VERSION ""

NS_ :

BS_:

BU_: Vector__XXX

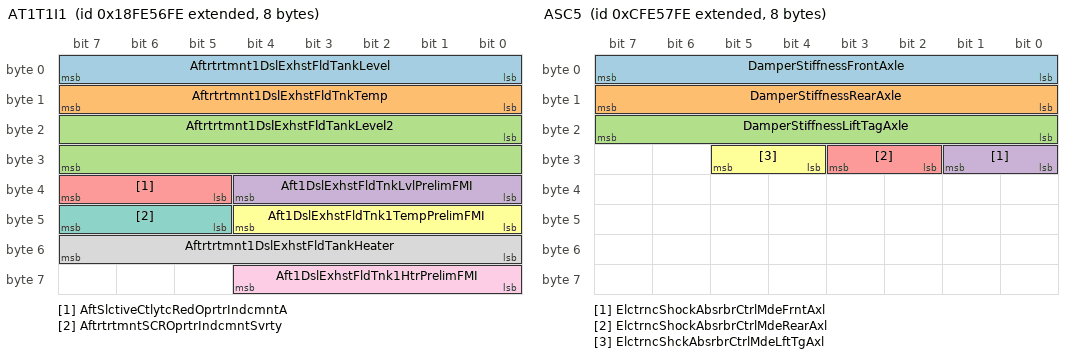
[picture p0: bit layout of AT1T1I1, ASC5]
BO_ 2566805246 AT1T1I1: 8 Vector__XXX
SG_ Aftrtrtmnt1DslExhstFldTankLevel : 0|8@1+ (0.4,0) [0|100] "%" Vector__XXX
SG_ Aftrtrtmnt1DslExhstFldTnkTemp : 8|8@1+ (1,-40) [-40|210] "deg C" Vector__XXX
SG_ Aftrtrtmnt1DslExhstFldTankLevel2 : 16|16@1+ (0.1,0) [0|6425.5] "mm" Vector__XXX
SG_ Aft1DslExhstFldTnkLvlPrelimFMI : 32|5@1+ (1,0) [0|31] "" Vector__XXX
SG_ AftSlctiveCtlytcRedOprtrIndcmntA : 37|3@1+ (1,0) [0|7] "" Vector__XXX
SG_ Aft1DslExhstFldTnk1TempPrelimFMI : 40|5@1+ (1,0) [0|31] "" Vector__XXX
SG_ AftrtrtmntSCROprtrIndcmntSvrty : 45|3@1+ (1,0) [0|7] "" Vector__XXX
SG_ Aftrtrtmnt1DslExhstFldTankHeater : 48|8@1+ (0.4,0) [0|100] "%" Vector__XXX
SG_ Aft1DslExhstFldTnk1HtrPrelimFMI : 56|5@1+ (1,0) [0|31] "" Vector__XXX

BO_ 2365478910 ASC5: 8 Vector__XXX
SG_ DamperStiffnessFrontAxle : 0|8@1+ (0.4,0) [0|100] "%" Vector__XXX
SG_ DamperStiffnessRearAxle : 8|8@1+ (0.4,0) [0|100] "%" Vector__XXX
SG_ DamperStiffnessLiftTagAxle : 16|8@1+ (0.4,0) [0|100] "%" Vector__XXX
SG_ ElctrncShockAbsrbrCtrlMdeFrntAxl : 24|2@1+ (1,0) [0|3] "" Vector__XXX
SG_ ElctrncShockAbsrbrCtrlMdeRearAxl : 26|2@1+ (1,0) [0|3] "" Vector__XXX
SG_ ElctrncShckAbsrbrCtrlMdeLftTgAxl : 28|2@1+ (1,0) [0|3] "" Vector__XXX

BO_ 2566805758 ASC4: 8 Vector__XXX
SG_ BellowPressureFrontAxleLeft : 0|16@1+ (0.1,0) [0|6425.5] "kPa" Vector__XXX
SG_ BellowPressureFrontAxleRight : 16|16@1+ (0.1,0) [0|6425.5] "kPa" Vector__XXX
SG_ BellowPressureRearAxleLeft : 32|16@1+ (0.1,0) [0|6425.5] "kPa" Vector__XXX
SG_ BellowPressureRearAxleRight : 48|16@1+ (0.1,0) [0|6425.5] "kPa" Vector__XXX

BO_ 2566806014 ASC3: 8 Vector__XXX
SG_ RelativeLevelFrontAxleLeft : 0|16@1+ (0.1,-3200) [-3200|3225.5] "mm" Vector__XXX
SG_ RelativeLevelFrontAxleRight : 16|16@1+ (0.1,-3200) [-3200|3225.5] "mm" Vector__XXX
SG_ RelativeLevelRearAxleLeft : 32|16@1+ (0.1,-3200) [-3200|3225.5] "mm" Vector__XXX
SG_ RelativeLevelRearAxleRight : 48|16@1+ (0.1,-3200) [-3200|3225.5] "mm" Vector__XXX

BO_ 2365479678 ASC1: 8 Vector__XXX
SG_ NominalLevelFrontAxle : 0|4@1+ (1,0) [0|15] "" Vector__XXX
SG_ NominalLevelRearAxle : 4|4@1+ (1,0) [0|15] "" Vector__XXX
SG_ BelowNominalLevelFrontAxle : 8|2@1+ (1,0) [0|3] "" Vector__XXX
SG_ BelowNominalLevelRearAxle : 10|2@1+ (1,0) [0|3] "" Vector__XXX
SG_ AboveNominalLevelFrontAxle : 12|2@1+ (1,0) [0|3] "" Vector__XXX
SG_ AboveNominalLevelRearAxle : 14|2@1+ (1,0) [0|3] "" Vector__XXX
SG_ LoweringControlModeFrontAxle : 16|2@1+ (1,0) [0|3] "" Vector__XXX
SG_ LoweringControlModeRearAxle : 18|2@1+ (1,0) [0|3] "" Vector__XXX
SG_ LiftingControlModeFrontAxle : 20|2@1+ (1,0) [0|3] "" Vector__XXX
SG_ LiftingControlModeRearAxle : 22|2@1+ (1,0) [0|3] "" Vector__XXX
SG_ KneelingInformation : 24|4@1+ (1,0) [0|15] "" Vector__XXX
SG_ LevelControlMode : 28|4@1+ (1,0) [0|15] "" Vector__XXX
SG_ SecurityDevice : 32|2@1+ (1,0) [0|3] "" Vector__XXX
SG_ VehicleMotionInhibit : 34|2@1+ (1,0) [0|3] "" Vector__XXX
SG_ DoorRelease : 36|2@1+ (1,0) [0|3] "" Vector__XXX
SG_ LiftAxle1Position : 38|2@1+ (1,0) [0|3] "" Vector__XXX
SG_ FrontAxleInBumperRange : 40|2@1+ (1,0) [0|3] "" Vector__XXX
SG_ RearAxleInBumperRange : 42|2@1+ (1,0) [0|3] "" Vector__XXX
SG_ LiftAxle2Position : 46|2@1+ (1,0) [0|3] "" Vector__XXX
SG_ SuspensionRemoteControl1 : 48|2@1+ (1,0) [0|3] "" Vector__XXX
SG_ SuspensionRemoteControl2 : 50|2@1+ (1,0) [0|3] "" Vector__XXX
SG_ AllowLevelCtrlDuringBrkngStatus : 52|2@1+ (1,0) [0|3] "" Vector__XXX
SG_ SpeedDependantLevelControlStatus : 54|2@1+ (1,0) [0|3] "" Vector__XXX
SG_ SuspensionCtrlRefusalInformation : 56|4@1+ (1,0) [0|15] "" Vector__XXX
SG_ MemoryLevel : 60|4@1+ (1,0) [0|15] "" Vector__XXX

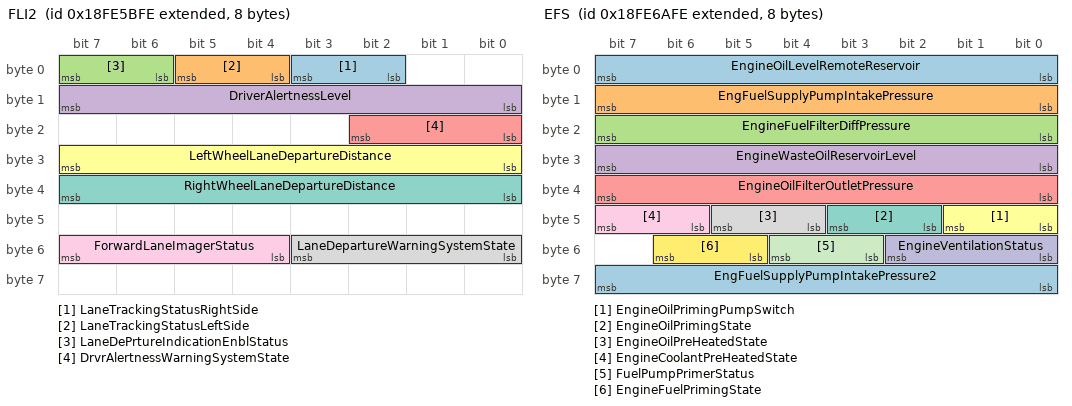
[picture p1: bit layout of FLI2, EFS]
BO_ 2566806526 FLI2: 8 Vector__XXX
SG_ LaneTrackingStatusRightSide : 2|2@1+ (1,0) [0|3] "" Vector__XXX
SG_ LaneTrackingStatusLeftSide : 4|2@1+ (1,0) [0|3] "" Vector__XXX
SG_ LaneDePrtureIndicationEnblStatus : 6|2@1+ (1,0) [0|3] "" Vector__XXX
SG_ DriverAlertnessLevel : 8|8@1+ (0.4,0) [0|100] "%" Vector__XXX
SG_ DrvrAlertnessWarningSystemState : 16|3@1+ (1,0) [0|7] "" Vector__XXX
SG_ LeftWheelLaneDepartureDistance : 24|8@1+ (1,-125) [-125|125] "cm" Vector__XXX
SG_ RightWheelLaneDepartureDistance : 32|8@1+ (1,-125) [-125|125] "cm" Vector__XXX
SG_ LaneDepartureWarningSystemState : 48|4@1+ (1,0) [0|15] "" Vector__XXX
SG_ ForwardLaneImagerStatus : 52|4@1+ (1,0) [0|15] "" Vector__XXX

BO_ 2566809342 BM: 8 Vector__XXX
SG_ BatteryMainSwitchHoldState : 0|2@1+ (1,0) [0|3] "" Vector__XXX

BO_ 2566809598 CCC: 8 Vector__XXX
SG_ AuxHeaterMaximumOutputPower : 0|16@1+ (2,0) [0|128510] "W" Vector__XXX

BO_ 2566809854 VF: 8 Vector__XXX
SG_ HydraulicTemperature : 0|8@1+ (1,-40) [-40|210] "deg C" Vector__XXX
SG_ HydrOilFilterRestrictionSwitch : 8|2@1+ (1,0) [0|3] "" Vector__XXX
SG_ WinchOilPressureSwitch : 10|2@1+ (1,0) [0|3] "" Vector__XXX
SG_ HydraulicOilLevel : 16|8@1+ (0.4,0) [0|100] "%" Vector__XXX

BO_ 2566810110 ET3: 8 Vector__XXX
SG_ EngineIntakeManifold1Temperature : 0|16@1+ (0.03125,-273) [-273|1734.96875] "deg C" Vector__XXX
SG_ EngineCoolantTemperature : 16|16@1+ (0.03125,-273) [-273|1734.96875] "deg C" Vector__XXX
SG_ EngIntkValveActSysOilTemperature : 32|16@1+ (0.03125,-273) [-273|1734.96875] "deg C" Vector__XXX
SG_ EngChargeAirCool1OtltTemperature : 48|16@1+ (0.03125,-273) [-273|1734.96875] "deg C" Vector__XXX

BO_ 2566810366 EFS: 8 Vector__XXX
SG_ EngineOilLevelRemoteReservoir : 0|8@1+ (0.4,0) [0|100] "%" Vector__XXX
SG_ EngFuelSupplyPumpIntakePressure : 8|8@1+ (2,0) [0|500] "kPa" Vector__XXX
SG_ EngineFuelFilterDiffPressure : 16|8@1+ (2,0) [0|500] "kPa" Vector__XXX
SG_ EngineWasteOilReservoirLevel : 24|8@1+ (0.4,0) [0|100] "%" Vector__XXX
SG_ EngineOilFilterOutletPressure : 32|8@1+ (4,0) [0|1000] "kPa" Vector__XXX
SG_ EngineOilPrimingPumpSwitch : 40|2@1+ (1,0) [0|3] "" Vector__XXX
SG_ EngineOilPrimingState : 42|2@1+ (1,0) [0|3] "" Vector__XXX
SG_ EngineOilPreHeatedState : 44|2@1+ (1,0) [0|3] "" Vector__XXX
SG_ EngineCoolantPreHeatedState : 46|2@1+ (1,0) [0|3] "" Vector__XXX
SG_ EngineVentilationStatus : 48|3@1+ (1,0) [0|7] "" Vector__XXX
SG_ FuelPumpPrimerStatus : 51|2@1+ (1,0) [0|3] "" Vector__XXX
SG_ EngineFuelPrimingState : 53|2@1+ (1,0) [0|3] "" Vector__XXX
SG_ EngFuelSupplyPumpIntakePressure2 : 56|8@1+ (2,0) [0|500] "kPa" Vector__XXX

BO_ 2566810622 DI: 1728 Vector__XXX
SG_ Driver1Identification : 7|13824@0+ (1,0) [0|0] "ASCII" Vector__XXX
SG_ Driver2Identification : 7|13824@0+ (1,0) [0|0] "ASCII" Vector__XXX

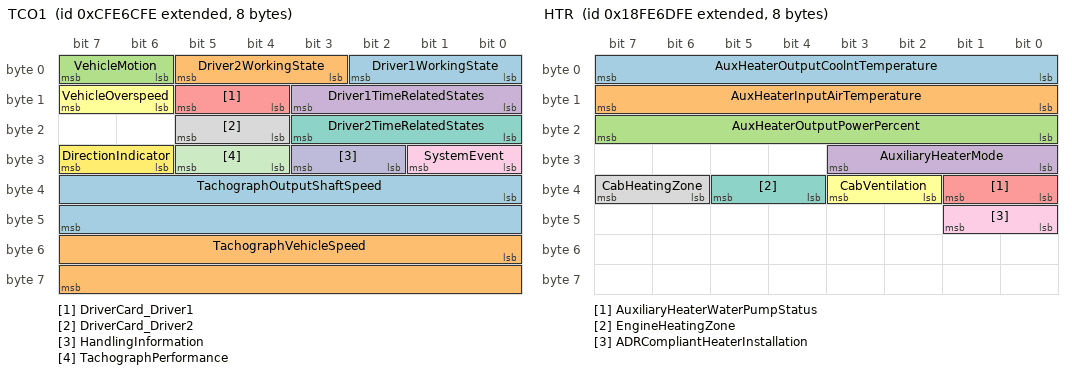
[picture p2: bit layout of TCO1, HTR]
BO_ 2365484286 TCO1: 8 Vector__XXX
SG_ Driver1WorkingState : 0|3@1+ (1,0) [0|7] "" Vector__XXX
SG_ Driver2WorkingState : 3|3@1+ (1,0) [0|7] "" Vector__XXX
SG_ VehicleMotion : 6|2@1+ (1,0) [0|3] "" Vector__XXX
SG_ Driver1TimeRelatedStates : 8|4@1+ (1,0) [0|15] "" Vector__XXX
SG_ DriverCard_Driver1 : 12|2@1+ (1,0) [0|3] "" Vector__XXX
SG_ VehicleOverspeed : 14|2@1+ (1,0) [0|3] "" Vector__XXX
SG_ Driver2TimeRelatedStates : 16|4@1+ (1,0) [0|15] "" Vector__XXX
SG_ DriverCard_Driver2 : 20|2@1+ (1,0) [0|3] "" Vector__XXX
SG_ SystemEvent : 24|2@1+ (1,0) [0|3] "" Vector__XXX
SG_ HandlingInformation : 26|2@1+ (1,0) [0|3] "" Vector__XXX
SG_ TachographPerformance : 28|2@1+ (1,0) [0|3] "" Vector__XXX
SG_ DirectionIndicator : 30|2@1+ (1,0) [0|3] "" Vector__XXX
SG_ TachographOutputShaftSpeed : 32|16@1+ (0.125,0) [0|8031.875] "rpm" Vector__XXX
SG_ TachographVehicleSpeed : 48|16@1+ (0.00390625,0) [0|250.996] "km/h" Vector__XXX

BO_ 2566811134 HTR: 8 Vector__XXX
SG_ AuxHeaterOutputCoolntTemperature : 0|8@1+ (1,-40) [-40|210] "deg C" Vector__XXX
SG_ AuxHeaterInputAirTemperature : 8|8@1+ (1,-40) [-40|210] "deg C" Vector__XXX
SG_ AuxHeaterOutputPowerPercent : 16|8@1+ (0.4,0) [0|100] "%" Vector__XXX
SG_ AuxiliaryHeaterMode : 24|4@1+ (1,0) [0|15] "" Vector__XXX
SG_ AuxiliaryHeaterWaterPumpStatus : 32|2@1+ (1,0) [0|3] "" Vector__XXX
SG_ CabVentilation : 34|2@1+ (1,0) [0|3] "" Vector__XXX
SG_ EngineHeatingZone : 36|2@1+ (1,0) [0|3] "" Vector__XXX
SG_ CabHeatingZone : 38|2@1+ (1,0) [0|3] "" Vector__XXX
SG_ ADRCompliantHeaterInstallation : 40|2@1+ (1,0) [0|3] "" Vector__XXX

BO_ 2298375934 HRW: 8 Vector__XXX
SG_ FrontAxle_LeftWheelSpeed : 0|16@1+ (0.00390625,0) [0|250.996] "km/h" Vector__XXX
SG_ FrontAxle_RightWheelSpeed : 16|16@1+ (0.00390625,0) [0|250.996] "km/h" Vector__XXX
SG_ RearAxle_LeftWheelSpeed : 32|16@1+ (0.00390625,0) [0|250.996] "km/h" Vector__XXX
SG_ RearAxle_RightWheelSpeed : 48|16@1+ (0.00390625,0) [0|250.996] "km/h" Vector__XXX

BO_ 2432593918 ACC1: 8 Vector__XXX
SG_ SpeedOfForwardVehicle : 0|8@1+ (1,0) [0|250] "km/h" Vector__XXX
SG_ DistanceToForwardVehicle : 8|8@1+ (1,0) [0|250] "m" Vector__XXX
SG_ AdaptiveCruiseControlSetSpeed : 16|8@1+ (1,0) [0|250] "km/h" Vector__XXX
SG_ AdaptiveCruiseControlMode : 24|3@1+ (1,0) [0|7] "" Vector__XXX
SG_ AdaptiveCruiseCtrlSetDistMode : 27|3@1+ (1,0) [0|7] "" Vector__XXX
SG_ RoadCurvature : 32|16@1+ (0.0078125,-250) [-250|251.992] "1/km" Vector__XXX
SG_ ACCTargetDetected : 48|2@1+ (1,0) [0|3] "" Vector__XXX
SG_ ACCSystemShutoffWarning : 50|2@1+ (1,0) [0|3] "" Vector__XXX
SG_ ACCDistanceAlertSignal : 52|2@1+ (1,0) [0|3] "" Vector__XXX
SG_ ForwardCollisionWarning : 54|2@1+ (1,0) [0|3] "" Vector__XXX

BO_ 2566811902 CVW: 8 Vector__XXX
SG_ PoweredVehicleWeight : 0|16@1+ (10,0) [0|642550] "kg" Vector__XXX
SG_ GrossCombinationVehicleWeight : 16|16@1+ (10,0) [0|642550] "kg" Vector__XXX

BO_ 2365485566 LTP: 8 Vector__XXX
SG_ LaserTracerTargetDeviation : 0|16@1+ (0.1,-3200) [-3200|3225.5] "mm" Vector__XXX
SG_ LaserTracerVerticalDistance : 16|16@1+ (0.1,0) [0|6425.5] "mm" Vector__XXX
SG_ LaserTracerHorizontalDeviation : 32|8@1+ (1,0) [0|250] "%" Vector__XXX
SG_ LEDDisplayData2 : 40|8@1+ (1,0) [0|255] "" Vector__XXX
SG_ LaserTracerInformation : 48|8@1+ (1,0) [0|255] "" Vector__XXX

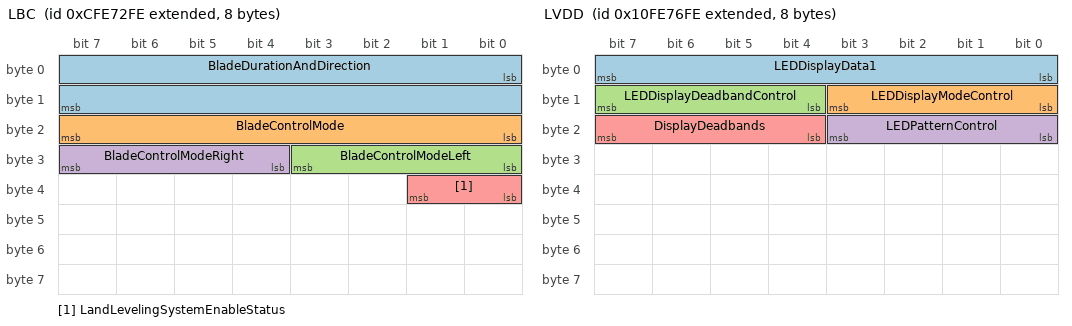
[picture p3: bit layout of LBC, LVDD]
BO_ 2365485822 LBC: 8 Vector__XXX
SG_ BladeDurationAndDirection : 0|16@1+ (0.1,-3276.8) [-3276.8|3148.7] "s" Vector__XXX
SG_ BladeControlMode : 16|8@1+ (1,0) [0|255] "" Vector__XXX
SG_ BladeControlModeLeft : 24|4@1+ (1,0) [0|15] "" Vector__XXX
SG_ BladeControlModeRight : 28|4@1+ (1,0) [0|15] "" Vector__XXX
SG_ LandLevelingSystemEnableStatus : 32|2@1+ (1,0) [0|3] "" Vector__XXX

BO_ 2365486078 LMP: 8 Vector__XXX
SG_ MastPosition : 0|16@1+ (0.1,-3200) [-3200|3225.5] "mm" Vector__XXX

BO_ 2365486334 LSP: 8 Vector__XXX
SG_ ModifyLevelingSystemSetPoint : 0|16@1+ (0.1,-3200) [-3200|3225.5] "mm" Vector__XXX
SG_ BladeHeightSetPoint : 16|32@1+ (1E-007,-209.7152) [-209.7152|211.3929215] "m" Vector__XXX

BO_ 2365486590 LVD: 8 Vector__XXX
SG_ LaserStrikeVerticalDeviation : 0|16@1+ (0.1,-3200) [-3200|3225.5] "mm" Vector__XXX
SG_ LaserReceiverType : 16|8@1+ (1,0) [0|250] "" Vector__XXX
SG_ LaserStrikeDataLatency : 24|16@1+ (5.12E-005,0) [0|3.289856] "s" Vector__XXX
SG_ AbsoluteLaserStrikePosition : 40|16@1+ (0.1,0) [0|6425.5] "mm" Vector__XXX

BO_ 2432595710 LVDD: 8 Vector__XXX
SG_ LEDDisplayData1 : 0|8@1+ (1,0) [0|255] "" Vector__XXX
SG_ LEDDisplayModeControl : 8|4@1+ (1,0) [0|15] "" Vector__XXX
SG_ LEDDisplayDeadbandControl : 12|4@1+ (1,0) [0|15] "" Vector__XXX
SG_ LEDPatternControl : 16|4@1+ (1,0) [0|15] "" Vector__XXX
SG_ DisplayDeadbands : 20|4@1+ (1,0) [0|15] "" Vector__XXX

BO_ 2633922558 AP: 8 Vector__XXX
SG_ AuxiliaryVacuumPressureReading : 0|16@1+ (0.5,0) [0|32127.5] "kPa" Vector__XXX
SG_ AuxiliaryGagePressureReading1 : 16|16@1+ (0.5,0) [0|32127.5] "kPa" Vector__XXX
SG_ AuxiliaryAbsolutePressureReading : 32|16@1+ (0.5,0) [0|32127.5] "kPa" Vector__XXX

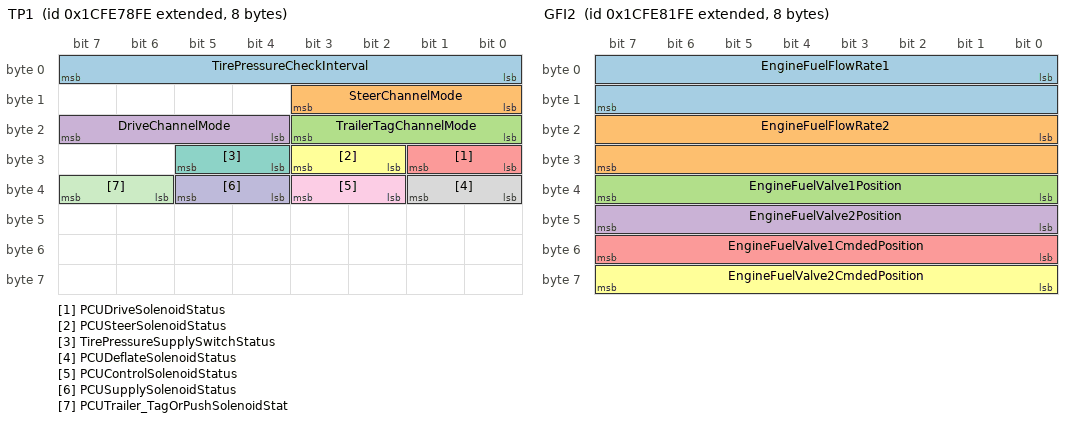
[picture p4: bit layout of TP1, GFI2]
BO_ 2633922814 TP1: 8 Vector__XXX
SG_ TirePressureCheckInterval : 0|8@1+ (1,0) [0|250] "min" Vector__XXX
SG_ SteerChannelMode : 8|4@1+ (1,0) [0|15] "" Vector__XXX
SG_ TrailerTagChannelMode : 16|4@1+ (1,0) [0|15] "" Vector__XXX
SG_ DriveChannelMode : 20|4@1+ (1,0) [0|15] "" Vector__XXX
SG_ PCUDriveSolenoidStatus : 24|2@1+ (1,0) [0|3] "" Vector__XXX
SG_ PCUSteerSolenoidStatus : 26|2@1+ (1,0) [0|3] "" Vector__XXX
SG_ TirePressureSupplySwitchStatus : 28|2@1+ (1,0) [0|3] "" Vector__XXX
SG_ PCUDeflateSolenoidStatus : 32|2@1+ (1,0) [0|3] "" Vector__XXX
SG_ PCUControlSolenoidStatus : 34|2@1+ (1,0) [0|3] "" Vector__XXX
SG_ PCUSupplySolenoidStatus : 36|2@1+ (1,0) [0|3] "" Vector__XXX
SG_ PCUTrailer_TagOrPushSolenoidStat : 38|2@1+ (1,0) [0|3] "" Vector__XXX

BO_ 2633923070 TP2: 8 Vector__XXX
SG_ Trlr_TgOrPushChnnlTirePrsTarget : 0|16@1+ (0.5,0) [0|32127.5] "kPa" Vector__XXX
SG_ DriveChannelTirePressureTarget : 16|16@1+ (0.5,0) [0|32127.5] "kPa" Vector__XXX
SG_ SteerChannelTirePressureTarget : 32|16@1+ (0.5,0) [0|32127.5] "kPa" Vector__XXX

BO_ 2633923326 TP3: 8 Vector__XXX
SG_ Trailer_TagOrPushChnnlTirePress : 0|16@1+ (0.5,0) [0|32127.5] "kPa" Vector__XXX
SG_ DriveChannelTirePressure : 16|16@1+ (0.5,0) [0|32127.5] "kPa" Vector__XXX
SG_ SteerChannelTirePressure : 32|16@1+ (0.5,0) [0|32127.5] "kPa" Vector__XXX

BO_ 2633923582 CT1: 8 Vector__XXX
SG_ EngineCylinder1CombustionTime : 0|16@1+ (0.01,0) [0|642.55] "ms" Vector__XXX
SG_ EngineCylinder2CombustionTime : 16|16@1+ (0.01,0) [0|642.55] "ms" Vector__XXX
SG_ EngineCylinder3CombustionTime : 32|16@1+ (0.01,0) [0|642.55] "ms" Vector__XXX
SG_ EngineCylinder4CombustionTime : 48|16@1+ (0.01,0) [0|642.55] "ms" Vector__XXX

BO_ 2633923838 CT2: 8 Vector__XXX
SG_ EngineCylinder5CombustionTime : 0|16@1+ (0.01,0) [0|642.55] "ms" Vector__XXX
SG_ EngineCylinder6CombustionTime : 16|16@1+ (0.01,0) [0|642.55] "ms" Vector__XXX
SG_ EngineCylinder7CombustionTime : 32|16@1+ (0.01,0) [0|642.55] "ms" Vector__XXX
SG_ EngineCylinder8CombustionTime : 48|16@1+ (0.01,0) [0|642.55] "ms" Vector__XXX

BO_ 2633924094 CT3: 8 Vector__XXX
SG_ EngineCylinder9CombustionTime : 0|16@1+ (0.01,0) [0|642.55] "ms" Vector__XXX
SG_ EngineCylinder10CombustionTime : 16|16@1+ (0.01,0) [0|642.55] "ms" Vector__XXX
SG_ EngineCylinder11CombustionTime : 32|16@1+ (0.01,0) [0|642.55] "ms" Vector__XXX
SG_ EngineCylinder12CombustionTime : 48|16@1+ (0.01,0) [0|642.55] "ms" Vector__XXX

BO_ 2633924350 CT4: 8 Vector__XXX
SG_ EngineCylinder13CombustionTime : 0|16@1+ (0.01,0) [0|642.55] "ms" Vector__XXX
SG_ EngineCylinder14CombustionTime : 16|16@1+ (0.01,0) [0|642.55] "ms" Vector__XXX
SG_ EngineCylinder15CombustionTime : 32|16@1+ (0.01,0) [0|642.55] "ms" Vector__XXX
SG_ EngineCylinder16CombustionTime : 48|16@1+ (0.01,0) [0|642.55] "ms" Vector__XXX

BO_ 2633924606 CT5: 8 Vector__XXX
SG_ EngineCylinder17CombustionTime : 0|16@1+ (0.01,0) [0|642.55] "ms" Vector__XXX
SG_ EngineCylinder18CombustionTime : 16|16@1+ (0.01,0) [0|642.55] "ms" Vector__XXX
SG_ EngineCylinder19CombustionTime : 32|16@1+ (0.01,0) [0|642.55] "ms" Vector__XXX
SG_ EngineCylinder20CombustionTime : 48|16@1+ (0.01,0) [0|642.55] "ms" Vector__XXX

BO_ 2633924862 CT6: 8 Vector__XXX
SG_ EngineDesiredCombustionTime : 0|16@1+ (0.01,0) [0|642.55] "ms" Vector__XXX
SG_ EngineAverageCombustionTime : 16|16@1+ (0.01,0) [0|642.55] "ms" Vector__XXX

BO_ 2633925118 GFI2: 8 Vector__XXX
SG_ EngineFuelFlowRate1 : 0|16@1+ (0.1,0) [0|6425.5] "m^3/h" Vector__XXX
SG_ EngineFuelFlowRate2 : 16|16@1+ (0.1,0) [0|6425.5] "m^3/h" Vector__XXX
SG_ EngineFuelValve1Position : 32|8@1+ (0.4,0) [0|100] "%" Vector__XXX
SG_ EngineFuelValve2Position : 40|8@1+ (0.4,0) [0|100] "%" Vector__XXX
SG_ EngineFuelValve1CmdedPosition : 48|8@1+ (0.4,0) [0|100] "%" Vector__XXX
SG_ EngineFuelValve2CmdedPosition : 56|8@1+ (0.4,0) [0|100] "%" Vector__XXX

BO_ 2633925374 IT1: 8 Vector__XXX
SG_ EngineCylinder1IgnitionTiming : 0|16@1+ (0.0078125,-200) [-200|301.99] "deg" Vector__XXX
SG_ EngineCylinder2IgnitionTiming : 16|16@1+ (0.0078125,-200) [-200|301.99] "deg" Vector__XXX
SG_ EngineCylinder3IgnitionTiming : 32|16@1+ (0.0078125,-200) [-200|301.99] "deg" Vector__XXX
SG_ EngineCylinder4IgnitionTiming : 48|16@1+ (0.0078125,-200) [-200|301.99] "deg" Vector__XXX

BO_ 2633925630 IT2: 8 Vector__XXX
SG_ EngineCylinder5IgnitionTiming : 0|16@1+ (0.0078125,-200) [-200|301.99] "deg" Vector__XXX
SG_ EngineCylinder6IgnitionTiming : 16|16@1+ (0.0078125,-200) [-200|301.99] "deg" Vector__XXX
SG_ EngineCylinder7IgnitionTiming : 32|16@1+ (0.0078125,-200) [-200|301.99] "deg" Vector__XXX
SG_ EngineCylinder8IgnitionTiming : 48|16@1+ (0.0078125,-200) [-200|301.99] "deg" Vector__XXX

BO_ 2633925886 IT3: 8 Vector__XXX
SG_ EngineCylinder9IgnitionTiming : 0|16@1+ (0.0078125,-200) [-200|301.99] "deg" Vector__XXX
SG_ EngineCylinder10IgnitionTiming : 16|16@1+ (0.0078125,-200) [-200|301.99] "deg" Vector__XXX
SG_ EngineCylinder11IgnitionTiming : 32|16@1+ (0.0078125,-200) [-200|301.99] "deg" Vector__XXX
SG_ EngineCylinder12IgnitionTiming : 48|16@1+ (0.0078125,-200) [-200|301.99] "deg" Vector__XXX

BO_ 2633926142 IT4: 8 Vector__XXX
SG_ EngineCylinder13IgnitionTiming : 0|16@1+ (0.0078125,-200) [-200|301.99] "deg" Vector__XXX
SG_ EngineCylinder14IgnitionTiming : 16|16@1+ (0.0078125,-200) [-200|301.99] "deg" Vector__XXX
SG_ EngineCylinder15IgnitionTiming : 32|16@1+ (0.0078125,-200) [-200|301.99] "deg" Vector__XXX
SG_ EngineCylinder16IgnitionTiming : 48|16@1+ (0.0078125,-200) [-200|301.99] "deg" Vector__XXX

BO_ 2633926398 IT5: 8 Vector__XXX
SG_ EngineCylinder17IgnitionTiming : 0|16@1+ (0.0078125,-200) [-200|301.99] "deg" Vector__XXX
SG_ EngineCylinder18IgnitionTiming : 16|16@1+ (0.0078125,-200) [-200|301.99] "deg" Vector__XXX
SG_ EngineCylinder19IgnitionTiming : 32|16@1+ (0.0078125,-200) [-200|301.99] "deg" Vector__XXX
SG_ EngineCylinder20IgnitionTiming : 48|16@1+ (0.0078125,-200) [-200|301.99] "deg" Vector__XXX

BO_ 2633926654 IT6: 8 Vector__XXX
SG_ EngineDesiredIgnitionTiming1 : 0|16@1+ (0.0078125,-200) [-200|301.99] "deg" Vector__XXX
SG_ EngineDesiredIgnitionTiming2 : 16|16@1+ (0.0078125,-200) [-200|301.99] "deg" Vector__XXX
SG_ EngineDesiredIgnitionTiming3 : 32|16@1+ (0.0078125,-200) [-200|301.99] "deg" Vector__XXX
SG_ EngineActualIgnitionTiming : 48|16@1+ (0.0078125,-200) [-200|301.99] "deg" Vector__XXX

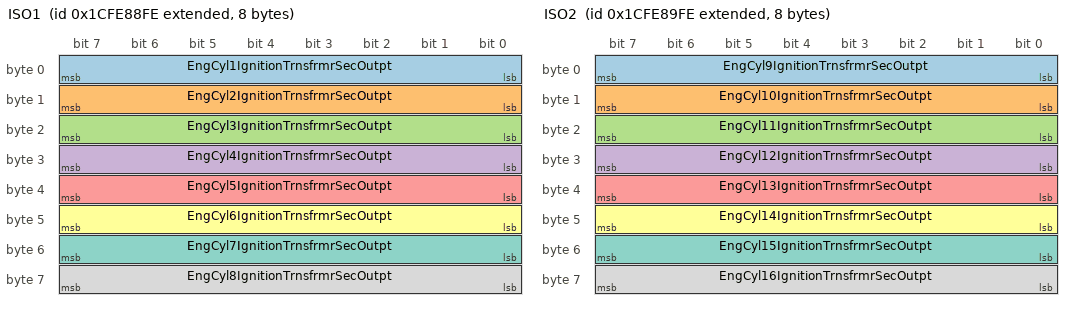
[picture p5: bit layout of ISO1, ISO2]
BO_ 2633926910 ISO1: 8 Vector__XXX
SG_ EngCyl1IgnitionTrnsfrmrSecOutpt : 0|8@1+ (1,-125) [-125|125] "%" Vector__XXX
SG_ EngCyl2IgnitionTrnsfrmrSecOutpt : 8|8@1+ (1,-125) [-125|125] "%" Vector__XXX
SG_ EngCyl3IgnitionTrnsfrmrSecOutpt : 16|8@1+ (1,-125) [-125|125] "%" Vector__XXX
SG_ EngCyl4IgnitionTrnsfrmrSecOutpt : 24|8@1+ (1,-125) [-125|125] "%" Vector__XXX
SG_ EngCyl5IgnitionTrnsfrmrSecOutpt : 32|8@1+ (1,-125) [-125|125] "%" Vector__XXX
SG_ EngCyl6IgnitionTrnsfrmrSecOutpt : 40|8@1+ (1,-125) [-125|125] "%" Vector__XXX
SG_ EngCyl7IgnitionTrnsfrmrSecOutpt : 48|8@1+ (1,-125) [-125|125] "%" Vector__XXX
SG_ EngCyl8IgnitionTrnsfrmrSecOutpt : 56|8@1+ (1,-125) [-125|125] "%" Vector__XXX

BO_ 2633927166 ISO2: 8 Vector__XXX
SG_ EngCyl9IgnitionTrnsfrmrSecOutpt : 0|8@1+ (1,-125) [-125|125] "%" Vector__XXX
SG_ EngCyl10IgnitionTrnsfrmrSecOutpt : 8|8@1+ (1,-125) [-125|125] "%" Vector__XXX
SG_ EngCyl11IgnitionTrnsfrmrSecOutpt : 16|8@1+ (1,-125) [-125|125] "%" Vector__XXX
SG_ EngCyl12IgnitionTrnsfrmrSecOutpt : 24|8@1+ (1,-125) [-125|125] "%" Vector__XXX
SG_ EngCyl13IgnitionTrnsfrmrSecOutpt : 32|8@1+ (1,-125) [-125|125] "%" Vector__XXX
SG_ EngCyl14IgnitionTrnsfrmrSecOutpt : 40|8@1+ (1,-125) [-125|125] "%" Vector__XXX
SG_ EngCyl15IgnitionTrnsfrmrSecOutpt : 48|8@1+ (1,-125) [-125|125] "%" Vector__XXX
SG_ EngCyl16IgnitionTrnsfrmrSecOutpt : 56|8@1+ (1,-125) [-125|125] "%" Vector__XXX

BO_ 2633927422 ISO3: 8 Vector__XXX
SG_ EngCyl17IgnitionTrnsfrmrSecOutpt : 0|8@1+ (1,-125) [-125|125] "%" Vector__XXX
SG_ EngCyl18IgnitionTrnsfrmrSecOutpt : 8|8@1+ (1,-125) [-125|125] "%" Vector__XXX
SG_ EngCyl19IgnitionTrnsfrmrSecOutpt : 16|8@1+ (1,-125) [-125|125] "%" Vector__XXX
SG_ EngCyl20IgnitionTrnsfrmrSecOutpt : 24|8@1+ (1,-125) [-125|125] "%" Vector__XXX

BO_ 2633927678 GFP1: 8 Vector__XXX
SG_ EngFuelValve1IntakeAbsPressure : 0|16@1+ (0.1,0) [0|6425.5] "kPa" Vector__XXX
SG_ EngineFuelValve1DiffPressure : 16|16@1+ (0.1,0) [0|6425.5] "kPa" Vector__XXX
SG_ EngineAirToFuelDiffPressure : 32|16@1+ (0.1,0) [0|6425.5] "kPa" Vector__XXX
SG_ EngFuelValve1OutletAbsPressure : 48|16@1+ (0.1,0) [0|6425.5] "kPa" Vector__XXX

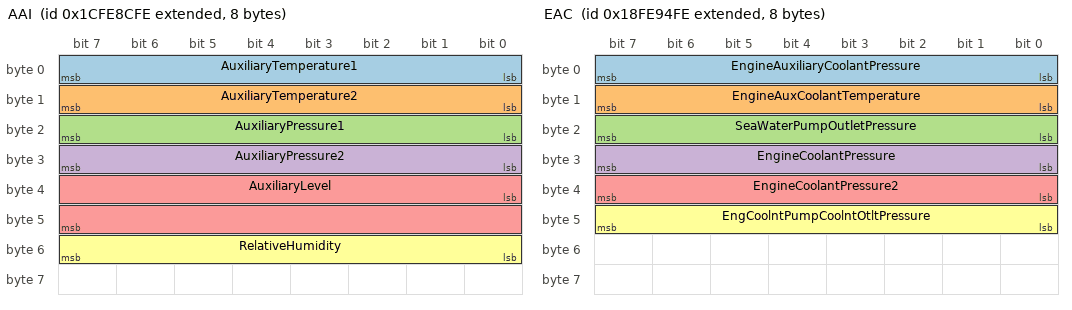
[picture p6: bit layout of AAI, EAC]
BO_ 2633927934 AAI: 8 Vector__XXX
SG_ AuxiliaryTemperature1 : 0|8@1+ (1,-40) [-40|210] "deg C" Vector__XXX
SG_ AuxiliaryTemperature2 : 8|8@1+ (1,-40) [-40|210] "deg C" Vector__XXX
SG_ AuxiliaryPressure1 : 16|8@1+ (16,0) [0|4000] "kPa" Vector__XXX
SG_ AuxiliaryPressure2 : 24|8@1+ (16,0) [0|4000] "kPa" Vector__XXX
SG_ AuxiliaryLevel : 32|16@1+ (0.1,0) [0|6425.5] "mm" Vector__XXX
SG_ RelativeHumidity : 48|8@1+ (0.4,0) [0|100] "%" Vector__XXX

BO_ 2566819326 VEP2: 8 Vector__XXX
SG_ BatteryPotentialPowerInput2 : 0|16@1+ (0.05,0) [0|3212.75] "V" Vector__XXX
SG_ ECUPowerOutputSupplyVoltage1 : 16|16@1+ (0.05,0) [0|3212.75] "V" Vector__XXX
SG_ ECUPowerOutputSupplyVoltage2 : 32|16@1+ (0.05,0) [0|3212.75] "V" Vector__XXX
SG_ ECUPowerOutputSupplyVoltage3 : 48|16@1+ (0.05,0) [0|3212.75] "V" Vector__XXX

BO_ 2633928446 S2: 8 Vector__XXX
SG_ ServiceComponentIdentification : 0|8@1+ (1,0) [0|250] "" Vector__XXX
SG_ TimeSinceLastService : 8|16@1+ (1,-32127) [-32127|32128] "h" Vector__XXX

BO_ 2566819838 SP2: 8 Vector__XXX
SG_ EngExtShutdownAirSupplyPressure : 0|16@1+ (0.5,0) [0|32127.5] "kPa" Vector__XXX

BO_ 2566820094 ETH: 33 Vector__XXX
SG_ NumberOfEngTorqueHistoryRecords : 0|8@1+ (1,0) [0|250] "records" Vector__XXX
SG_ EnginePower : 8|16@1+ (0.5,0) [0|32127.5] "kW" Vector__XXX
SG_ EnginePeakTorque1 : 24|16@1+ (1,0) [0|64255] "Nm" Vector__XXX
SG_ EnginePeakTorque2 : 40|16@1+ (1,0) [0|64255] "Nm" Vector__XXX
SG_ CalibrationRecordStartMonth : 56|8@1+ (1,0) [0|250] "Months" Vector__XXX
SG_ CalibrationRecordStartDay : 64|8@1+ (0.25,0) [0|62.5] "Days" Vector__XXX
SG_ CalibrationRecordStartYear : 72|8@1+ (1,1985) [1985|2235] "Years" Vector__XXX
SG_ CalibrationRecordDurationTime : 80|32@1+ (0.05,0) [0|210554060.75] "h" Vector__XXX
SG_ TorqueLimitingFeatureStatus : 112|2@1+ (1,0) [0|3] "" Vector__XXX
SG_ EngineTorqueLimitFeature : 114|3@1+ (1,0) [0|7] "" Vector__XXX
SG_ TransmissionGearRatio1 : 120|16@1+ (0.01,0) [0|642.55] "" Vector__XXX
SG_ EngineTorqueLimit1_Transmission : 136|16@1+ (1,0) [0|64255] "Nm" Vector__XXX
SG_ TransmissionGearRatio2 : 152|16@1+ (0.01,0) [0|642.55] "" Vector__XXX
SG_ EngineTorqueLimit2_Transmission : 168|16@1+ (1,0) [0|64255] "Nm" Vector__XXX
SG_ TransmissionGearRatio3 : 184|16@1+ (0.01,0) [0|642.55] "" Vector__XXX
SG_ EngineTorqueLimit3_Transmission : 200|16@1+ (1,0) [0|64255] "Nm" Vector__XXX
SG_ EngineTorqueLimit4_Transmission : 216|16@1+ (1,0) [0|64255] "Nm" Vector__XXX
SG_ EngineTorqueLimit5_Switch : 232|16@1+ (1,0) [0|64255] "Nm" Vector__XXX
SG_ EngineTorqueLimit6_AxleInput : 248|16@1+ (2,0) [0|128510] "Nm" Vector__XXX

BO_ 2633929214 FL: 8 Vector__XXX
SG_ EngineFuelLeakage1 : 0|2@1+ (1,0) [0|3] "" Vector__XXX
SG_ EngineFuelLeakage2 : 2|2@1+ (1,0) [0|3] "" Vector__XXX
SG_ EngineFluidBundLevel : 8|8@1+ (0.4,0) [0|100] "%" Vector__XXX

BO_ 2633929470 EI1: 8 Vector__XXX
SG_ EnginePreFilterOilPressure : 0|8@1+ (4,0) [0|1000] "kPa" Vector__XXX
SG_ EngineExhaustPressure1 : 8|16@1+ (0.0078125,-250) [-250|251.99] "kPa" Vector__XXX
SG_ EngineFuelRackPosition : 24|8@1+ (0.4,0) [0|100] "%" Vector__XXX
SG_ EngineFuelSystem1GasMassFlowRate : 32|16@1+ (0.05,0) [0|3212.75] "kg/h" Vector__XXX
SG_ InstantaneousEstimatedBrakePower : 48|16@1+ (0.5,0) [0|32127.5] "kW" Vector__XXX

BO_ 2633929726 EES: 8 Vector__XXX
SG_ ElectricalLoad : 0|16@1+ (0.5,0) [0|32127.5] "kW" Vector__XXX
SG_ SafetyWireStatus : 16|2@1+ (1,0) [0|3] "" Vector__XXX
SG_ EngineTurningGearEngaged : 18|2@1+ (1,0) [0|3] "" Vector__XXX

BO_ 2566821118 EAC: 8 Vector__XXX
SG_ EngineAuxiliaryCoolantPressure : 0|8@1+ (4,0) [0|1000] "kPa" Vector__XXX
SG_ EngineAuxCoolantTemperature : 8|8@1+ (1,-40) [-40|210] "deg C" Vector__XXX
SG_ SeaWaterPumpOutletPressure : 16|8@1+ (2,0) [0|500] "kPa" Vector__XXX
SG_ EngineCoolantPressure : 24|8@1+ (4,0) [0|1000] "kPa" Vector__XXX
SG_ EngineCoolantPressure2 : 32|8@1+ (4,0) [0|1000] "kPa" Vector__XXX
SG_ EngCoolntPumpCoolntOtltPressure : 40|8@1+ (2,0) [0|500] "kPa" Vector__XXX

BO_ 2633930238 RBI: 8 Vector__XXX
SG_ EngineOperationTimeSinceRebuild : 0|32@1+ (1,0) [0|4211081215] "s" Vector__XXX

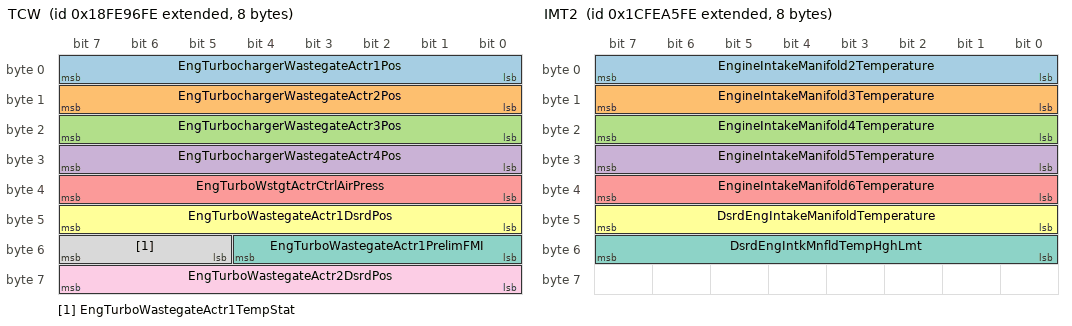
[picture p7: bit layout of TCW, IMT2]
BO_ 2566821630 TCW: 8 Vector__XXX
SG_ EngTurbochargerWastegateActr1Pos : 0|8@1+ (0.4,0) [0|100] "%" Vector__XXX
SG_ EngTurbochargerWastegateActr2Pos : 8|8@1+ (0.4,0) [0|100] "%" Vector__XXX
SG_ EngTurbochargerWastegateActr3Pos : 16|8@1+ (0.4,0) [0|100] "%" Vector__XXX
SG_ EngTurbochargerWastegateActr4Pos : 24|8@1+ (0.4,0) [0|100] "%" Vector__XXX
SG_ EngTurboWstgtActrCtrlAirPress : 32|8@1+ (4,0) [0|1000] "kPa" Vector__XXX
SG_ EngTurboWastegateActr1DsrdPos : 40|8@1+ (0.4,0) [0|100] "%" Vector__XXX
SG_ EngTurboWastegateActr1PrelimFMI : 48|5@1+ (1,0) [0|31] "" Vector__XXX
SG_ EngTurboWastegateActr1TempStat : 53|3@1+ (1,0) [0|7] "" Vector__XXX
SG_ EngTurboWastegateActr2DsrdPos : 56|8@1+ (0.4,0) [0|100] "%" Vector__XXX

BO_ 2566821886 TCI5: 8 Vector__XXX
SG_ EngTurbocharger1TurbineOtltTemp : 0|16@1+ (0.03125,-273) [-273|1734.96875] "deg C" Vector__XXX
SG_ EngTurbocharger2TurbineOtltTemp : 16|16@1+ (0.03125,-273) [-273|1734.96875] "deg C" Vector__XXX
SG_ EngTurbocharger3TurbineOtltTemp : 32|16@1+ (0.03125,-273) [-273|1734.96875] "deg C" Vector__XXX
SG_ EngTurbocharger4TurbineOtltTemp : 48|16@1+ (0.03125,-273) [-273|1734.96875] "deg C" Vector__XXX

BO_ 2566822142 TCI4: 8 Vector__XXX
SG_ EngTurbocharger1TurbineIntkTemp : 0|16@1+ (0.03125,-273) [-273|1734.96875] "deg C" Vector__XXX
SG_ EngTurbocharger2TurbineIntkTemp : 16|16@1+ (0.03125,-273) [-273|1734.96875] "deg C" Vector__XXX
SG_ EngTurbocharger3TurbineIntkTemp : 32|16@1+ (0.03125,-273) [-273|1734.96875] "deg C" Vector__XXX
SG_ EngTurbocharger4TurbineIntkTemp : 48|16@1+ (0.03125,-273) [-273|1734.96875] "deg C" Vector__XXX

BO_ 2566822398 TCI3: 8 Vector__XXX
SG_ EngTurbo1CmprssorIntkPress : 0|16@1+ (0.0078125,-250) [-250|251.99] "kPa" Vector__XXX
SG_ EngTurbo2CmprssorIntkPress : 16|16@1+ (0.0078125,-250) [-250|251.99] "kPa" Vector__XXX
SG_ EngTurbo3CmprssorIntkPress : 32|16@1+ (0.0078125,-250) [-250|251.99] "kPa" Vector__XXX
SG_ EngTurbo4CmprssorIntkPress : 48|16@1+ (0.0078125,-250) [-250|251.99] "kPa" Vector__XXX

BO_ 2566822654 TCI2: 8 Vector__XXX
SG_ EngTurbocharger1CmprssorIntkTemp : 0|16@1+ (0.03125,-273) [-273|1734.96875] "deg C" Vector__XXX
SG_ EngTurbocharger2CmprssorIntkTemp : 16|16@1+ (0.03125,-273) [-273|1734.96875] "deg C" Vector__XXX
SG_ EngTurbocharger3CmprssorIntkTemp : 32|16@1+ (0.03125,-273) [-273|1734.96875] "deg C" Vector__XXX
SG_ EngTurbocharger4CmprssorIntkTemp : 48|16@1+ (0.03125,-273) [-273|1734.96875] "deg C" Vector__XXX

BO_ 2633931774 TCI1: 8 Vector__XXX
SG_ EngTurbochargerLubeOilPressure2 : 0|8@1+ (4,0) [0|1000] "kPa" Vector__XXX
SG_ EngineTurbocharger2Speed : 8|16@1+ (4,0) [0|257020] "rpm" Vector__XXX
SG_ EngineTurbocharger3Speed : 24|16@1+ (4,0) [0|257020] "rpm" Vector__XXX
SG_ EngineTurbocharger4Speed : 40|16@1+ (4,0) [0|257020] "rpm" Vector__XXX

BO_ 2566823166 MBT3: 8 Vector__XXX
SG_ EngineMainBearing9Temperature : 0|16@1+ (0.03125,-273) [-273|1734.96875] "deg C" Vector__XXX
SG_ EngineMainBearing10Temperature : 16|16@1+ (0.03125,-273) [-273|1734.96875] "deg C" Vector__XXX
SG_ EngineMainBearing11Temperature : 32|16@1+ (0.03125,-273) [-273|1734.96875] "deg C" Vector__XXX
SG_ EngineMainBearing12Temperature : 48|16@1+ (0.03125,-273) [-273|1734.96875] "deg C" Vector__XXX

BO_ 2566823422 MBT2: 8 Vector__XXX
SG_ EngineMainBearing5Temperature : 0|16@1+ (0.03125,-273) [-273|1734.96875] "deg C" Vector__XXX
SG_ EngineMainBearing6Temperature : 16|16@1+ (0.03125,-273) [-273|1734.96875] "deg C" Vector__XXX
SG_ EngineMainBearing7Temperature : 32|16@1+ (0.03125,-273) [-273|1734.96875] "deg C" Vector__XXX
SG_ EngineMainBearing8Temperature : 48|16@1+ (0.03125,-273) [-273|1734.96875] "deg C" Vector__XXX

BO_ 2566823678 MBT1: 8 Vector__XXX
SG_ EngineMainBearing1Temperature : 0|16@1+ (0.03125,-273) [-273|1734.96875] "deg C" Vector__XXX
SG_ EngineMainBearing2Temperature : 16|16@1+ (0.03125,-273) [-273|1734.96875] "deg C" Vector__XXX
SG_ EngineMainBearing3Temperature : 32|16@1+ (0.03125,-273) [-273|1734.96875] "deg C" Vector__XXX
SG_ EngineMainBearing4Temperature : 48|16@1+ (0.03125,-273) [-273|1734.96875] "deg C" Vector__XXX

BO_ 2633932798 EPT5: 8 Vector__XXX
SG_ EngExhaustGasPort17Temperature : 0|16@1+ (0.03125,-273) [-273|1734.96875] "deg C" Vector__XXX
SG_ EngExhaustGasPort18Temperature : 16|16@1+ (0.03125,-273) [-273|1734.96875] "deg C" Vector__XXX
SG_ EngExhaustGasPort19Temperature : 32|16@1+ (0.03125,-273) [-273|1734.96875] "deg C" Vector__XXX
SG_ EngExhaustGasPort20Temperature : 48|16@1+ (0.03125,-273) [-273|1734.96875] "deg C" Vector__XXX

BO_ 2566824190 EPT4: 8 Vector__XXX
SG_ EngExhaustGasPort13Temperature : 0|16@1+ (0.03125,-273) [-273|1734.96875] "deg C" Vector__XXX
SG_ EngExhaustGasPort14Temperature : 16|16@1+ (0.03125,-273) [-273|1734.96875] "deg C" Vector__XXX
SG_ EngExhaustGasPort15Temperature : 32|16@1+ (0.03125,-273) [-273|1734.96875] "deg C" Vector__XXX
SG_ EngExhaustGasPort16Temperature : 48|16@1+ (0.03125,-273) [-273|1734.96875] "deg C" Vector__XXX

BO_ 2633933310 EPT3: 8 Vector__XXX
SG_ EngineExhaustGasPort9Temperature : 0|16@1+ (0.03125,-273) [-273|1734.96875] "deg C" Vector__XXX
SG_ EngExhaustGasPort10Temperature : 16|16@1+ (0.03125,-273) [-273|1734.96875] "deg C" Vector__XXX
SG_ EngExhaustGasPort11Temperature : 32|16@1+ (0.03125,-273) [-273|1734.96875] "deg C" Vector__XXX
SG_ EngExhaustGasPort12Temperature : 48|16@1+ (0.03125,-273) [-273|1734.96875] "deg C" Vector__XXX

BO_ 2633933566 EPT2: 8 Vector__XXX
SG_ EngineExhaustGasPort5Temperature : 0|16@1+ (0.03125,-273) [-273|1734.96875] "deg C" Vector__XXX
SG_ EngineExhaustGasPort6Temperature : 16|16@1+ (0.03125,-273) [-273|1734.96875] "deg C" Vector__XXX
SG_ EngineExhaustGasPort7Temperature : 32|16@1+ (0.03125,-273) [-273|1734.96875] "deg C" Vector__XXX
SG_ EngineExhaustGasPort8Temperature : 48|16@1+ (0.03125,-273) [-273|1734.96875] "deg C" Vector__XXX

BO_ 2633933822 EPT1: 8 Vector__XXX
SG_ EngineExhaustGasPort1Temperature : 0|16@1+ (0.03125,-273) [-273|1734.96875] "deg C" Vector__XXX
SG_ EngineExhaustGasPort2Temperature : 16|16@1+ (0.03125,-273) [-273|1734.96875] "deg C" Vector__XXX
SG_ EngineExhaustGasPort3Temperature : 32|16@1+ (0.03125,-273) [-273|1734.96875] "deg C" Vector__XXX
SG_ EngineExhaustGasPort4Temperature : 48|16@1+ (0.03125,-273) [-273|1734.96875] "deg C" Vector__XXX

BO_ 2566825214 ET2: 8 Vector__XXX
SG_ EngineOilTemperature2 : 0|16@1+ (0.03125,-273) [-273|1734.96875] "deg C" Vector__XXX
SG_ EngineECUTemperature : 16|16@1+ (0.03125,-273) [-273|1734.96875] "deg C" Vector__XXX
SG_ EngExhstGasRecirc1DiffPress : 32|16@1+ (0.0078125,-250) [-250|251.99] "kPa" Vector__XXX
SG_ EngExhstGasRecirc1Temperature : 48|16@1+ (0.03125,-273) [-273|1734.96875] "deg C" Vector__XXX

BO_ 2633934334 IMT2: 8 Vector__XXX
SG_ EngineIntakeManifold2Temperature : 0|8@1+ (1,-40) [-40|210] "deg C" Vector__XXX
SG_ EngineIntakeManifold3Temperature : 8|8@1+ (1,-40) [-40|210] "deg C" Vector__XXX
SG_ EngineIntakeManifold4Temperature : 16|8@1+ (1,-40) [-40|210] "deg C" Vector__XXX
SG_ EngineIntakeManifold5Temperature : 24|8@1+ (1,-40) [-40|210] "deg C" Vector__XXX
SG_ EngineIntakeManifold6Temperature : 32|8@1+ (1,-40) [-40|210] "deg C" Vector__XXX
SG_ DsrdEngIntakeManifoldTemperature : 40|8@1+ (1,-40) [-40|210] "deg C" Vector__XXX
SG_ DsrdEngIntkMnfldTempHghLmt : 48|8@1+ (1,-40) [-40|210] "deg C" Vector__XXX

BO_ 2566825726 IMT1: 8 Vector__XXX
SG_ EngineTurbocharger1BoostPressure : 0|16@1+ (0.125,0) [0|8031.875] "kPa" Vector__XXX
SG_ EngineTurbocharger2BoostPressure : 16|16@1+ (0.125,0) [0|8031.875] "kPa" Vector__XXX
SG_ EngineTurbocharger3BoostPressure : 32|16@1+ (0.125,0) [0|8031.875] "kPa" Vector__XXX
SG_ EngineTurbocharger4BoostPressure : 48|16@1+ (0.125,0) [0|8031.875] "kPa" Vector__XXX

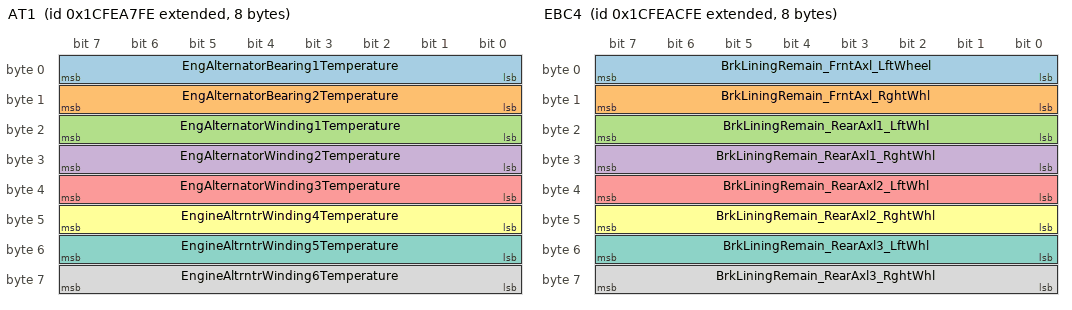
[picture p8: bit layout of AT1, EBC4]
BO_ 2633934846 AT1: 8 Vector__XXX
SG_ EngAlternatorBearing1Temperature : 0|8@1+ (1,-40) [-40|210] "deg C" Vector__XXX
SG_ EngAlternatorBearing2Temperature : 8|8@1+ (1,-40) [-40|210] "deg C" Vector__XXX
SG_ EngAlternatorWinding1Temperature : 16|8@1+ (1,-40) [-40|210] "deg C" Vector__XXX
SG_ EngAlternatorWinding2Temperature : 24|8@1+ (1,-40) [-40|210] "deg C" Vector__XXX
SG_ EngAlternatorWinding3Temperature : 32|8@1+ (1,-40) [-40|210] "deg C" Vector__XXX
SG_ EngineAltrntrWinding4Temperature : 40|8@1+ (1,-40) [-40|210] "deg C" Vector__XXX
SG_ EngineAltrntrWinding5Temperature : 48|8@1+ (1,-40) [-40|210] "deg C" Vector__XXX
SG_ EngineAltrntrWinding6Temperature : 56|8@1+ (1,-40) [-40|210] "deg C" Vector__XXX

BO_ 2633935102 ACTL: 8 Vector__XXX
SG_ ArticulationAngle : 0|8@1+ (1,-125) [-125|125] "deg" Vector__XXX
SG_ ArticulationAngularVelocity : 8|16@1+ (0.0078125,-250) [-250|250.992] "deg/s" Vector__XXX

BO_ 2633935358 EO1: 8 Vector__XXX
SG_ EngineDesiredRatedExhaustOxygen : 0|16@1+ (0.0025,0) [0|160.6375] "%" Vector__XXX
SG_ EngineDesiredExhaustOxygen : 16|16@1+ (0.0025,0) [0|160.6375] "%" Vector__XXX
SG_ EngineActualExhaustOxygen : 32|16@1+ (0.0025,0) [0|160.6375] "%" Vector__XXX
SG_ EngExhaustO2SensorFuelingCorrctn : 48|8@1+ (1,-125) [-125|125] "%" Vector__XXX
SG_ EngExhstO2SensorClsdLpOperation : 62|2@1+ (1,0) [0|3] "" Vector__XXX

BO_ 2633935614 AF2: 8 Vector__XXX
SG_ GaseousFuelCorrectionFactor : 0|8@1+ (1,0) [0|250] "%" Vector__XXX
SG_ EngIntakeManifoldDsrdAbsPressure : 8|16@1+ (0.1,0) [0|6425.5] "kPa" Vector__XXX
SG_ EngTurbochargerWastegateValvePos : 24|8@1+ (0.4,0) [0|100] "%" Vector__XXX
SG_ EngFuelSysGMFRateSnsrFuelCorrct : 32|8@1+ (1,-125) [-125|125] "%" Vector__XXX
SG_ GseousFuelInjectPulsCorrctFactor : 40|16@1+ (0.0078125,-251) [-251|250.99] "%" Vector__XXX

BO_ 2633935870 ETC6: 8 Vector__XXX
SG_ RecommendedGear : 0|8@1+ (1,-125) [-125|125] "" Vector__XXX
SG_ HighestPossibleGear : 8|8@1+ (1,-125) [-125|125] "" Vector__XXX
SG_ LowestPossibleGear : 16|8@1+ (1,-125) [-125|125] "" Vector__XXX
SG_ ClutchLifeRemaining : 24|8@1+ (0.4,0) [0|100] "%" Vector__XXX

BO_ 2633936126 EBC4: 8 Vector__XXX
SG_ BrkLiningRemain_FrntAxl_LftWheel : 0|8@1+ (0.4,0) [0|100] "%" Vector__XXX
SG_ BrkLiningRemain_FrntAxl_RghtWhl : 8|8@1+ (0.4,0) [0|100] "%" Vector__XXX
SG_ BrkLiningRemain_RearAxl1_LftWhl : 16|8@1+ (0.4,0) [0|100] "%" Vector__XXX
SG_ BrkLiningRemain_RearAxl1_RghtWhl : 24|8@1+ (0.4,0) [0|100] "%" Vector__XXX
SG_ BrkLiningRemain_RearAxl2_LftWhl : 32|8@1+ (0.4,0) [0|100] "%" Vector__XXX
SG_ BrkLiningRemain_RearAxl2_RghtWhl : 40|8@1+ (0.4,0) [0|100] "%" Vector__XXX
SG_ BrkLiningRemain_RearAxl3_LftWhl : 48|8@1+ (0.4,0) [0|100] "%" Vector__XXX
SG_ BrkLiningRemain_RearAxl3_RghtWhl : 56|8@1+ (0.4,0) [0|100] "%" Vector__XXX

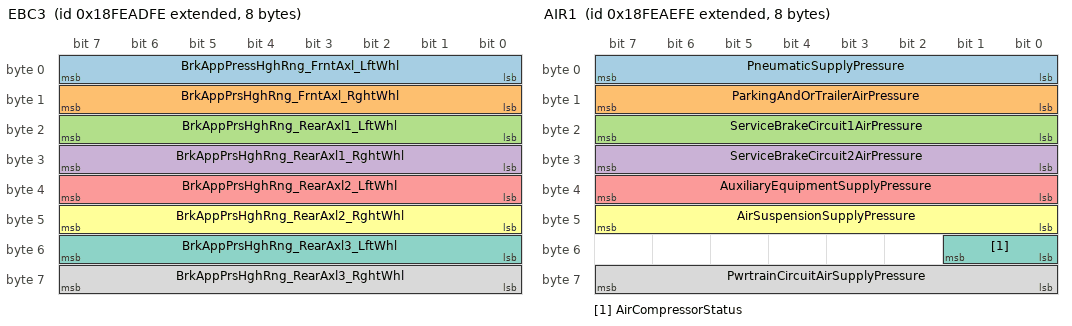
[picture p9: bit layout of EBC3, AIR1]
BO_ 2566827518 EBC3: 8 Vector__XXX
SG_ BrkAppPressHghRng_FrntAxl_LftWhl : 0|8@1+ (5,0) [0|1250] "kPa" Vector__XXX
SG_ BrkAppPrsHghRng_FrntAxl_RghtWhl : 8|8@1+ (5,0) [0|1250] "kPa" Vector__XXX
SG_ BrkAppPrsHghRng_RearAxl1_LftWhl : 16|8@1+ (5,0) [0|1250] "kPa" Vector__XXX
SG_ BrkAppPrsHghRng_RearAxl1_RghtWhl : 24|8@1+ (5,0) [0|1250] "kPa" Vector__XXX
SG_ BrkAppPrsHghRng_RearAxl2_LftWhl : 32|8@1+ (5,0) [0|1250] "kPa" Vector__XXX
SG_ BrkAppPrsHghRng_RearAxl2_RghtWhl : 40|8@1+ (5,0) [0|1250] "kPa" Vector__XXX
SG_ BrkAppPrsHghRng_RearAxl3_LftWhl : 48|8@1+ (5,0) [0|1250] "kPa" Vector__XXX
SG_ BrkAppPrsHghRng_RearAxl3_RghtWhl : 56|8@1+ (5,0) [0|1250] "kPa" Vector__XXX

BO_ 2566827774 AIR1: 8 Vector__XXX
SG_ PneumaticSupplyPressure : 0|8@1+ (8,0) [0|2000] "kPa" Vector__XXX
SG_ ParkingAndOrTrailerAirPressure : 8|8@1+ (8,0) [0|2000] "kPa" Vector__XXX
SG_ ServiceBrakeCircuit1AirPressure : 16|8@1+ (8,0) [0|2000] "kPa" Vector__XXX
SG_ ServiceBrakeCircuit2AirPressure : 24|8@1+ (8,0) [0|2000] "kPa" Vector__XXX
SG_ AuxiliaryEquipmentSupplyPressure : 32|8@1+ (8,0) [0|2000] "kPa" Vector__XXX
SG_ AirSuspensionSupplyPressure : 40|8@1+ (8,0) [0|2000] "kPa" Vector__XXX
SG_ AirCompressorStatus : 48|2@1+ (1,0) [0|3] "" Vector__XXX
SG_ PwrtrainCircuitAirSupplyPressure : 56|8@1+ (8,0) [0|2000] "kPa" Vector__XXX

BO_ 2633936894 GFC: 8 Vector__XXX
SG_ TripFuel : 0|32@1+ (0.5,0) [0|2105540607.5] "kg" Vector__XXX
SG_ TotalFuelUsed : 32|32@1+ (0.5,0) [0|2105540607.5] "kg" Vector__XXX

BO_ 2633937150 TTI2: 20 Vector__XXX
SG_ TripCruiseTime : 0|32@1+ (0.05,0) [0|210554060.75] "h" Vector__XXX
SG_ TripPTOGovernorTime : 32|32@1+ (0.05,0) [0|210554060.75] "h" Vector__XXX
SG_ TripEngineRunningTime : 64|32@1+ (0.05,0) [0|210554060.75] "h" Vector__XXX
SG_ TripIdleTime : 96|32@1+ (0.05,0) [0|210554060.75] "h" Vector__XXX
SG_ TripAirCompressorOnTime : 128|32@1+ (0.05,0) [0|210554060.75] "h" Vector__XXX

BO_ 2633937406 EH: 8 Vector__XXX
SG_ TotalECUDistance : 0|32@1+ (0.125,0) [0|526385151.875] "km" Vector__XXX
SG_ TotalECURunTime : 32|32@1+ (0.05,0) [0|210554060.75] "h" Vector__XXX

BO_ 2633937662 GFI1: 8 Vector__XXX
SG_ TotalEnginePTOGovernorFuelUsed : 0|32@1+ (0.5,0) [0|2105540607.5] "kg" Vector__XXX
SG_ TripAverageFuelRate : 32|16@1+ (0.05,0) [0|3212.75] "kg/h" Vector__XXX
SG_ EngineFuelSpecificGravity : 48|16@1+ (0.0001,0) [0|6.4255] "" Vector__XXX

BO_ 2633937918 LFI1: 8 Vector__XXX
SG_ TotalEnginePTOGovernorFuelUsed : 0|32@1+ (0.5,0) [0|2105540607.5] "l" Vector__XXX
SG_ TripAverageFuelRate : 32|16@1+ (0.05,0) [0|3212.75] "l/h" Vector__XXX
SG_ FlexibleFuelPercentage : 48|16@1+ (0.0025,0) [0|160.6375] "%" Vector__XXX

BO_ 2633938174 TTI1: 16 Vector__XXX
SG_ TripTimeInVSL : 0|32@1+ (0.05,0) [0|210554060.75] "h" Vector__XXX
SG_ TripTimeInTopGear : 32|32@1+ (0.05,0) [0|210554060.75] "h" Vector__XXX
SG_ TripTimeInGearDown : 64|32@1+ (0.05,0) [0|210554060.75] "h" Vector__XXX
SG_ TripTimeInDerateByEngine : 96|32@1+ (0.05,0) [0|210554060.75] "h" Vector__XXX

BO_ 2633938430 TSI: 8 Vector__XXX
SG_ TripNumberOfHotShutdowns : 0|16@1+ (1,0) [0|64255] "" Vector__XXX
SG_ TripNumberOfIdleShutdowns : 16|16@1+ (1,0) [0|64255] "" Vector__XXX
SG_ TripNumberOfIdlShutdownOverrides : 32|16@1+ (1,0) [0|64255] "" Vector__XXX
SG_ TripSuddenDecelerations : 48|16@1+ (1,0) [0|64255] "" Vector__XXX

BO_ 2633938686 TVI: 8 Vector__XXX
SG_ TripMaximumVehicleSpeed : 0|16@1+ (0.00390625,0) [0|250.996] "km/h" Vector__XXX
SG_ TripCruiseDistance : 16|32@1+ (0.125,0) [0|526385151.875] "km" Vector__XXX

BO_ 2633938942 LF: 10 Vector__XXX
SG_ TripMaximumEngineSpeed : 0|16@1+ (0.125,0) [0|8031.875] "rpm" Vector__XXX
SG_ TripAverageEngineSpeed : 16|16@1+ (0.125,0) [0|8031.875] "rpm" Vector__XXX
SG_ TripDriveAverageLoadFactor : 32|8@1+ (0.4,0) [0|100] "%" Vector__XXX
SG_ TotalDriveAverageLoadFactor : 40|8@1+ (0.4,0) [0|100] "%" Vector__XXX
SG_ TotalEngineCruiseTime : 48|32@1+ (0.05,0) [0|210554060.75] "h" Vector__XXX

BO_ 2633939198 GTFI: 22 Vector__XXX
SG_ TripDriveFuelUsed : 0|32@1+ (0.5,0) [0|2105540607.5] "kg" Vector__XXX
SG_ TripPTOGovernorMovingFuelUsed : 32|32@1+ (0.5,0) [0|2105540607.5] "kg" Vector__XXX
SG_ TripPTOGovernorNonMovingFuelUsed : 64|32@1+ (0.5,0) [0|2105540607.5] "kg" Vector__XXX
SG_ TripVehicleIdleFuelUsed : 96|32@1+ (0.5,0) [0|2105540607.5] "kg" Vector__XXX
SG_ TripCruiseFuelUsed : 128|32@1+ (0.5,0) [0|2105540607.5] "kg" Vector__XXX
SG_ TripDriveFuelEconomy : 160|16@1+ (0.001953125,0) [0|125.498046875] "km/kg" Vector__XXX

BO_ 2633939454 LTFI: 22 Vector__XXX
SG_ TripDriveFuelUsed : 0|32@1+ (0.5,0) [0|2105540607.5] "l" Vector__XXX
SG_ TripPTOGovernorMovingFuelUsed : 32|32@1+ (0.5,0) [0|2105540607.5] "l" Vector__XXX
SG_ TripPTOGovernorNonMovingFuelUsed : 64|32@1+ (0.5,0) [0|2105540607.5] "l" Vector__XXX
SG_ TripVehicleIdleFuelUsed : 96|32@1+ (0.5,0) [0|2105540607.5] "l" Vector__XXX
SG_ TripCruiseFuelUsed : 128|32@1+ (0.5,0) [0|2105540607.5] "l" Vector__XXX
SG_ TripDriveFuelEconomy : 160|16@1+ (0.001953125,0) [0|125.498046875] "km/l" Vector__XXX

BO_ 2633939710 TDI: 12 Vector__XXX
SG_ TripDistanceOnVSL : 0|32@1+ (0.125,0) [0|526385151.875] "km" Vector__XXX
SG_ TripGearDownDistance : 32|32@1+ (0.125,0) [0|526385151.875] "km" Vector__XXX
SG_ TripDistanceInTopGear : 64|32@1+ (0.125,0) [0|526385151.875] "km" Vector__XXX

BO_ 2633939966 TFI: 16 Vector__XXX
SG_ TripFanOnTime : 0|32@1+ (0.05,0) [0|210554060.75] "h" Vector__XXX
SG_ TripFanOnTimeDTTheEngineSystem : 32|32@1+ (0.05,0) [0|210554060.75] "h" Vector__XXX
SG_ TripFanOnTimeDueToAManualSwitch : 64|32@1+ (0.05,0) [0|210554060.75] "h" Vector__XXX
SG_ TripFanOnTimeDueToTheACSystem : 96|32@1+ (0.05,0) [0|210554060.75] "h" Vector__XXX

BO_ 2633940222 CBI: 16 Vector__XXX
SG_ TotalCompressionBrakeDistance : 0|32@1+ (0.125,0) [0|526385151.875] "km" Vector__XXX
SG_ TripCompressionBrakeDistance : 32|32@1+ (0.125,0) [0|526385151.875] "km" Vector__XXX
SG_ TripServiceBrakeDistance : 64|32@1+ (0.125,0) [0|526385151.875] "km" Vector__XXX
SG_ TripServiceBrakeApplications : 96|32@1+ (1,0) [0|4211081215] "brake appl" Vector__XXX

BO_ 2566831614 FD1: 8 Vector__XXX
SG_ EngineFan1EstimatedPercentSpeed : 0|8@1+ (0.4,0) [0|100] "%" Vector__XXX
SG_ FanDriveState : 8|4@1+ (1,0) [0|15] "" Vector__XXX
SG_ FanSpeed : 16|16@1+ (0.125,0) [0|8031.875] "rpm" Vector__XXX
SG_ HydraulicFanMotorPressure : 32|16@1+ (0.5,0) [0|32127.5] "kPa" Vector__XXX
SG_ FanDriveBypassCommandStatus : 48|8@1+ (0.4,0) [0|100] "%" Vector__XXX

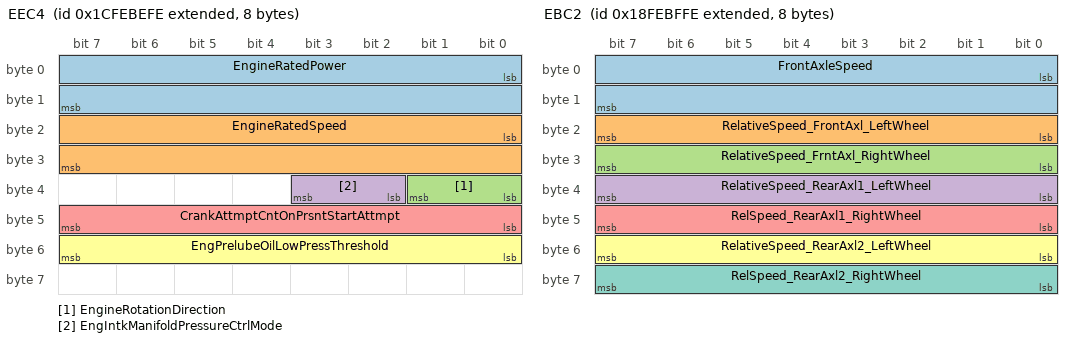
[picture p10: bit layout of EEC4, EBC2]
BO_ 2633940734 EEC4: 8 Vector__XXX
SG_ EngineRatedPower : 0|16@1+ (0.5,0) [0|32127.5] "kW" Vector__XXX
SG_ EngineRatedSpeed : 16|16@1+ (0.125,0) [0|8031.875] "rpm" Vector__XXX
SG_ EngineRotationDirection : 32|2@1+ (1,0) [0|3] "" Vector__XXX
SG_ EngIntkManifoldPressureCtrlMode : 34|2@1+ (1,0) [0|3] "" Vector__XXX
SG_ CrankAttmptCntOnPrsntStartAttmpt : 40|8@1+ (1,0) [0|250] "" Vector__XXX
SG_ EngPrelubeOilLowPressThreshold : 48|8@1+ (4,0) [0|1000] "kPa" Vector__XXX

BO_ 2566832126 EBC2: 8 Vector__XXX
SG_ FrontAxleSpeed : 0|16@1+ (0.00390625,0) [0|250.996] "km/h" Vector__XXX
SG_ RelativeSpeed_FrontAxl_LeftWheel : 16|8@1+ (0.0625,-7.8125) [-7.8125|7.8125] "km/h" Vector__XXX
SG_ RelativeSpeed_FrntAxl_RightWheel : 24|8@1+ (0.0625,-7.8125) [-7.8125|7.8125] "km/h" Vector__XXX
SG_ RelativeSpeed_RearAxl1_LeftWheel : 32|8@1+ (0.0625,-7.8125) [-7.8125|7.8125] "km/h" Vector__XXX
SG_ RelSpeed_RearAxl1_RightWheel : 40|8@1+ (0.0625,-7.8125) [-7.8125|7.8125] "km/h" Vector__XXX
SG_ RelativeSpeed_RearAxl2_LeftWheel : 48|8@1+ (0.0625,-7.8125) [-7.8125|7.8125] "km/h" Vector__XXX
SG_ RelSpeed_RearAxl2_RightWheel : 56|8@1+ (0.0625,-7.8125) [-7.8125|7.8125] "km/h" Vector__XXX

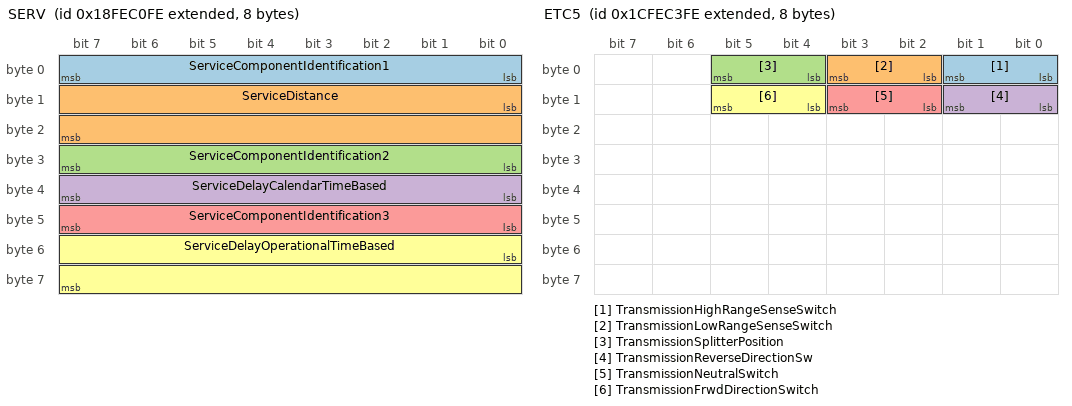
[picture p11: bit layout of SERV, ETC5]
BO_ 2566832382 SERV: 8 Vector__XXX
SG_ ServiceComponentIdentification1 : 0|8@1+ (1,0) [0|250] "" Vector__XXX
SG_ ServiceDistance : 8|16@1+ (5,-160635) [-160635|160640] "km" Vector__XXX
SG_ ServiceComponentIdentification2 : 24|8@1+ (1,0) [0|250] "" Vector__XXX
SG_ ServiceDelayCalendarTimeBased : 32|8@1+ (1,-125) [-125|125] "Weeks" Vector__XXX
SG_ ServiceComponentIdentification3 : 40|8@1+ (1,0) [0|250] "" Vector__XXX
SG_ ServiceDelayOperationalTimeBased : 48|16@1+ (1,-32127) [-32127|32128] "h" Vector__XXX

BO_ 2566832638 VDHR: 8 Vector__XXX
SG_ TotalVehicleDistance : 0|32@1+ (5,0) [0|21055406075] "m" Vector__XXX
SG_ TripDistance : 32|32@1+ (5,0) [0|21055406075] "m" Vector__XXX

BO_ 2633941758 ERC2: 8 Vector__XXX
SG_ TransmissionOutputRetarder : 0|2@1+ (1,0) [0|3] "" Vector__XXX
SG_ CrsCtrlRetarderActvSpeedOffset : 8|16@1+ (0.00390625,-125) [-125|125.996] "km/h" Vector__XXX

BO_ 2633942014 ETC5: 8 Vector__XXX
SG_ TransmissionHighRangeSenseSwitch : 0|2@1+ (1,0) [0|3] "" Vector__XXX
SG_ TransmissionLowRangeSenseSwitch : 2|2@1+ (1,0) [0|3] "" Vector__XXX
SG_ TransmissionSplitterPosition : 4|2@1+ (1,0) [0|3] "" Vector__XXX
SG_ TransmissionReverseDirectionSw : 8|2@1+ (1,0) [0|3] "" Vector__XXX
SG_ TransmissionNeutralSwitch : 10|2@1+ (1,0) [0|3] "" Vector__XXX
SG_ TransmissionFrwdDirectionSwitch : 12|2@1+ (1,0) [0|3] "" Vector__XXX

BO_ 2633942526 ETC4: 8 Vector__XXX
SG_ TrnsmSynchronizerCltchValue : 0|8@1+ (0.4,0) [0|100] "%" Vector__XXX
SG_ TransmissionSynchronizerBrkValue : 8|8@1+ (0.4,0) [0|100] "%" Vector__XXX

BO_ 2633943038 ETC3: 8 Vector__XXX
SG_ TransmissionShiftFingerGearPos : 0|8@1+ (0.4,0) [0|100] "%" Vector__XXX
SG_ TransmissionShiftFingerRailPos : 8|8@1+ (0.4,0) [0|100] "%" Vector__XXX
SG_ TrnsmShftFingerNtrlIndictr : 16|2@1+ (1,0) [0|3] "" Vector__XXX
SG_ TrnsmShftFingerEngmntIndictr : 18|2@1+ (1,0) [0|3] "" Vector__XXX
SG_ TrnsmShftFingerCenterRailIndictr : 20|2@1+ (1,0) [0|3] "" Vector__XXX
SG_ TransmissionShiftFingerRailActr1 : 24|2@1+ (1,0) [0|3] "" Vector__XXX
SG_ TransmissionShiftFingerGearActr1 : 26|2@1+ (1,0) [0|3] "" Vector__XXX
SG_ TransmissionShiftFingerRailActr2 : 28|2@1+ (1,0) [0|3] "" Vector__XXX
SG_ TransmissionShiftFingerGearActr2 : 30|2@1+ (1,0) [0|3] "" Vector__XXX
SG_ TransmissionRangeHighActuator : 32|2@1+ (1,0) [0|3] "" Vector__XXX
SG_ TransmissionRangeLowActuator : 34|2@1+ (1,0) [0|3] "" Vector__XXX
SG_ TransmissionSplitterDirectActr : 36|2@1+ (1,0) [0|3] "" Vector__XXX
SG_ TransmissionSplitterIndirectActr : 38|2@1+ (1,0) [0|3] "" Vector__XXX
SG_ TransmissionClutchActuator : 40|2@1+ (1,0) [0|3] "" Vector__XXX
SG_ TrnsmTrqCnvLockupCltchActr : 42|2@1+ (1,0) [0|3] "" Vector__XXX
SG_ TransmissionDefuelActuator : 44|2@1+ (1,0) [0|3] "" Vector__XXX
SG_ TransmissionInertiaBrakeActuator : 46|2@1+ (1,0) [0|3] "" Vector__XXX

BO_ 2566834942 DM01: 50 Vector__XXX
SG_ ProtectLamp : 0|2@1+ (1,0) [0|3] "" Vector__XXX
SG_ AmberWarningLamp : 2|2@1+ (1,0) [0|3] "" Vector__XXX
SG_ RedStopLamp : 4|2@1+ (1,0) [0|3] "" Vector__XXX
SG_ MalfunctionIndicatorLamp : 6|2@1+ (1,0) [0|3] "" Vector__XXX
SG_ FlashProtectLamp : 8|2@1+ (1,0) [0|3] "" Vector__XXX
SG_ FlashAmberWarningLamp : 10|2@1+ (1,0) [0|3] "" Vector__XXX
SG_ FlashRedStopLamp : 12|2@1+ (1,0) [0|3] "" Vector__XXX
SG_ FlashMalfunctionIndicatorLamp : 14|2@1+ (1,0) [0|3] "" Vector__XXX
SG_ SuspectParameterNumber : 23|19@0+ (1,0) [0|524287] "" Vector__XXX
SG_ FailureModeIdentifier : 32|5@1+ (1,0) [0|31] "" Vector__XXX
SG_ OccurrenceCount : 40|7@1+ (1,0) [0|127] "" Vector__XXX
SG_ SPNConversionMethod : 47|1@1+ (1,0) [0|1] "" Vector__XXX
SG_ SuspectParameterNumber2 : 55|19@0+ (1,0) [0|524287] "" Vector__XXX
SG_ FailureModeIdentifier2 : 64|5@1+ (1,0) [0|31] "" Vector__XXX
SG_ OccurrenceCount2 : 72|7@1+ (1,0) [0|127] "" Vector__XXX
SG_ SPNConversionMethod2 : 79|1@1+ (1,0) [0|1] "" Vector__XXX
SG_ SuspectParameterNumber3 : 87|19@0+ (1,0) [0|524287] "" Vector__XXX
SG_ FailureModeIdentifier3 : 96|5@1+ (1,0) [0|31] "" Vector__XXX
SG_ OccurrenceCount3 : 104|7@1+ (1,0) [0|127] "" Vector__XXX
SG_ SPNConversionMethod3 : 111|1@1+ (1,0) [0|1] "" Vector__XXX
SG_ SuspectParameterNumber4 : 119|19@0+ (1,0) [0|524287] "" Vector__XXX
SG_ FailureModeIdentifier4 : 128|5@1+ (1,0) [0|31] "" Vector__XXX
SG_ OccurrenceCount4 : 136|7@1+ (1,0) [0|127] "" Vector__XXX
SG_ SPNConversionMethod4 : 143|1@1+ (1,0) [0|1] "" Vector__XXX
SG_ SuspectParameterNumber5 : 151|19@0+ (1,0) [0|524287] "" Vector__XXX
SG_ FailureModeIdentifier5 : 160|5@1+ (1,0) [0|31] "" Vector__XXX
SG_ OccurrenceCount5 : 168|7@1+ (1,0) [0|127] "" Vector__XXX
SG_ SPNConversionMethod5 : 175|1@1+ (1,0) [0|1] "" Vector__XXX
SG_ SuspectParameterNumber6 : 183|19@0+ (1,0) [0|524287] "" Vector__XXX
SG_ FailureModeIdentifier6 : 192|5@1+ (1,0) [0|31] "" Vector__XXX
SG_ OccurrenceCount6 : 200|7@1+ (1,0) [0|127] "" Vector__XXX
SG_ SPNConversionMethod6 : 207|1@1+ (1,0) [0|1] "" Vector__XXX
SG_ SuspectParameterNumber7 : 215|19@0+ (1,0) [0|524287] "" Vector__XXX
SG_ FailureModeIdentifier7 : 224|5@1+ (1,0) [0|31] "" Vector__XXX
SG_ OccurrenceCount7 : 232|7@1+ (1,0) [0|127] "" Vector__XXX
SG_ SPNConversionMethod7 : 239|1@1+ (1,0) [0|1] "" Vector__XXX
SG_ SuspectParameterNumber8 : 247|19@0+ (1,0) [0|524287] "" Vector__XXX
SG_ FailureModeIdentifier8 : 256|5@1+ (1,0) [0|31] "" Vector__XXX
SG_ OccurrenceCount8 : 264|7@1+ (1,0) [0|127] "" Vector__XXX
SG_ SPNConversionMethod8 : 271|1@1+ (1,0) [0|1] "" Vector__XXX
SG_ SuspectParameterNumber9 : 279|19@0+ (1,0) [0|524287] "" Vector__XXX
SG_ FailureModeIdentifier9 : 288|5@1+ (1,0) [0|31] "" Vector__XXX
SG_ OccurrenceCount9 : 296|7@1+ (1,0) [0|127] "" Vector__XXX
SG_ SPNConversionMethod9 : 303|1@1+ (1,0) [0|1] "" Vector__XXX
SG_ SuspectParameterNumber10 : 311|19@0+ (1,0) [0|524287] "" Vector__XXX
SG_ FailureModeIdentifier10 : 320|5@1+ (1,0) [0|31] "" Vector__XXX
SG_ OccurrenceCount10 : 328|7@1+ (1,0) [0|127] "" Vector__XXX
SG_ SPNConversionMethod10 : 335|1@1+ (1,0) [0|1] "" Vector__XXX
SG_ SuspectParameterNumber11 : 343|19@0+ (1,0) [0|524287] "" Vector__XXX
SG_ FailureModeIdentifier11 : 352|5@1+ (1,0) [0|31] "" Vector__XXX
SG_ OccurrenceCount11 : 360|7@1+ (1,0) [0|127] "" Vector__XXX
SG_ SPNConversionMethod11 : 367|1@1+ (1,0) [0|1] "" Vector__XXX
SG_ SuspectParameterNumber12 : 375|19@0+ (1,0) [0|524287] "" Vector__XXX
SG_ FailureModeIdentifier12 : 384|5@1+ (1,0) [0|31] "" Vector__XXX
SG_ OccurrenceCount12 : 392|7@1+ (1,0) [0|127] "" Vector__XXX
SG_ SPNConversionMethod12 : 399|1@1+ (1,0) [0|1] "" Vector__XXX

BO_ 2566835198 DM02: 50 Vector__XXX
SG_ ProtectLamp : 0|2@1+ (1,0) [0|3] "" Vector__XXX
SG_ AmberWarningLamp : 2|2@1+ (1,0) [0|3] "" Vector__XXX
SG_ RedStopLamp : 4|2@1+ (1,0) [0|3] "" Vector__XXX
SG_ MalfunctionIndicatorLamp : 6|2@1+ (1,0) [0|3] "" Vector__XXX
SG_ FlashProtectLamp : 8|2@1+ (1,0) [0|3] "" Vector__XXX
SG_ FlashAmberWarningLamp : 10|2@1+ (1,0) [0|3] "" Vector__XXX
SG_ FlashRedStopLamp : 12|2@1+ (1,0) [0|3] "" Vector__XXX
SG_ FlashMalfunctionIndicatorLamp : 14|2@1+ (1,0) [0|3] "" Vector__XXX
SG_ SuspectParameterNumber : 23|19@0+ (1,0) [0|524287] "" Vector__XXX
SG_ FailureModeIdentifier : 32|5@1+ (1,0) [0|31] "" Vector__XXX
SG_ OccurrenceCount : 40|7@1+ (1,0) [0|127] "" Vector__XXX
SG_ SPNConversionMethod : 47|1@1+ (1,0) [0|1] "" Vector__XXX
SG_ SuspectParameterNumber2 : 55|19@0+ (1,0) [0|524287] "" Vector__XXX
SG_ FailureModeIdentifier2 : 64|5@1+ (1,0) [0|31] "" Vector__XXX
SG_ OccurrenceCount2 : 72|7@1+ (1,0) [0|127] "" Vector__XXX
SG_ SPNConversionMethod2 : 79|1@1+ (1,0) [0|1] "" Vector__XXX
SG_ SuspectParameterNumber3 : 87|19@0+ (1,0) [0|524287] "" Vector__XXX
SG_ FailureModeIdentifier3 : 96|5@1+ (1,0) [0|31] "" Vector__XXX
SG_ OccurrenceCount3 : 104|7@1+ (1,0) [0|127] "" Vector__XXX
SG_ SPNConversionMethod3 : 111|1@1+ (1,0) [0|1] "" Vector__XXX
SG_ SuspectParameterNumber4 : 119|19@0+ (1,0) [0|524287] "" Vector__XXX
SG_ FailureModeIdentifier4 : 128|5@1+ (1,0) [0|31] "" Vector__XXX
SG_ OccurrenceCount4 : 136|7@1+ (1,0) [0|127] "" Vector__XXX
SG_ SPNConversionMethod4 : 143|1@1+ (1,0) [0|1] "" Vector__XXX
SG_ SuspectParameterNumber5 : 151|19@0+ (1,0) [0|524287] "" Vector__XXX
SG_ FailureModeIdentifier5 : 160|5@1+ (1,0) [0|31] "" Vector__XXX
SG_ OccurrenceCount5 : 168|7@1+ (1,0) [0|127] "" Vector__XXX
SG_ SPNConversionMethod5 : 175|1@1+ (1,0) [0|1] "" Vector__XXX
SG_ SuspectParameterNumber6 : 183|19@0+ (1,0) [0|524287] "" Vector__XXX
SG_ FailureModeIdentifier6 : 192|5@1+ (1,0) [0|31] "" Vector__XXX
SG_ OccurrenceCount6 : 200|7@1+ (1,0) [0|127] "" Vector__XXX
SG_ SPNConversionMethod6 : 207|1@1+ (1,0) [0|1] "" Vector__XXX
SG_ SuspectParameterNumber7 : 215|19@0+ (1,0) [0|524287] "" Vector__XXX
SG_ FailureModeIdentifier7 : 224|5@1+ (1,0) [0|31] "" Vector__XXX
SG_ OccurrenceCount7 : 232|7@1+ (1,0) [0|127] "" Vector__XXX
SG_ SPNConversionMethod7 : 239|1@1+ (1,0) [0|1] "" Vector__XXX
SG_ SuspectParameterNumber8 : 247|19@0+ (1,0) [0|524287] "" Vector__XXX
SG_ FailureModeIdentifier8 : 256|5@1+ (1,0) [0|31] "" Vector__XXX
SG_ OccurrenceCount8 : 264|7@1+ (1,0) [0|127] "" Vector__XXX
SG_ SPNConversionMethod8 : 271|1@1+ (1,0) [0|1] "" Vector__XXX
SG_ SuspectParameterNumber9 : 279|19@0+ (1,0) [0|524287] "" Vector__XXX
SG_ FailureModeIdentifier9 : 288|5@1+ (1,0) [0|31] "" Vector__XXX
SG_ OccurrenceCount9 : 296|7@1+ (1,0) [0|127] "" Vector__XXX
SG_ SPNConversionMethod9 : 303|1@1+ (1,0) [0|1] "" Vector__XXX
SG_ SuspectParameterNumber10 : 311|19@0+ (1,0) [0|524287] "" Vector__XXX
SG_ FailureModeIdentifier10 : 320|5@1+ (1,0) [0|31] "" Vector__XXX
SG_ OccurrenceCount10 : 328|7@1+ (1,0) [0|127] "" Vector__XXX
SG_ SPNConversionMethod10 : 335|1@1+ (1,0) [0|1] "" Vector__XXX
SG_ SuspectParameterNumber11 : 343|19@0+ (1,0) [0|524287] "" Vector__XXX
SG_ FailureModeIdentifier11 : 352|5@1+ (1,0) [0|31] "" Vector__XXX
SG_ OccurrenceCount11 : 360|7@1+ (1,0) [0|127] "" Vector__XXX
SG_ SPNConversionMethod11 : 367|1@1+ (1,0) [0|1] "" Vector__XXX
SG_ SuspectParameterNumber12 : 375|19@0+ (1,0) [0|524287] "" Vector__XXX
SG_ FailureModeIdentifier12 : 384|5@1+ (1,0) [0|31] "" Vector__XXX
SG_ OccurrenceCount12 : 392|7@1+ (1,0) [0|127] "" Vector__XXX
SG_ SPNConversionMethod12 : 399|1@1+ (1,0) [0|1] "" Vector__XXX

BO_ 2566835454 DM03: 0 Vector__XXX

BO_ 2566835710 DM04: 14 Vector__XXX
SG_ FreezeFrameLength : 0|8@1+ (1,0) [0|255] "" Vector__XXX
SG_ SuspectParameterNumber : 15|19@0+ (1,0) [0|524287] "" Vector__XXX
SG_ FailureModeIdentifier : 24|5@1+ (1,0) [0|31] "" Vector__XXX
SG_ OccurrenceCount : 32|7@1+ (1,0) [0|127] "" Vector__XXX
SG_ SPNConversionMethod : 39|1@1+ (1,0) [0|1] "" Vector__XXX
SG_ ManufacturerSpecifiedInformation : 104|8@1+ (1,0) [0|255] "" Vector__XXX

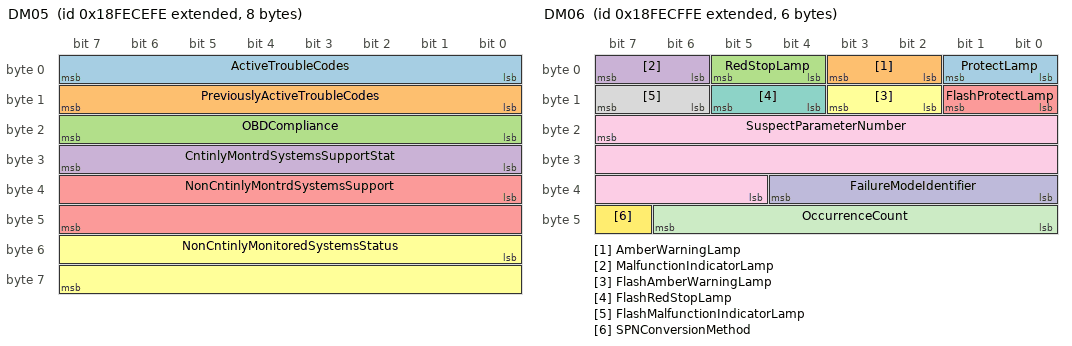
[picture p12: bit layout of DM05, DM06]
BO_ 2566835966 DM05: 8 Vector__XXX
SG_ ActiveTroubleCodes : 0|8@1+ (1,0) [0|250] "" Vector__XXX
SG_ PreviouslyActiveTroubleCodes : 8|8@1+ (1,0) [0|250] "" Vector__XXX
SG_ OBDCompliance : 16|8@1+ (1,0) [0|250] "" Vector__XXX
SG_ CntinlyMontrdSystemsSupportStat : 24|8@1+ (1,0) [0|255] "" Vector__XXX
SG_ NonCntinlyMontrdSystemsSupport : 32|16@1+ (1,0) [0|65535] "" Vector__XXX
SG_ NonCntinlyMonitoredSystemsStatus : 48|16@1+ (1,0) [0|65535] "" Vector__XXX

BO_ 2566836222 DM06: 6 Vector__XXX
SG_ ProtectLamp : 0|2@1+ (1,0) [0|3] "" Vector__XXX
SG_ AmberWarningLamp : 2|2@1+ (1,0) [0|3] "" Vector__XXX
SG_ RedStopLamp : 4|2@1+ (1,0) [0|3] "" Vector__XXX
SG_ MalfunctionIndicatorLamp : 6|2@1+ (1,0) [0|3] "" Vector__XXX
SG_ FlashProtectLamp : 8|2@1+ (1,0) [0|3] "" Vector__XXX
SG_ FlashAmberWarningLamp : 10|2@1+ (1,0) [0|3] "" Vector__XXX
SG_ FlashRedStopLamp : 12|2@1+ (1,0) [0|3] "" Vector__XXX
SG_ FlashMalfunctionIndicatorLamp : 14|2@1+ (1,0) [0|3] "" Vector__XXX
SG_ SuspectParameterNumber : 23|19@0+ (1,0) [0|524287] "" Vector__XXX
SG_ FailureModeIdentifier : 32|5@1+ (1,0) [0|31] "" Vector__XXX
SG_ OccurrenceCount : 40|7@1+ (1,0) [0|127] "" Vector__XXX
SG_ SPNConversionMethod : 47|1@1+ (1,0) [0|1] "" Vector__XXX

BO_ 2566836478 DM08: 8 Vector__XXX
SG_ TestIdentifier : 0|8@1+ (1,0) [0|255] "" Vector__XXX
SG_ TestTypeComponentIdentifier : 8|8@1+ (1,0) [0|250] "" Vector__XXX
SG_ TestValue : 16|16@1+ (1,0) [0|65535] "" Vector__XXX
SG_ TestLimitMaximum : 32|16@1+ (1,0) [0|65535] "" Vector__XXX
SG_ TestLimitMinimum : 48|16@1+ (1,0) [0|65535] "" Vector__XXX

BO_ 2566836734 DM09: 0 Vector__XXX

BO_ 2566836990 DM10: 8 Vector__XXX
SG_ TestIdentifiersSupported : 0|64@1+ (1,0) [0|1.84467440737096E019] "" Vector__XXX

BO_ 2566837246 DM11: 0 Vector__XXX

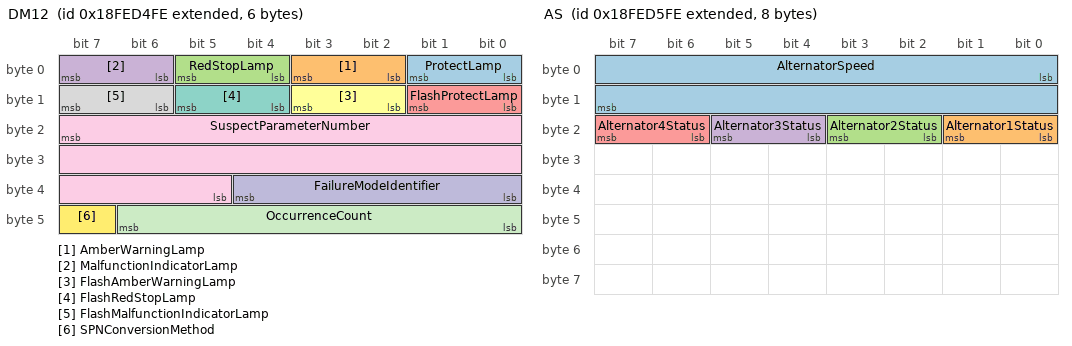
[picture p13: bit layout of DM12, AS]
BO_ 2566837502 DM12: 6 Vector__XXX
SG_ ProtectLamp : 0|2@1+ (1,0) [0|3] "" Vector__XXX
SG_ AmberWarningLamp : 2|2@1+ (1,0) [0|3] "" Vector__XXX
SG_ RedStopLamp : 4|2@1+ (1,0) [0|3] "" Vector__XXX
SG_ MalfunctionIndicatorLamp : 6|2@1+ (1,0) [0|3] "" Vector__XXX
SG_ FlashProtectLamp : 8|2@1+ (1,0) [0|3] "" Vector__XXX
SG_ FlashAmberWarningLamp : 10|2@1+ (1,0) [0|3] "" Vector__XXX
SG_ FlashRedStopLamp : 12|2@1+ (1,0) [0|3] "" Vector__XXX
SG_ FlashMalfunctionIndicatorLamp : 14|2@1+ (1,0) [0|3] "" Vector__XXX
SG_ SuspectParameterNumber : 23|19@0+ (1,0) [0|524287] "" Vector__XXX
SG_ FailureModeIdentifier : 32|5@1+ (1,0) [0|31] "" Vector__XXX
SG_ OccurrenceCount : 40|7@1+ (1,0) [0|127] "" Vector__XXX
SG_ SPNConversionMethod : 47|1@1+ (1,0) [0|1] "" Vector__XXX

BO_ 2566837758 AS: 8 Vector__XXX
SG_ AlternatorSpeed : 0|16@1+ (0.5,0) [0|32127.5] "rpm" Vector__XXX
SG_ Alternator1Status : 16|2@1+ (1,0) [0|3] "" Vector__XXX
SG_ Alternator2Status : 18|2@1+ (1,0) [0|3] "" Vector__XXX
SG_ Alternator3Status : 20|2@1+ (1,0) [0|3] "" Vector__XXX
SG_ Alternator4Status : 22|2@1+ (1,0) [0|3] "" Vector__XXX

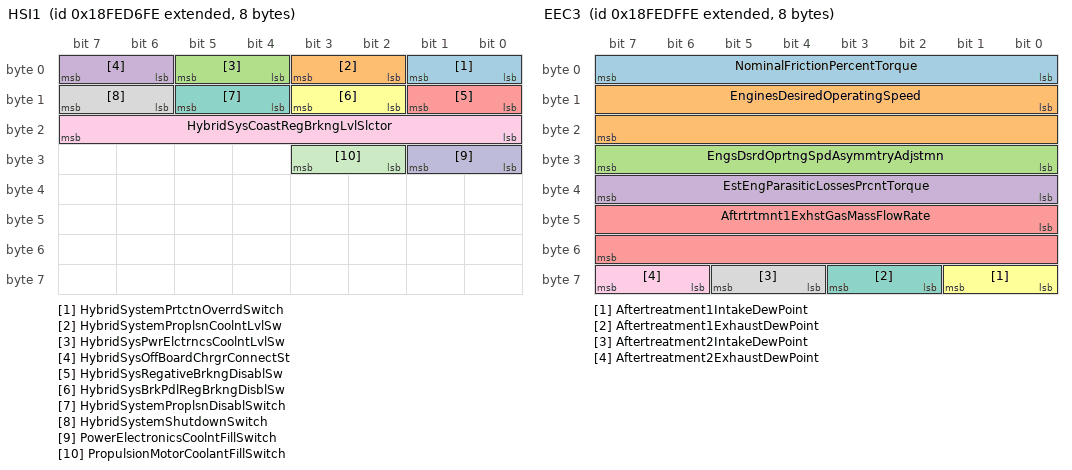
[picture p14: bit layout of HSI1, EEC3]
BO_ 2566838014 HSI1: 8 Vector__XXX
SG_ HybridSystemPrtctnOverrdSwitch : 0|2@1+ (1,0) [0|3] "" Vector__XXX
SG_ HybridSystemProplsnCoolntLvlSw : 2|2@1+ (1,0) [0|3] "" Vector__XXX
SG_ HybridSysPwrElctrncsCoolntLvlSw : 4|2@1+ (1,0) [0|3] "" Vector__XXX
SG_ HybridSysOffBoardChrgrConnectSt : 6|2@1+ (1,0) [0|3] "" Vector__XXX
SG_ HybridSysRegativeBrkngDisablSw : 8|2@1+ (1,0) [0|3] "" Vector__XXX
SG_ HybridSysBrkPdlRegBrkngDisblSw : 10|2@1+ (1,0) [0|3] "" Vector__XXX
SG_ HybridSystemProplsnDisablSwitch : 12|2@1+ (1,0) [0|3] "" Vector__XXX
SG_ HybridSystemShutdownSwitch : 14|2@1+ (1,0) [0|3] "" Vector__XXX
SG_ HybridSysCoastRegBrkngLvlSlctor : 16|8@1+ (0.4,0) [0|100] "%" Vector__XXX
SG_ PowerElectronicsCoolntFillSwitch : 24|2@1+ (1,0) [0|3] "" Vector__XXX
SG_ PropulsionMotorCoolantFillSwitch : 26|2@1+ (1,0) [0|3] "" Vector__XXX

BO_ 2566838526 CA: 9 Vector__XXX
SG_ NAMEOfCommandedAddressTarget : 0|64@1+ (1,0) [0|1.84467440737096E019] "" Vector__XXX
SG_ AddressAssignment : 64|8@1+ (1,0) [0|255] "" Vector__XXX

BO_ 2566838782 AUXIO1: 8 Vector__XXX
SG_ AuxiliaryIO04 : 0|2@1+ (1,0) [0|3] "" Vector__XXX
SG_ AuxiliaryIO03 : 2|2@1+ (1,0) [0|3] "" Vector__XXX
SG_ AuxiliaryIO02 : 4|2@1+ (1,0) [0|3] "" Vector__XXX
SG_ AuxiliaryIO01 : 6|2@1+ (1,0) [0|3] "" Vector__XXX
SG_ AuxiliaryIO08 : 8|2@1+ (1,0) [0|3] "" Vector__XXX
SG_ AuxiliaryIO07 : 10|2@1+ (1,0) [0|3] "" Vector__XXX
SG_ AuxiliaryIO06 : 12|2@1+ (1,0) [0|3] "" Vector__XXX
SG_ AuxiliaryIO05 : 14|2@1+ (1,0) [0|3] "" Vector__XXX
SG_ AuxiliaryIO12 : 16|2@1+ (1,0) [0|3] "" Vector__XXX
SG_ AuxiliaryIO11 : 18|2@1+ (1,0) [0|3] "" Vector__XXX
SG_ AuxiliaryIO10 : 20|2@1+ (1,0) [0|3] "" Vector__XXX
SG_ AuxiliaryIO09 : 22|2@1+ (1,0) [0|3] "" Vector__XXX
SG_ AuxiliaryIO16 : 24|2@1+ (1,0) [0|3] "" Vector__XXX
SG_ AuxiliaryIO15 : 26|2@1+ (1,0) [0|3] "" Vector__XXX
SG_ AuxiliaryIO14 : 28|2@1+ (1,0) [0|3] "" Vector__XXX
SG_ AuxiliaryIO13 : 30|2@1+ (1,0) [0|3] "" Vector__XXX
SG_ AuxiliaryIOChannel1 : 32|16@1+ (1,0) [0|64255] "" Vector__XXX
SG_ AuxiliaryIOChannel2 : 48|16@1+ (1,0) [0|64255] "" Vector__XXX

BO_ 2566839038 SOFT: 201 Vector__XXX
SG_ NoOfSoftwareIdentificationFields : 0|8@1+ (1,0) [0|250] "" Vector__XXX
SG_ SoftwareIdentification : 15|1600@0+ (1,0) [0|0] "ASCII" Vector__XXX

BO_ 2566839294 EFL_P2: 8 Vector__XXX
SG_ EngineInjectionControlPressure : 0|16@1+ (0.00390625,0) [0|250.996] "MPa" Vector__XXX
SG_ EngInjectorMeteringRail1Pressure : 16|16@1+ (0.00390625,0) [0|250.996] "MPa" Vector__XXX
SG_ EngInjectorTimingRail1Pressure : 32|16@1+ (0.00390625,0) [0|250.996] "MPa" Vector__XXX
SG_ EngInjectorMeteringRail2Pressure : 48|16@1+ (0.00390625,0) [0|250.996] "MPa" Vector__XXX

BO_ 2566839550 IO: 8 Vector__XXX
SG_ EngineTotalIdleFuelUsed : 0|32@1+ (0.5,0) [0|2105540607.5] "l" Vector__XXX
SG_ EngineTotalIdleHours : 32|32@1+ (0.05,0) [0|210554060.75] "h" Vector__XXX

BO_ 2566839806 TC: 8 Vector__XXX
SG_ EngTurbochargerLubeOilPressure1 : 0|8@1+ (4,0) [0|1000] "kPa" Vector__XXX
SG_ EngineTurbocharger1Speed : 8|16@1+ (4,0) [0|257020] "rpm" Vector__XXX
SG_ EngineTurbochargerOilLevelSwitch : 30|2@1+ (1,0) [0|3] "" Vector__XXX
SG_ EngineTurbochargerDiffSpeed : 32|16@1+ (4,0) [0|257020] "rpm" Vector__XXX

BO_ 2566840062 AIR2: 8 Vector__XXX
SG_ EngineAirStartPressure : 0|8@1+ (4,0) [0|1000] "kPa" Vector__XXX
SG_ EngineAirStartPressureExtRange : 8|8@1+ (16,0) [0|4000] "kPa" Vector__XXX
SG_ EngineAirStopPressure : 16|8@1+ (4,0) [0|1000] "kPa" Vector__XXX

BO_ 2566840318 EEC3: 8 Vector__XXX
SG_ NominalFrictionPercentTorque : 0|8@1+ (1,-125) [-125|125] "%" Vector__XXX
SG_ EnginesDesiredOperatingSpeed : 8|16@1+ (0.125,0) [0|8031.875] "rpm" Vector__XXX
SG_ EngsDsrdOprtngSpdAsymmtryAdjstmn : 24|8@1+ (1,0) [0|250] "" Vector__XXX
SG_ EstEngParasiticLossesPrcntTorque : 32|8@1+ (1,-125) [-125|125] "%" Vector__XXX
SG_ Aftrtrtmnt1ExhstGasMassFlowRate : 40|16@1+ (0.2,0) [0|12851] "kg/h" Vector__XXX
SG_ Aftertreatment1IntakeDewPoint : 56|2@1+ (1,0) [0|3] "" Vector__XXX
SG_ Aftertreatment1ExhaustDewPoint : 58|2@1+ (1,0) [0|3] "" Vector__XXX
SG_ Aftertreatment2IntakeDewPoint : 60|2@1+ (1,0) [0|3] "" Vector__XXX
SG_ Aftertreatment2ExhaustDewPoint : 62|2@1+ (1,0) [0|3] "" Vector__XXX

BO_ 2566840574 VD: 8 Vector__XXX
SG_ TripDistance : 0|32@1+ (0.125,0) [0|526385151.875] "km" Vector__XXX
SG_ TotalVehicleDistance : 32|32@1+ (0.125,0) [0|526385151.875] "km" Vector__XXX

BO_ 2566840830 RC: 19 Vector__XXX
SG_ RetarderType : 0|4@1+ (1,0) [0|15] "" Vector__XXX
SG_ RetarderLocation : 4|4@1+ (1,0) [0|15] "" Vector__XXX
SG_ RetarderControlMethod : 8|8@1+ (1,0) [0|250] "" Vector__XXX
SG_ RetarderSpeedAtIdle_Point1 : 16|16@1+ (0.125,0) [0|8031.875] "rpm" Vector__XXX
SG_ RetarderPrcntTorqueAtIdl_Point1 : 32|8@1+ (1,-125) [-125|125] "%" Vector__XXX
SG_ MaximumRetarderSpeed_Point2 : 40|16@1+ (0.125,0) [0|8031.875] "rpm" Vector__XXX
SG_ RtrdrPrcntTorqueAtMaxSpd_Point2 : 56|8@1+ (1,-125) [-125|125] "%" Vector__XXX
SG_ RetarderSpeedAtPoint3 : 64|16@1+ (0.125,0) [0|8031.875] "rpm" Vector__XXX
SG_ RetarderPercentTorqueAtPoint3 : 80|8@1+ (1,-125) [-125|125] "%" Vector__XXX
SG_ RetarderSpeedAtPoint4 : 88|16@1+ (0.125,0) [0|8031.875] "rpm" Vector__XXX
SG_ RetarderPercentTorqueAtPoint4 : 104|8@1+ (1,-125) [-125|125] "%" Vector__XXX
SG_ RetarderSpeedAtPeakTorque_Point5 : 112|16@1+ (0.125,0) [0|8031.875] "rpm" Vector__XXX
SG_ RetarderReferenceTorque : 128|16@1+ (1,0) [0|64255] "Nm" Vector__XXX
SG_ PercentTorqueAtPeakTorque_Point5 : 144|8@1+ (1,-125) [-125|125] "%" Vector__XXX

BO_ 2566841086 TCFG: 8 Vector__XXX
SG_ NumberOfReverseGearRatios : 0|8@1+ (1,0) [0|250] "" Vector__XXX
SG_ NumberOfForwardGearRatios : 8|8@1+ (1,0) [0|250] "" Vector__XXX
SG_ TransmissionGearRatio : 16|16@1+ (0.001,0) [0|64.255] "" Vector__XXX

BO_ 2566841342 EC1: 40 Vector__XXX
SG_ EngineSpeedAtIdle_Point1 : 0|16@1+ (0.125,0) [0|8031.875] "rpm" Vector__XXX
SG_ EnginePercentTorqueAtIdle_Point1 : 16|8@1+ (1,-125) [-125|125] "%" Vector__XXX
SG_ EngineSpeedAtPoint2 : 24|16@1+ (0.125,0) [0|8031.875] "rpm" Vector__XXX
SG_ EnginePercentTorqueAtPoint2 : 40|8@1+ (1,-125) [-125|125] "%" Vector__XXX
SG_ EngineSpeedAtPoint3 : 48|16@1+ (0.125,0) [0|8031.875] "rpm" Vector__XXX
SG_ EnginePercentTorqueAtPoint3 : 64|8@1+ (1,-125) [-125|125] "%" Vector__XXX
SG_ EngineSpeedAtPoint4 : 72|16@1+ (0.125,0) [0|8031.875] "rpm" Vector__XXX
SG_ EnginePercentTorqueAtPoint4 : 88|8@1+ (1,-125) [-125|125] "%" Vector__XXX
SG_ EngineSpeedAtPoint5 : 96|16@1+ (0.125,0) [0|8031.875] "rpm" Vector__XXX
SG_ EnginePercentTorqueAtPoint5 : 112|8@1+ (1,-125) [-125|125] "%" Vector__XXX
SG_ EngineSpeedAtHighIdle_Point6 : 120|16@1+ (0.125,0) [0|8031.875] "rpm" Vector__XXX
SG_ EngineGainOfTheEndspeedGovernor : 136|16@1+ (0.00078125,0) [0|50.2] "%/rpm" Vector__XXX
SG_ EngineReferenceTorque : 152|16@1+ (1,0) [0|64255] "Nm" Vector__XXX
SG_ EngMaxMmntaryOvrrdSpeed_Point7 : 168|16@1+ (0.125,0) [0|8031.875] "rpm" Vector__XXX
SG_ EngMaxMomentaryOverrideTimeLmt : 184|8@1+ (0.1,0) [0|25] "s" Vector__XXX
SG_ EngRequestedSpeedCtrlRngLowerLmt : 192|8@1+ (10,0) [0|2500] "rpm" Vector__XXX
SG_ EngRequestedSpeedCtrlRngUpperLmt : 200|8@1+ (10,0) [0|2500] "rpm" Vector__XXX
SG_ EngRqedTorqueCtrlRngLowerLmt : 208|8@1+ (1,-125) [-125|125] "%" Vector__XXX
SG_ EngRqedTorqueCtrlRngUpperLmt : 216|8@1+ (1,-125) [-125|125] "%" Vector__XXX
SG_ EngRequestSpeedCtrlRngUpLmtExRng : 224|16@1+ (0.125,0) [0|8031.875] "rpm" Vector__XXX
SG_ EngineMomentOfInertia : 240|16@1+ (0.004,0) [0|257.02] "kg/m^2" Vector__XXX
SG_ EngineDefaultTorqueLimit : 256|16@1+ (1,0) [0|64255] "Nm" Vector__XXX
SG_ SupportVariableRateTSC1Message : 272|8@1+ (1,0) [0|255] "" Vector__XXX
SG_ SupportTSC1ControlPurposeGroup1 : 280|8@1+ (1,0) [0|255] "" Vector__XXX
SG_ SupportTSC1ControlPurposeGroup2 : 288|8@1+ (1,0) [0|255] "" Vector__XXX
SG_ SupportTSC1ControlPurposeGroup3 : 296|8@1+ (1,0) [0|255] "" Vector__XXX
SG_ SupportTSC1ControlPurposeGroup4 : 304|8@1+ (1,0) [0|255] "" Vector__XXX
SG_ EngineDefaultIdleTorqueLimit : 312|8@1+ (1,-125) [-125|125] "%" Vector__XXX

BO_ 2566841598 SHUTDN: 8 Vector__XXX
SG_ EngIdleShutdownHasShutdownEngine : 0|2@1+ (1,0) [0|3] "" Vector__XXX
SG_ EngineIdleShutdownDrvrAlertMode : 2|2@1+ (1,0) [0|3] "" Vector__XXX
SG_ EngineIdleShutdownTimerOverride : 4|2@1+ (1,0) [0|3] "" Vector__XXX
SG_ EngineIdleShutdownTimerState : 6|2@1+ (1,0) [0|3] "" Vector__XXX
SG_ EngineIdleShutdownTimerFunction : 14|2@1+ (1,0) [0|3] "" Vector__XXX
SG_ ACHighPressureFanSwitch : 16|2@1+ (1,0) [0|3] "" Vector__XXX
SG_ RefrigerantLowPressureSwitch : 18|2@1+ (1,0) [0|3] "" Vector__XXX
SG_ RefrigerantHighPressureSwitch : 20|2@1+ (1,0) [0|3] "" Vector__XXX
SG_ EngineWaitToStartLamp : 24|2@1+ (1,0) [0|3] "" Vector__XXX
SG_ EngPrtctnSystemHasShutdownEng : 32|2@1+ (1,0) [0|3] "" Vector__XXX
SG_ EngPrtctnSystemApproachingShtdwn : 34|2@1+ (1,0) [0|3] "" Vector__XXX
SG_ EngProtectionSystemTimerOverride : 36|2@1+ (1,0) [0|3] "" Vector__XXX
SG_ EngineProtectionSystemTimerState : 38|2@1+ (1,0) [0|3] "" Vector__XXX
SG_ EngineProtectionSystemConf : 46|2@1+ (1,0) [0|3] "" Vector__XXX
SG_ EngineAlarmAcknowledge : 48|2@1+ (1,0) [0|3] "" Vector__XXX
SG_ EngineAlarmOutputCommandStatus : 50|2@1+ (1,0) [0|3] "" Vector__XXX
SG_ EngineAirShutoffCommandStatus : 52|2@1+ (1,0) [0|3] "" Vector__XXX
SG_ EngineOverspeedTest : 54|2@1+ (1,0) [0|3] "" Vector__XXX
SG_ EngineAirShutoffStatus : 56|2@1+ (1,0) [0|3] "" Vector__XXX
SG_ PTOShutdownHasShutdownEngine : 58|2@1+ (1,0) [0|3] "" Vector__XXX
SG_ CoolntLvlEngPrtctnShutdownStatus : 60|2@1+ (1,0) [0|3] "" Vector__XXX
SG_ EngineOilPressureSwitch : 62|2@1+ (1,0) [0|3] "" Vector__XXX

BO_ 2566841854 HOURS: 8 Vector__XXX
SG_ EngineTotalHoursOfOperation : 0|32@1+ (0.05,0) [0|210554060.75] "h" Vector__XXX
SG_ EngineTotalRevolutions : 32|32@1+ (1000,0) [0|4211081215000] "r" Vector__XXX

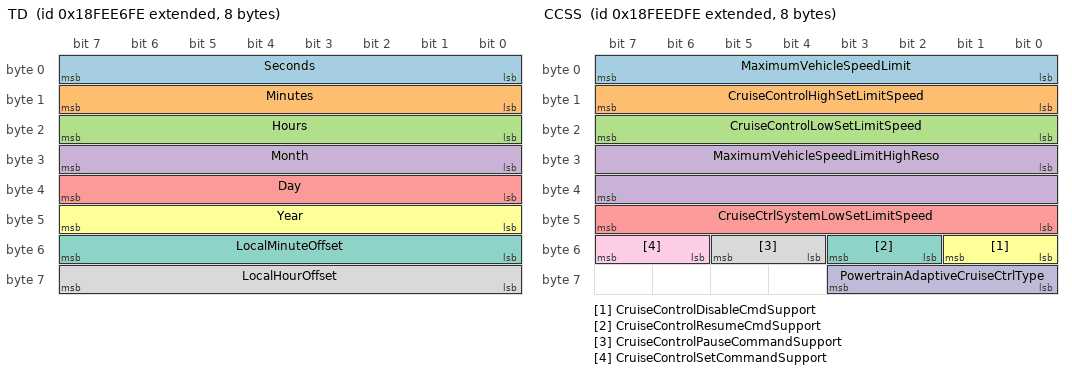
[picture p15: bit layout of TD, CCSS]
BO_ 2566842110 TD: 8 Vector__XXX
SG_ Seconds : 0|8@1+ (0.25,0) [0|62.5] "s" Vector__XXX
SG_ Minutes : 8|8@1+ (1,0) [0|250] "min" Vector__XXX
SG_ Hours : 16|8@1+ (1,0) [0|250] "h" Vector__XXX
SG_ Month : 24|8@1+ (1,0) [0|250] "Months" Vector__XXX
SG_ Day : 32|8@1+ (0.25,0) [0|62.5] "Days" Vector__XXX
SG_ Year : 40|8@1+ (1,1985) [1985|2235] "Years" Vector__XXX
SG_ LocalMinuteOffset : 48|8@1+ (1,-125) [-125|125] "min" Vector__XXX
SG_ LocalHourOffset : 56|8@1+ (1,-125) [-125|125] "h" Vector__XXX

BO_ 2566842366 VH: 8 Vector__XXX
SG_ TotalVehicleHours : 0|32@1+ (0.05,0) [0|210554060.75] "h" Vector__XXX
SG_ TotalPowerTakeoffHours : 32|32@1+ (0.05,0) [0|210554060.75] "h" Vector__XXX

BO_ 2566842622 VDS: 8 Vector__XXX
SG_ CompassBearing : 0|16@1+ (0.0078125,0) [0|501.99] "deg" Vector__XXX
SG_ NavigationBasedVehicleSpeed : 16|16@1+ (0.00390625,0) [0|250.996] "km/h" Vector__XXX
SG_ Pitch : 32|16@1+ (0.0078125,-200) [-200|301.99] "deg" Vector__XXX
SG_ Altitude : 48|16@1+ (0.125,-2500) [-2500|5531.875] "m" Vector__XXX

BO_ 2566842878 LFC1: 8 Vector__XXX
SG_ EngineTripFuel : 0|32@1+ (0.5,0) [0|2105540607.5] "l" Vector__XXX
SG_ EngineTotalFuelUsed : 32|32@1+ (0.5,0) [0|2105540607.5] "l" Vector__XXX

BO_ 2566843134 VW: 8 Vector__XXX
SG_ AxleLocation : 0|8@1+ (1,0) [0|255] "" Vector__XXX
SG_ AxleWeight : 8|16@1+ (0.5,0) [0|32127.5] "kg" Vector__XXX
SG_ TrailerWeight : 24|16@1+ (2,0) [0|128510] "kg" Vector__XXX
SG_ CargoWeight : 40|16@1+ (2,0) [0|128510] "kg" Vector__XXX

BO_ 2566843390 CI: 8 Vector__XXX

BO_ 2566843646 VI: 200 Vector__XXX
SG_ VehicleIdentificationNumber : 7|1600@0+ (1,0) [0|0] "ASCII" Vector__XXX

BO_ 2566843902 CCSS: 8 Vector__XXX
SG_ MaximumVehicleSpeedLimit : 0|8@1+ (1,0) [0|250] "km/h" Vector__XXX
SG_ CruiseControlHighSetLimitSpeed : 8|8@1+ (1,0) [0|250] "km/h" Vector__XXX
SG_ CruiseControlLowSetLimitSpeed : 16|8@1+ (1,0) [0|250] "km/h" Vector__XXX
SG_ MaximumVehicleSpeedLimitHighReso : 24|16@1+ (0.00390625,0) [0|250.996] "km/h" Vector__XXX
SG_ CruiseCtrlSystemLowSetLimitSpeed : 40|8@1+ (1,0) [0|250] "km/h" Vector__XXX
SG_ CruiseControlDisableCmdSupport : 48|2@1+ (1,0) [0|3] "" Vector__XXX
SG_ CruiseControlResumeCmdSupport : 50|2@1+ (1,0) [0|3] "" Vector__XXX
SG_ CruiseControlPauseCommandSupport : 52|2@1+ (1,0) [0|3] "" Vector__XXX
SG_ CruiseControlSetCommandSupport : 54|2@1+ (1,0) [0|3] "" Vector__XXX
SG_ PowertrainAdaptiveCruiseCtrlType : 56|4@1+ (1,0) [0|15] "" Vector__XXX

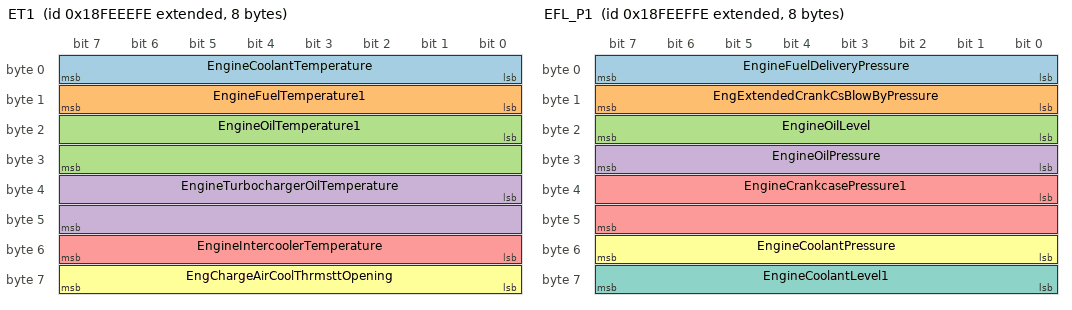
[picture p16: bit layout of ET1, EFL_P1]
BO_ 2566844158 ET1: 8 Vector__XXX
SG_ EngineCoolantTemperature : 0|8@1+ (1,-40) [-40|210] "deg C" Vector__XXX
SG_ EngineFuelTemperature1 : 8|8@1+ (1,-40) [-40|210] "deg C" Vector__XXX
SG_ EngineOilTemperature1 : 16|16@1+ (0.03125,-273) [-273|1734.96875] "deg C" Vector__XXX
SG_ EngineTurbochargerOilTemperature : 32|16@1+ (0.03125,-273) [-273|1734.96875] "deg C" Vector__XXX
SG_ EngineIntercoolerTemperature : 48|8@1+ (1,-40) [-40|210] "deg C" Vector__XXX
SG_ EngChargeAirCoolThrmsttOpening : 56|8@1+ (0.4,0) [0|100] "%" Vector__XXX

BO_ 2566844414 EFL_P1: 8 Vector__XXX
SG_ EngineFuelDeliveryPressure : 0|8@1+ (4,0) [0|1000] "kPa" Vector__XXX
SG_ EngExtendedCrankCsBlowByPressure : 8|8@1+ (0.05,0) [0|12.5] "kPa" Vector__XXX
SG_ EngineOilLevel : 16|8@1+ (0.4,0) [0|100] "%" Vector__XXX
SG_ EngineOilPressure : 24|8@1+ (4,0) [0|1000] "kPa" Vector__XXX
SG_ EngineCrankcasePressure1 : 32|16@1+ (0.0078125,-250) [-250|251.99] "kPa" Vector__XXX
SG_ EngineCoolantPressure : 48|8@1+ (2,0) [0|500] "kPa" Vector__XXX
SG_ EngineCoolantLevel1 : 56|8@1+ (0.4,0) [0|100] "%" Vector__XXX

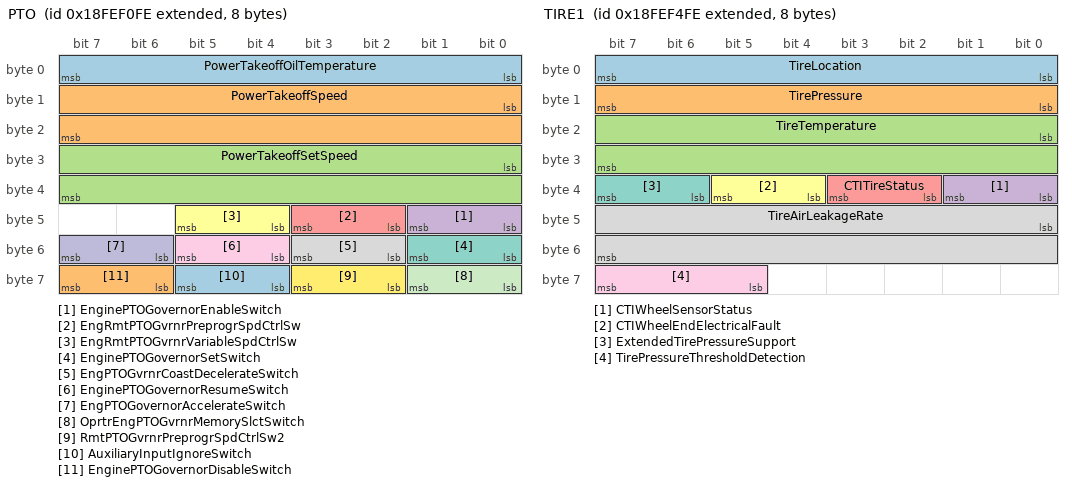
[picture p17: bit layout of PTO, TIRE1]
BO_ 2566844670 PTO: 8 Vector__XXX
SG_ PowerTakeoffOilTemperature : 0|8@1+ (1,-40) [-40|210] "deg C" Vector__XXX
SG_ PowerTakeoffSpeed : 8|16@1+ (0.125,0) [0|8031.875] "rpm" Vector__XXX
SG_ PowerTakeoffSetSpeed : 24|16@1+ (0.125,0) [0|8031.875] "rpm" Vector__XXX
SG_ EnginePTOGovernorEnableSwitch : 40|2@1+ (1,0) [0|3] "" Vector__XXX
SG_ EngRmtPTOGvrnrPreprogrSpdCtrlSw : 42|2@1+ (1,0) [0|3] "" Vector__XXX
SG_ EngRmtPTOGvrnrVariableSpdCtrlSw : 44|2@1+ (1,0) [0|3] "" Vector__XXX
SG_ EnginePTOGovernorSetSwitch : 48|2@1+ (1,0) [0|3] "" Vector__XXX
SG_ EngPTOGvrnrCoastDecelerateSwitch : 50|2@1+ (1,0) [0|3] "" Vector__XXX
SG_ EnginePTOGovernorResumeSwitch : 52|2@1+ (1,0) [0|3] "" Vector__XXX
SG_ EngPTOGovernorAccelerateSwitch : 54|2@1+ (1,0) [0|3] "" Vector__XXX
SG_ OprtrEngPTOGvrnrMemorySlctSwitch : 56|2@1+ (1,0) [0|3] "" Vector__XXX
SG_ RmtPTOGvrnrPreprogrSpdCtrlSw2 : 58|2@1+ (1,0) [0|3] "" Vector__XXX
SG_ AuxiliaryInputIgnoreSwitch : 60|2@1+ (1,0) [0|3] "" Vector__XXX
SG_ EnginePTOGovernorDisableSwitch : 62|2@1+ (1,0) [0|3] "" Vector__XXX

BO_ 2566844926 CCVS1: 8 Vector__XXX
SG_ TwoSpeedAxleSwitch : 0|2@1+ (1,0) [0|3] "" Vector__XXX
SG_ ParkingBrakeSwitch : 2|2@1+ (1,0) [0|3] "" Vector__XXX
SG_ CruiseControlPauseSwitch : 4|2@1+ (1,0) [0|3] "" Vector__XXX
SG_ ParkBrakeReleaseInhibitRequest : 6|2@1+ (1,0) [0|3] "" Vector__XXX
SG_ WheelBasedVehicleSpeed : 8|16@1+ (0.00390625,0) [0|250.996] "km/h" Vector__XXX
SG_ CruiseControlActive : 24|2@1+ (1,0) [0|3] "" Vector__XXX
SG_ CruiseControlEnableSwitch : 26|2@1+ (1,0) [0|3] "" Vector__XXX
SG_ BrakeSwitch : 28|2@1+ (1,0) [0|3] "" Vector__XXX
SG_ ClutchSwitch : 30|2@1+ (1,0) [0|3] "" Vector__XXX
SG_ CruiseControlSetSwitch : 32|2@1+ (1,0) [0|3] "" Vector__XXX
SG_ CruiseControlCoastSwitch : 34|2@1+ (1,0) [0|3] "" Vector__XXX
SG_ CruiseControlResumeSwitch : 36|2@1+ (1,0) [0|3] "" Vector__XXX
SG_ CruiseControlAccelerateSwitch : 38|2@1+ (1,0) [0|3] "" Vector__XXX
SG_ CruiseControlSetSpeed : 40|8@1+ (1,0) [0|250] "km/h" Vector__XXX
SG_ PTOGovernorState : 48|5@1+ (1,0) [0|31] "" Vector__XXX
SG_ CruiseControlStates : 53|3@1+ (1,0) [0|7] "" Vector__XXX
SG_ EngineIdleIncrementSwitch : 56|2@1+ (1,0) [0|3] "" Vector__XXX
SG_ EngineIdleDecrementSwitch : 58|2@1+ (1,0) [0|3] "" Vector__XXX
SG_ EngineDiagnosticTestModeSwitch : 60|2@1+ (1,0) [0|3] "" Vector__XXX
SG_ EngineShutdownOverrideSwitch : 62|2@1+ (1,0) [0|3] "" Vector__XXX

BO_ 2566845182 LFE1: 8 Vector__XXX
SG_ EngineFuelRate : 0|16@1+ (0.05,0) [0|3212.75] "l/h" Vector__XXX
SG_ EngineInstantaneousFuelEconomy : 16|16@1+ (0.001953125,0) [0|125.498046875] "km/l" Vector__XXX
SG_ EngineAverageFuelEconomy : 32|16@1+ (0.001953125,0) [0|125.498046875] "km/l" Vector__XXX
SG_ EngineThrottleValve1Position1 : 48|8@1+ (0.4,0) [0|100] "%" Vector__XXX
SG_ EngineThrottleValve2Position : 56|8@1+ (0.4,0) [0|100] "%" Vector__XXX

BO_ 2566845438 VP1: 8 Vector__XXX
SG_ Latitude : 0|32@1+ (1E-007,-210) [-210|211.1081215] "deg" Vector__XXX
SG_ Longitude : 32|32@1+ (1E-007,-210) [-210|211.1081215] "deg" Vector__XXX

BO_ 2566845694 TIRE1: 8 Vector__XXX
SG_ TireLocation : 0|8@1+ (1,0) [0|255] "" Vector__XXX
SG_ TirePressure : 8|8@1+ (4,0) [0|1000] "kPa" Vector__XXX
SG_ TireTemperature : 16|16@1+ (0.03125,-273) [-273|1734.96875] "deg C" Vector__XXX
SG_ CTIWheelSensorStatus : 32|2@1+ (1,0) [0|3] "" Vector__XXX
SG_ CTITireStatus : 34|2@1+ (1,0) [0|3] "" Vector__XXX
SG_ CTIWheelEndElectricalFault : 36|2@1+ (1,0) [0|3] "" Vector__XXX
SG_ ExtendedTirePressureSupport : 38|2@1+ (1,0) [0|3] "" Vector__XXX
SG_ TireAirLeakageRate : 40|16@1+ (0.1,0) [0|6425.5] "Pa/s" Vector__XXX
SG_ TirePressureThresholdDetection : 61|3@1+ (1,0) [0|7] "" Vector__XXX

BO_ 2566845950 AMB: 8 Vector__XXX
SG_ BarometricPressure : 0|8@1+ (0.5,0) [0|125] "kPa" Vector__XXX
SG_ CabInteriorTemperature : 8|16@1+ (0.03125,-273) [-273|1734.96875] "deg C" Vector__XXX
SG_ AmbientAirTemperature : 24|16@1+ (0.03125,-273) [-273|1734.96875] "deg C" Vector__XXX
SG_ EngineIntakeAirTemperature : 40|8@1+ (1,-40) [-40|210] "deg C" Vector__XXX
SG_ RoadSurfaceTemperature : 48|16@1+ (0.03125,-273) [-273|1734.96875] "deg C" Vector__XXX

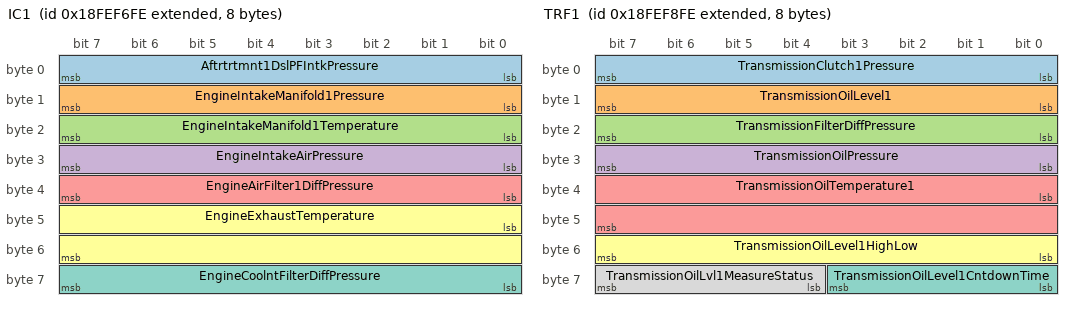
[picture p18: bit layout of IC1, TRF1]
BO_ 2566846206 IC1: 8 Vector__XXX
SG_ Aftrtrtmnt1DslPFIntkPressure : 0|8@1+ (0.5,0) [0|125] "kPa" Vector__XXX
SG_ EngineIntakeManifold1Pressure : 8|8@1+ (2,0) [0|500] "kPa" Vector__XXX
SG_ EngineIntakeManifold1Temperature : 16|8@1+ (1,-40) [-40|210] "deg C" Vector__XXX
SG_ EngineIntakeAirPressure : 24|8@1+ (2,0) [0|500] "kPa" Vector__XXX
SG_ EngineAirFilter1DiffPressure : 32|8@1+ (0.05,0) [0|12.5] "kPa" Vector__XXX
SG_ EngineExhaustTemperature : 40|16@1+ (0.03125,-273) [-273|1734.96875] "deg C" Vector__XXX
SG_ EngineCoolntFilterDiffPressure : 56|8@1+ (0.5,0) [0|125] "kPa" Vector__XXX

BO_ 2566846462 VEP1: 8 Vector__XXX
SG_ NetBatteryCurrent : 0|8@1+ (1,-125) [-125|125] "A" Vector__XXX
SG_ AlternatorCurrent : 8|8@1+ (1,0) [0|250] "A" Vector__XXX
SG_ ChargingSystemPotential : 16|16@1+ (0.05,0) [0|3212.75] "V" Vector__XXX
SG_ BatteryPotentialPowerInput1 : 32|16@1+ (0.05,0) [0|3212.75] "V" Vector__XXX
SG_ KeyswitchBatteryPotential : 48|16@1+ (0.05,0) [0|3212.75] "V" Vector__XXX

BO_ 2566846718 TRF1: 8 Vector__XXX
SG_ TransmissionClutch1Pressure : 0|8@1+ (16,0) [0|4000] "kPa" Vector__XXX
SG_ TransmissionOilLevel1 : 8|8@1+ (0.4,0) [0|100] "%" Vector__XXX
SG_ TransmissionFilterDiffPressure : 16|8@1+ (2,0) [0|500] "kPa" Vector__XXX
SG_ TransmissionOilPressure : 24|8@1+ (16,0) [0|4000] "kPa" Vector__XXX
SG_ TransmissionOilTemperature1 : 32|16@1+ (0.03125,-273) [-273|1734.96875] "deg C" Vector__XXX
SG_ TransmissionOilLevel1HighLow : 48|8@1+ (0.5,-62.5) [-62.5|62.5] "l" Vector__XXX
SG_ TransmissionOilLevel1CntdownTime : 56|4@1+ (1,0) [0|15] "" Vector__XXX
SG_ TransmissionOilLvl1MeasureStatus : 60|4@1+ (1,0) [0|15] "" Vector__XXX

BO_ 2566846974 AI: 8 Vector__XXX
SG_ SteeringAxleTemperature : 0|8@1+ (1,-40) [-40|210] "deg C" Vector__XXX
SG_ DriveAxleLocation : 8|8@1+ (1,0) [0|255] "" Vector__XXX
SG_ DriveAxleLiftAirPressure : 16|8@1+ (4,0) [0|1000] "kPa" Vector__XXX
SG_ DriveAxleTemperature : 24|8@1+ (1,-40) [-40|210] "deg C" Vector__XXX
SG_ DriveAxleLubePressure : 32|8@1+ (4,0) [0|1000] "kPa" Vector__XXX
SG_ SteeringAxleLubePressure : 56|8@1+ (4,0) [0|1000] "kPa" Vector__XXX

BO_ 2566847230 B1: 8 Vector__XXX
SG_ BrakeApplicationPressure : 0|8@1+ (4,0) [0|1000] "kPa" Vector__XXX
SG_ BrakePrimaryPressure : 8|8@1+ (4,0) [0|1000] "kPa" Vector__XXX
SG_ BrakeSecondaryPressure : 16|8@1+ (4,0) [0|1000] "kPa" Vector__XXX
SG_ ParkingBrakeActuator : 24|2@1+ (1,0) [0|3] "" Vector__XXX
SG_ ParkingBrakeRedWarningSignal : 26|2@1+ (1,0) [0|3] "" Vector__XXX
SG_ ParkBrakeReleaseInhibitStatus : 28|2@1+ (1,0) [0|3] "" Vector__XXX

BO_ 2566847486 RF: 8 Vector__XXX
SG_ HydraulicRetarderPressure : 0|8@1+ (16,0) [0|4000] "kPa" Vector__XXX
SG_ HydraulicRetarderOilTemperature : 8|8@1+ (1,-40) [-40|210] "deg C" Vector__XXX
SG_ DrvlineRetarderOverheatIndicator : 16|2@1+ (1,0) [0|3] "" Vector__XXX
SG_ RetarderCoolantOutletTemperature : 24|8@1+ (1,-40) [-40|210] "deg C" Vector__XXX

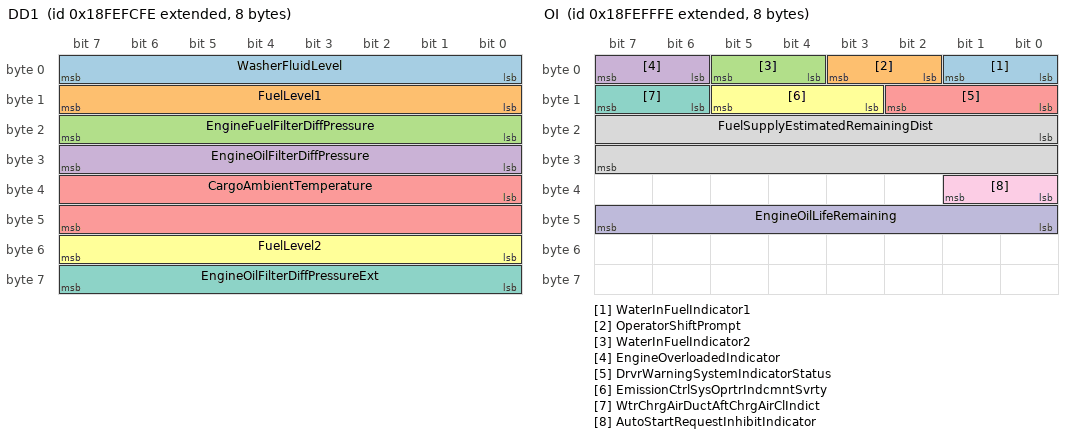
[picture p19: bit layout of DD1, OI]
BO_ 2566847742 DD1: 8 Vector__XXX
SG_ WasherFluidLevel : 0|8@1+ (0.4,0) [0|100] "%" Vector__XXX
SG_ FuelLevel1 : 8|8@1+ (0.4,0) [0|100] "%" Vector__XXX
SG_ EngineFuelFilterDiffPressure : 16|8@1+ (2,0) [0|500] "kPa" Vector__XXX
SG_ EngineOilFilterDiffPressure : 24|8@1+ (0.5,0) [0|125] "kPa" Vector__XXX
SG_ CargoAmbientTemperature : 32|16@1+ (0.03125,-273) [-273|1734.96875] "deg C" Vector__XXX
SG_ FuelLevel2 : 48|8@1+ (0.4,0) [0|100] "%" Vector__XXX
SG_ EngineOilFilterDiffPressureExt : 56|8@1+ (5,0) [0|1250] "kPa" Vector__XXX

BO_ 2566847998 AF1: 8 Vector__XXX
SG_ EngineBlowerBypassValvePosition : 0|8@1+ (0.4,0) [0|100] "%" Vector__XXX
SG_ EngineGasSupplyPressure : 8|16@1+ (0.5,0) [0|32127.5] "kPa" Vector__XXX
SG_ EngineGaseousFuelVentPressure : 24|16@1+ (0.5,0) [0|32127.5] "kPa" Vector__XXX
SG_ LNGVaporizerCoolntOtltTemp : 40|8@1+ (1,-40) [-40|210] "deg C" Vector__XXX
SG_ EngGsFuelPressRegulatorIntkPress : 48|16@1+ (1,0) [0|64255] "kPa" Vector__XXX

BO_ 2566848254 AWPP: 8 Vector__XXX
SG_ AuxiliaryPumpPressure : 0|8@1+ (16,0) [0|4000] "kPa" Vector__XXX

BO_ 2566848510 OI: 8 Vector__XXX
SG_ WaterInFuelIndicator1 : 0|2@1+ (1,0) [0|3] "" Vector__XXX
SG_ OperatorShiftPrompt : 2|2@1+ (1,0) [0|3] "" Vector__XXX
SG_ WaterInFuelIndicator2 : 4|2@1+ (1,0) [0|3] "" Vector__XXX
SG_ EngineOverloadedIndicator : 6|2@1+ (1,0) [0|3] "" Vector__XXX
SG_ DrvrWarningSystemIndicatorStatus : 8|3@1+ (1,0) [0|7] "" Vector__XXX
SG_ EmissionCtrlSysOprtrIndcmntSvrty : 11|3@1+ (1,0) [0|7] "" Vector__XXX
SG_ WtrChrgAirDuctAftChrgAirClIndict : 14|2@1+ (1,0) [0|3] "" Vector__XXX
SG_ FuelSupplyEstimatedRemainingDist : 16|16@1+ (1,0) [0|64255] "km" Vector__XXX
SG_ AutoStartRequestInhibitIndicator : 32|2@1+ (1,0) [0|3] "" Vector__XXX
SG_ EngineOilLifeRemaining : 40|8@1+ (0.4,0) [0|100] "%" Vector__XXX

BO_ 2566848766 PropB_00: 1785 Vector__XXX

BO_ 2566849022 PropB_01: 1785 Vector__XXX

BO_ 2566849278 PropB_02: 1785 Vector__XXX

BO_ 2566849534 PropB_03: 1785 Vector__XXX

BO_ 2566849790 PropB_04: 1785 Vector__XXX

BO_ 2566850046 PropB_05: 1785 Vector__XXX

BO_ 2566850302 PropB_06: 1785 Vector__XXX

BO_ 2566850558 PropB_07: 1785 Vector__XXX

BO_ 2566850814 PropB_08: 1785 Vector__XXX

BO_ 2566851070 PropB_09: 1785 Vector__XXX

BO_ 2566851326 PropB_0A: 1785 Vector__XXX

BO_ 2566851582 PropB_0B: 1785 Vector__XXX

BO_ 2566851838 PropB_0C: 1785 Vector__XXX

BO_ 2566852094 PropB_0D: 1785 Vector__XXX

BO_ 2566852350 PropB_0E: 1785 Vector__XXX

BO_ 2566852606 PropB_0F: 1785 Vector__XXX

BO_ 2566852862 PropB_10: 1785 Vector__XXX

BO_ 2566853118 PropB_11: 1785 Vector__XXX

BO_ 2566853374 PropB_12: 1785 Vector__XXX

BO_ 2566853630 PropB_13: 1785 Vector__XXX

BO_ 2566853886 PropB_14: 1785 Vector__XXX

BO_ 2566854142 PropB_15: 1785 Vector__XXX

BO_ 2566854398 PropB_16: 1785 Vector__XXX

BO_ 2566854654 PropB_17: 1785 Vector__XXX

BO_ 2566854910 PropB_18: 1785 Vector__XXX

BO_ 2566855166 PropB_19: 1785 Vector__XXX

BO_ 2566855422 PropB_1A: 1785 Vector__XXX

BO_ 2566855678 PropB_1B: 1785 Vector__XXX

BO_ 2566855934 PropB_1C: 1785 Vector__XXX

BO_ 2566856190 PropB_1D: 1785 Vector__XXX

BO_ 2566856446 PropB_1E: 1785 Vector__XXX

BO_ 2566856702 PropB_1F: 1785 Vector__XXX

BO_ 2566856958 PropB_20: 1785 Vector__XXX

BO_ 2566857214 PropB_21: 1785 Vector__XXX

BO_ 2566857470 PropB_22: 1785 Vector__XXX

BO_ 2566857726 PropB_23: 1785 Vector__XXX

BO_ 2566857982 PropB_24: 1785 Vector__XXX

BO_ 2566858238 PropB_25: 1785 Vector__XXX

BO_ 2566858494 PropB_26: 1785 Vector__XXX

BO_ 2566858750 PropB_27: 1785 Vector__XXX

BO_ 2566859006 PropB_28: 1785 Vector__XXX

BO_ 2566859262 PropB_29: 1785 Vector__XXX

BO_ 2566859518 PropB_2A: 1785 Vector__XXX

BO_ 2566859774 PropB_2B: 1785 Vector__XXX

BO_ 2566860030 PropB_2C: 1785 Vector__XXX

BO_ 2566860286 PropB_2D: 1785 Vector__XXX

BO_ 2566860542 PropB_2E: 1785 Vector__XXX

BO_ 2566860798 PropB_2F: 1785 Vector__XXX

BO_ 2566861054 PropB_30: 1785 Vector__XXX

BO_ 2566861310 PropB_31: 1785 Vector__XXX

BO_ 2566861566 PropB_32: 1785 Vector__XXX

BO_ 2566861822 PropB_33: 1785 Vector__XXX

BO_ 2566862078 PropB_34: 1785 Vector__XXX

BO_ 2566862334 PropB_35: 1785 Vector__XXX

BO_ 2566862590 PropB_36: 1785 Vector__XXX

BO_ 2566862846 PropB_37: 1785 Vector__XXX

BO_ 2566863102 PropB_38: 1785 Vector__XXX

BO_ 2566863358 PropB_39: 1785 Vector__XXX

BO_ 2566863614 PropB_3A: 1785 Vector__XXX

BO_ 2566863870 PropB_3B: 1785 Vector__XXX

BO_ 2566864126 PropB_3C: 1785 Vector__XXX

BO_ 2566864382 PropB_3D: 1785 Vector__XXX

BO_ 2566864638 PropB_3E: 1785 Vector__XXX

BO_ 2566864894 PropB_3F: 1785 Vector__XXX

BO_ 2566865150 PropB_40: 1785 Vector__XXX

BO_ 2566865406 PropB_41: 1785 Vector__XXX

BO_ 2566865662 PropB_42: 1785 Vector__XXX

BO_ 2566865918 PropB_43: 1785 Vector__XXX

BO_ 2566866174 PropB_44: 1785 Vector__XXX

BO_ 2566866430 PropB_45: 1785 Vector__XXX

BO_ 2566866686 PropB_46: 1785 Vector__XXX

BO_ 2566866942 PropB_47: 1785 Vector__XXX

BO_ 2566867198 PropB_48: 1785 Vector__XXX

BO_ 2566867454 PropB_49: 1785 Vector__XXX

BO_ 2566867710 PropB_4A: 1785 Vector__XXX

BO_ 2566867966 PropB_4B: 1785 Vector__XXX

BO_ 2566868222 PropB_4C: 1785 Vector__XXX

BO_ 2566868478 PropB_4D: 1785 Vector__XXX

BO_ 2566868734 PropB_4E: 1785 Vector__XXX

BO_ 2566868990 PropB_4F: 1785 Vector__XXX

BO_ 2566869246 PropB_50: 1785 Vector__XXX

BO_ 2566869502 PropB_51: 1785 Vector__XXX

BO_ 2566869758 PropB_52: 1785 Vector__XXX

BO_ 2566870014 PropB_53: 1785 Vector__XXX

BO_ 2566870270 PropB_54: 1785 Vector__XXX

BO_ 2566870526 PropB_55: 1785 Vector__XXX

BO_ 2566870782 PropB_56: 1785 Vector__XXX

BO_ 2566871038 PropB_57: 1785 Vector__XXX

BO_ 2566871294 PropB_58: 1785 Vector__XXX

BO_ 2566871550 PropB_59: 1785 Vector__XXX

BO_ 2566871806 PropB_5A: 1785 Vector__XXX

BO_ 2566872062 PropB_5B: 1785 Vector__XXX

BO_ 2566872318 PropB_5C: 1785 Vector__XXX

BO_ 2566872574 PropB_5D: 1785 Vector__XXX

BO_ 2566872830 PropB_5E: 1785 Vector__XXX

BO_ 2566873086 PropB_5F: 1785 Vector__XXX

BO_ 2566873342 PropB_60: 1785 Vector__XXX

BO_ 2566873598 PropB_61: 1785 Vector__XXX

BO_ 2566873854 PropB_62: 1785 Vector__XXX

BO_ 2566874110 PropB_63: 1785 Vector__XXX

BO_ 2566874366 PropB_64: 1785 Vector__XXX

BO_ 2566874622 PropB_65: 1785 Vector__XXX

BO_ 2566874878 PropB_66: 1785 Vector__XXX

BO_ 2566875134 PropB_67: 1785 Vector__XXX

BO_ 2566875390 PropB_68: 1785 Vector__XXX

BO_ 2566875646 PropB_69: 1785 Vector__XXX

BO_ 2566875902 PropB_6A: 1785 Vector__XXX

BO_ 2566876158 PropB_6B: 1785 Vector__XXX

BO_ 2566876414 PropB_6C: 1785 Vector__XXX

BO_ 2566876670 PropB_6D: 1785 Vector__XXX

BO_ 2566876926 PropB_6E: 1785 Vector__XXX

BO_ 2566877182 PropB_6F: 1785 Vector__XXX

BO_ 2566877438 PropB_70: 1785 Vector__XXX

BO_ 2566877694 PropB_71: 1785 Vector__XXX

BO_ 2566877950 PropB_72: 1785 Vector__XXX

BO_ 2566878206 PropB_73: 1785 Vector__XXX

BO_ 2566878462 PropB_74: 1785 Vector__XXX

BO_ 2566878718 PropB_75: 1785 Vector__XXX

BO_ 2566878974 PropB_76: 1785 Vector__XXX

BO_ 2566879230 PropB_77: 1785 Vector__XXX

BO_ 2566879486 PropB_78: 1785 Vector__XXX

BO_ 2566879742 PropB_79: 1785 Vector__XXX

BO_ 2566879998 PropB_7A: 1785 Vector__XXX

BO_ 2566880254 PropB_7B: 1785 Vector__XXX

BO_ 2566880510 PropB_7C: 1785 Vector__XXX

BO_ 2566880766 PropB_7D: 1785 Vector__XXX

BO_ 2566881022 PropB_7E: 1785 Vector__XXX

BO_ 2566881278 PropB_7F: 1785 Vector__XXX

BO_ 2566881534 PropB_80: 1785 Vector__XXX

BO_ 2566881790 PropB_81: 1785 Vector__XXX

BO_ 2566882046 PropB_82: 1785 Vector__XXX

BO_ 2566882302 PropB_83: 1785 Vector__XXX

BO_ 2566882558 PropB_84: 1785 Vector__XXX

BO_ 2566882814 PropB_85: 1785 Vector__XXX

BO_ 2566883070 PropB_86: 1785 Vector__XXX

BO_ 2566883326 PropB_87: 1785 Vector__XXX

BO_ 2566883582 PropB_88: 1785 Vector__XXX

BO_ 2566883838 PropB_89: 1785 Vector__XXX

BO_ 2566884094 PropB_8A: 1785 Vector__XXX

BO_ 2566884350 PropB_8B: 1785 Vector__XXX

BO_ 2566884606 PropB_8C: 1785 Vector__XXX

BO_ 2566884862 PropB_8D: 1785 Vector__XXX

BO_ 2566885118 PropB_8E: 1785 Vector__XXX

BO_ 2566885374 PropB_8F: 1785 Vector__XXX

BO_ 2566885630 PropB_90: 1785 Vector__XXX

BO_ 2566885886 PropB_91: 1785 Vector__XXX

BO_ 2566886142 PropB_92: 1785 Vector__XXX

BO_ 2566886398 PropB_93: 1785 Vector__XXX

BO_ 2566886654 PropB_94: 1785 Vector__XXX

BO_ 2566886910 PropB_95: 1785 Vector__XXX

BO_ 2566887166 PropB_96: 1785 Vector__XXX

BO_ 2566887422 PropB_97: 1785 Vector__XXX

BO_ 2566887678 PropB_98: 1785 Vector__XXX

BO_ 2566887934 PropB_99: 1785 Vector__XXX

BO_ 2566888190 PropB_9A: 1785 Vector__XXX

BO_ 2566888446 PropB_9B: 1785 Vector__XXX

BO_ 2566888702 PropB_9C: 1785 Vector__XXX

BO_ 2566888958 PropB_9D: 1785 Vector__XXX

BO_ 2566889214 PropB_9E: 1785 Vector__XXX

BO_ 2566889470 PropB_9F: 1785 Vector__XXX

BO_ 2566889726 PropB_A0: 1785 Vector__XXX

BO_ 2566889982 PropB_A1: 1785 Vector__XXX

BO_ 2566890238 PropB_A2: 1785 Vector__XXX

BO_ 2566890494 PropB_A3: 1785 Vector__XXX

BO_ 2566890750 PropB_A4: 1785 Vector__XXX

BO_ 2566891006 PropB_A5: 1785 Vector__XXX

BO_ 2566891262 PropB_A6: 1785 Vector__XXX

BO_ 2566891518 PropB_A7: 1785 Vector__XXX

BO_ 2566891774 PropB_A8: 1785 Vector__XXX

BO_ 2566892030 PropB_A9: 1785 Vector__XXX

BO_ 2566892286 PropB_AA: 1785 Vector__XXX

BO_ 2566892542 PropB_AB: 1785 Vector__XXX

BO_ 2566892798 PropB_AC: 1785 Vector__XXX

BO_ 2566893054 PropB_AD: 1785 Vector__XXX

BO_ 2566893310 PropB_AE: 1785 Vector__XXX

BO_ 2566893566 PropB_AF: 1785 Vector__XXX

BO_ 2566893822 PropB_B0: 1785 Vector__XXX

BO_ 2566894078 PropB_B1: 1785 Vector__XXX

BO_ 2566894334 PropB_B2: 1785 Vector__XXX

BO_ 2566894590 PropB_B3: 1785 Vector__XXX

BO_ 2566894846 PropB_B4: 1785 Vector__XXX

BO_ 2566895102 PropB_B5: 1785 Vector__XXX

BO_ 2566895358 PropB_B6: 1785 Vector__XXX

BO_ 2566895614 PropB_B7: 1785 Vector__XXX

BO_ 2566895870 PropB_B8: 1785 Vector__XXX

BO_ 2566896126 PropB_B9: 1785 Vector__XXX

BO_ 2566896382 PropB_BA: 1785 Vector__XXX

BO_ 2566896638 PropB_BB: 1785 Vector__XXX

BO_ 2566896894 PropB_BC: 1785 Vector__XXX

BO_ 2566897150 PropB_BD: 1785 Vector__XXX

BO_ 2566897406 PropB_BE: 1785 Vector__XXX

BO_ 2566897662 PropB_BF: 1785 Vector__XXX

BO_ 2566897918 PropB_C0: 1785 Vector__XXX

BO_ 2566898174 PropB_C1: 1785 Vector__XXX

BO_ 2566898430 PropB_C2: 1785 Vector__XXX

BO_ 2566898686 PropB_C3: 1785 Vector__XXX

BO_ 2566898942 PropB_C4: 1785 Vector__XXX

BO_ 2566899198 PropB_C5: 1785 Vector__XXX

BO_ 2566899454 PropB_C6: 1785 Vector__XXX

BO_ 2566899710 PropB_C7: 1785 Vector__XXX

BO_ 2566899966 PropB_C8: 1785 Vector__XXX

BO_ 2566900222 PropB_C9: 1785 Vector__XXX

BO_ 2566900478 PropB_CA: 1785 Vector__XXX

BO_ 2566900734 PropB_CB: 1785 Vector__XXX

BO_ 2566900990 PropB_CC: 1785 Vector__XXX

BO_ 2566901246 PropB_CD: 1785 Vector__XXX

BO_ 2566901502 PropB_CE: 1785 Vector__XXX

BO_ 2566901758 PropB_CF: 1785 Vector__XXX

BO_ 2566902014 PropB_D0: 1785 Vector__XXX

BO_ 2566902270 PropB_D1: 1785 Vector__XXX

BO_ 2566902526 PropB_D2: 1785 Vector__XXX

BO_ 2566902782 PropB_D3: 1785 Vector__XXX

BO_ 2566903038 PropB_D4: 1785 Vector__XXX

BO_ 2566903294 PropB_D5: 1785 Vector__XXX

BO_ 2566903550 PropB_D6: 1785 Vector__XXX

BO_ 2566903806 PropB_D7: 1785 Vector__XXX

BO_ 2566904062 PropB_D8: 1785 Vector__XXX

BO_ 2566904318 PropB_D9: 1785 Vector__XXX

BO_ 2566904574 PropB_DA: 1785 Vector__XXX

BO_ 2566904830 PropB_DB: 1785 Vector__XXX

BO_ 2566905086 PropB_DC: 1785 Vector__XXX

BO_ 2566905342 PropB_DD: 1785 Vector__XXX

BO_ 2566905598 PropB_DE: 1785 Vector__XXX

BO_ 2566905854 PropB_DF: 1785 Vector__XXX

BO_ 2566906110 PropB_E0: 1785 Vector__XXX

BO_ 2566906366 PropB_E1: 1785 Vector__XXX

BO_ 2566906622 PropB_E2: 1785 Vector__XXX

BO_ 2566906878 PropB_E3: 1785 Vector__XXX

BO_ 2566907134 PropB_E4: 1785 Vector__XXX

BO_ 2566907390 PropB_E5: 1785 Vector__XXX

BO_ 2566907646 PropB_E6: 1785 Vector__XXX

BO_ 2566907902 PropB_E7: 1785 Vector__XXX

BO_ 2566908158 PropB_E8: 1785 Vector__XXX

BO_ 2566908414 PropB_E9: 1785 Vector__XXX

BO_ 2566908670 PropB_EA: 1785 Vector__XXX

BO_ 2566908926 PropB_EB: 1785 Vector__XXX

BO_ 2566909182 PropB_EC: 1785 Vector__XXX

BO_ 2566909438 PropB_ED: 1785 Vector__XXX

BO_ 2566909694 PropB_EE: 1785 Vector__XXX

BO_ 2566909950 PropB_EF: 1785 Vector__XXX

BO_ 2566910206 PropB_F0: 1785 Vector__XXX

BO_ 2566910462 PropB_F1: 1785 Vector__XXX

BO_ 2566910718 PropB_F2: 1785 Vector__XXX

BO_ 2566910974 PropB_F3: 1785 Vector__XXX

BO_ 2566911230 PropB_F4: 1785 Vector__XXX

BO_ 2566911486 PropB_F5: 1785 Vector__XXX

BO_ 2566911742 PropB_F6: 1785 Vector__XXX

BO_ 2566911998 PropB_F7: 1785 Vector__XXX

BO_ 2566912254 PropB_F8: 1785 Vector__XXX

BO_ 2566912510 PropB_F9: 1785 Vector__XXX

BO_ 2566912766 PropB_FA: 1785 Vector__XXX

BO_ 2566913022 PropB_FB: 1785 Vector__XXX

BO_ 2566913278 PropB_FC: 1785 Vector__XXX

BO_ 2566913534 PropB_FD: 1785 Vector__XXX

BO_ 2566913790 PropB_FE: 1785 Vector__XXX

BO_ 2566914046 PropB_FF: 1785 Vector__XXX

BO_ 2582642430 PropA2: 1785 Vector__XXX

BO_ 2583625982 PropB1_00: 1785 Vector__XXX

BO_ 2583626238 PropB1_01: 1785 Vector__XXX

BO_ 2583626494 PropB1_02: 1785 Vector__XXX

BO_ 2583626750 PropB1_03: 1785 Vector__XXX

BO_ 2583627006 PropB1_04: 1785 Vector__XXX

BO_ 2583627262 PropB1_05: 1785 Vector__XXX

BO_ 2583627518 PropB1_06: 1785 Vector__XXX

BO_ 2583627774 PropB1_07: 1785 Vector__XXX

BO_ 2583628030 PropB1_08: 1785 Vector__XXX

BO_ 2583628286 PropB1_09: 1785 Vector__XXX

BO_ 2583628542 PropB1_0A: 1785 Vector__XXX

BO_ 2583628798 PropB1_0B: 1785 Vector__XXX

BO_ 2583629054 PropB1_0C: 1785 Vector__XXX

BO_ 2583629310 PropB1_0D: 1785 Vector__XXX

BO_ 2583629566 PropB1_0E: 1785 Vector__XXX

BO_ 2583629822 PropB1_0F: 1785 Vector__XXX

BO_ 2583630078 PropB1_10: 1785 Vector__XXX

BO_ 2583630334 PropB1_11: 1785 Vector__XXX

BO_ 2583630590 PropB1_12: 1785 Vector__XXX

BO_ 2583630846 PropB1_13: 1785 Vector__XXX

BO_ 2583631102 PropB1_14: 1785 Vector__XXX

BO_ 2583631358 PropB1_15: 1785 Vector__XXX

BO_ 2583631614 PropB1_16: 1785 Vector__XXX

BO_ 2583631870 PropB1_17: 1785 Vector__XXX

BO_ 2583632126 PropB1_18: 1785 Vector__XXX

BO_ 2583632382 PropB1_19: 1785 Vector__XXX

BO_ 2583632638 PropB1_1A: 1785 Vector__XXX

BO_ 2583632894 PropB1_1B: 1785 Vector__XXX

BO_ 2583633150 PropB1_1C: 1785 Vector__XXX

BO_ 2583633406 PropB1_1D: 1785 Vector__XXX

BO_ 2583633662 PropB1_1E: 1785 Vector__XXX

BO_ 2583633918 PropB1_1F: 1785 Vector__XXX

BO_ 2583634174 PropB1_20: 1785 Vector__XXX

BO_ 2583634430 PropB1_21: 1785 Vector__XXX

BO_ 2583634686 PropB1_22: 1785 Vector__XXX

BO_ 2583634942 PropB1_23: 1785 Vector__XXX

BO_ 2583635198 PropB1_24: 1785 Vector__XXX

BO_ 2583635454 PropB1_25: 1785 Vector__XXX

BO_ 2583635710 PropB1_26: 1785 Vector__XXX

BO_ 2583635966 PropB1_27: 1785 Vector__XXX

BO_ 2583636222 PropB1_28: 1785 Vector__XXX

BO_ 2583636478 PropB1_29: 1785 Vector__XXX

BO_ 2583636734 PropB1_2A: 1785 Vector__XXX

BO_ 2583636990 PropB1_2B: 1785 Vector__XXX

BO_ 2583637246 PropB1_2C: 1785 Vector__XXX

BO_ 2583637502 PropB1_2D: 1785 Vector__XXX

BO_ 2583637758 PropB1_2E: 1785 Vector__XXX

BO_ 2583638014 PropB1_2F: 1785 Vector__XXX

BO_ 2583638270 PropB1_30: 1785 Vector__XXX

BO_ 2583638526 PropB1_31: 1785 Vector__XXX

BO_ 2583638782 PropB1_32: 1785 Vector__XXX

BO_ 2583639038 PropB1_33: 1785 Vector__XXX

BO_ 2583639294 PropB1_34: 1785 Vector__XXX

BO_ 2583639550 PropB1_35: 1785 Vector__XXX

BO_ 2583639806 PropB1_36: 1785 Vector__XXX

BO_ 2583640062 PropB1_37: 1785 Vector__XXX

BO_ 2583640318 PropB1_38: 1785 Vector__XXX

BO_ 2583640574 PropB1_39: 1785 Vector__XXX

BO_ 2583640830 PropB1_3A: 1785 Vector__XXX

BO_ 2583641086 PropB1_3B: 1785 Vector__XXX

BO_ 2583641342 PropB1_3C: 1785 Vector__XXX

BO_ 2583641598 PropB1_3D: 1785 Vector__XXX

BO_ 2583641854 PropB1_3E: 1785 Vector__XXX

BO_ 2583642110 PropB1_3F: 1785 Vector__XXX

BO_ 2583642366 PropB1_40: 1785 Vector__XXX

BO_ 2583642622 PropB1_41: 1785 Vector__XXX

BO_ 2583642878 PropB1_42: 1785 Vector__XXX

BO_ 2583643134 PropB1_43: 1785 Vector__XXX

BO_ 2583643390 PropB1_44: 1785 Vector__XXX

BO_ 2583643646 PropB1_45: 1785 Vector__XXX

BO_ 2583643902 PropB1_46: 1785 Vector__XXX

BO_ 2583644158 PropB1_47: 1785 Vector__XXX

BO_ 2583644414 PropB1_48: 1785 Vector__XXX

BO_ 2583644670 PropB1_49: 1785 Vector__XXX

BO_ 2583644926 PropB1_4A: 1785 Vector__XXX

BO_ 2583645182 PropB1_4B: 1785 Vector__XXX

BO_ 2583645438 PropB1_4C: 1785 Vector__XXX

BO_ 2583645694 PropB1_4D: 1785 Vector__XXX

BO_ 2583645950 PropB1_4E: 1785 Vector__XXX

BO_ 2583646206 PropB1_4F: 1785 Vector__XXX

BO_ 2583646462 PropB1_50: 1785 Vector__XXX

BO_ 2583646718 PropB1_51: 1785 Vector__XXX

BO_ 2583646974 PropB1_52: 1785 Vector__XXX

BO_ 2583647230 PropB1_53: 1785 Vector__XXX

BO_ 2583647486 PropB1_54: 1785 Vector__XXX

BO_ 2583647742 PropB1_55: 1785 Vector__XXX

BO_ 2583647998 PropB1_56: 1785 Vector__XXX

BO_ 2583648254 PropB1_57: 1785 Vector__XXX

BO_ 2583648510 PropB1_58: 1785 Vector__XXX

BO_ 2583648766 PropB1_59: 1785 Vector__XXX

BO_ 2583649022 PropB1_5A: 1785 Vector__XXX

BO_ 2583649278 PropB1_5B: 1785 Vector__XXX

BO_ 2583649534 PropB1_5C: 1785 Vector__XXX

BO_ 2583649790 PropB1_5D: 1785 Vector__XXX

BO_ 2583650046 PropB1_5E: 1785 Vector__XXX

BO_ 2583650302 PropB1_5F: 1785 Vector__XXX

BO_ 2583650558 PropB1_60: 1785 Vector__XXX

BO_ 2583650814 PropB1_61: 1785 Vector__XXX

BO_ 2583651070 PropB1_62: 1785 Vector__XXX

BO_ 2583651326 PropB1_63: 1785 Vector__XXX

BO_ 2583651582 PropB1_64: 1785 Vector__XXX

BO_ 2583651838 PropB1_65: 1785 Vector__XXX

BO_ 2583652094 PropB1_66: 1785 Vector__XXX

BO_ 2583652350 PropB1_67: 1785 Vector__XXX

BO_ 2583652606 PropB1_68: 1785 Vector__XXX

BO_ 2583652862 PropB1_69: 1785 Vector__XXX

BO_ 2583653118 PropB1_6A: 1785 Vector__XXX

BO_ 2583653374 PropB1_6B: 1785 Vector__XXX

BO_ 2583653630 PropB1_6C: 1785 Vector__XXX

BO_ 2583653886 PropB1_6D: 1785 Vector__XXX

BO_ 2583654142 PropB1_6E: 1785 Vector__XXX

BO_ 2583654398 PropB1_6F: 1785 Vector__XXX

BO_ 2583654654 PropB1_70: 1785 Vector__XXX

BO_ 2583654910 PropB1_71: 1785 Vector__XXX

BO_ 2583655166 PropB1_72: 1785 Vector__XXX

BO_ 2583655422 PropB1_73: 1785 Vector__XXX

BO_ 2583655678 PropB1_74: 1785 Vector__XXX

BO_ 2583655934 PropB1_75: 1785 Vector__XXX

BO_ 2583656190 PropB1_76: 1785 Vector__XXX

BO_ 2583656446 PropB1_77: 1785 Vector__XXX

BO_ 2583656702 PropB1_78: 1785 Vector__XXX

BO_ 2583656958 PropB1_79: 1785 Vector__XXX

BO_ 2583657214 PropB1_7A: 1785 Vector__XXX

BO_ 2583657470 PropB1_7B: 1785 Vector__XXX

BO_ 2583657726 PropB1_7C: 1785 Vector__XXX

BO_ 2583657982 PropB1_7D: 1785 Vector__XXX

BO_ 2583658238 PropB1_7E: 1785 Vector__XXX

BO_ 2583658494 PropB1_7F: 1785 Vector__XXX

BO_ 2583658750 PropB1_80: 1785 Vector__XXX

BO_ 2583659006 PropB1_81: 1785 Vector__XXX

BO_ 2583659262 PropB1_82: 1785 Vector__XXX

BO_ 2583659518 PropB1_83: 1785 Vector__XXX

BO_ 2583659774 PropB1_84: 1785 Vector__XXX

BO_ 2583660030 PropB1_85: 1785 Vector__XXX

BO_ 2583660286 PropB1_86: 1785 Vector__XXX

BO_ 2583660542 PropB1_87: 1785 Vector__XXX

BO_ 2583660798 PropB1_88: 1785 Vector__XXX

BO_ 2583661054 PropB1_89: 1785 Vector__XXX

BO_ 2583661310 PropB1_8A: 1785 Vector__XXX

BO_ 2583661566 PropB1_8B: 1785 Vector__XXX

BO_ 2583661822 PropB1_8C: 1785 Vector__XXX

BO_ 2583662078 PropB1_8D: 1785 Vector__XXX

BO_ 2583662334 PropB1_8E: 1785 Vector__XXX

BO_ 2583662590 PropB1_8F: 1785 Vector__XXX

BO_ 2583662846 PropB1_90: 1785 Vector__XXX

BO_ 2583663102 PropB1_91: 1785 Vector__XXX

BO_ 2583663358 PropB1_92: 1785 Vector__XXX

BO_ 2583663614 PropB1_93: 1785 Vector__XXX

BO_ 2583663870 PropB1_94: 1785 Vector__XXX

BO_ 2583664126 PropB1_95: 1785 Vector__XXX

BO_ 2583664382 PropB1_96: 1785 Vector__XXX

BO_ 2583664638 PropB1_97: 1785 Vector__XXX

BO_ 2583664894 PropB1_98: 1785 Vector__XXX

BO_ 2583665150 PropB1_99: 1785 Vector__XXX

BO_ 2583665406 PropB1_9A: 1785 Vector__XXX

BO_ 2583665662 PropB1_9B: 1785 Vector__XXX

BO_ 2583665918 PropB1_9C: 1785 Vector__XXX

BO_ 2583666174 PropB1_9D: 1785 Vector__XXX

BO_ 2583666430 PropB1_9E: 1785 Vector__XXX

BO_ 2583666686 PropB1_9F: 1785 Vector__XXX

BO_ 2583666942 PropB1_A0: 1785 Vector__XXX

BO_ 2583667198 PropB1_A1: 1785 Vector__XXX

BO_ 2583667454 PropB1_A2: 1785 Vector__XXX

BO_ 2583667710 PropB1_A3: 1785 Vector__XXX

BO_ 2583667966 PropB1_A4: 1785 Vector__XXX

BO_ 2583668222 PropB1_A5: 1785 Vector__XXX

BO_ 2583668478 PropB1_A6: 1785 Vector__XXX

BO_ 2583668734 PropB1_A7: 1785 Vector__XXX

BO_ 2583668990 PropB1_A8: 1785 Vector__XXX

BO_ 2583669246 PropB1_A9: 1785 Vector__XXX

BO_ 2583669502 PropB1_AA: 1785 Vector__XXX

BO_ 2583669758 PropB1_AB: 1785 Vector__XXX

BO_ 2583670014 PropB1_AC: 1785 Vector__XXX

BO_ 2583670270 PropB1_AD: 1785 Vector__XXX

BO_ 2583670526 PropB1_AE: 1785 Vector__XXX

BO_ 2583670782 PropB1_AF: 1785 Vector__XXX

BO_ 2583671038 PropB1_B0: 1785 Vector__XXX

BO_ 2583671294 PropB1_B1: 1785 Vector__XXX

BO_ 2583671550 PropB1_B2: 1785 Vector__XXX

BO_ 2583671806 PropB1_B3: 1785 Vector__XXX

BO_ 2583672062 PropB1_B4: 1785 Vector__XXX

BO_ 2583672318 PropB1_B5: 1785 Vector__XXX

BO_ 2583672574 PropB1_B6: 1785 Vector__XXX

BO_ 2583672830 PropB1_B7: 1785 Vector__XXX

BO_ 2583673086 PropB1_B8: 1785 Vector__XXX

BO_ 2583673342 PropB1_B9: 1785 Vector__XXX

BO_ 2583673598 PropB1_BA: 1785 Vector__XXX

BO_ 2583673854 PropB1_BB: 1785 Vector__XXX

BO_ 2583674110 PropB1_BC: 1785 Vector__XXX

BO_ 2583674366 PropB1_BD: 1785 Vector__XXX

BO_ 2583674622 PropB1_BE: 1785 Vector__XXX

BO_ 2583674878 PropB1_BF: 1785 Vector__XXX

BO_ 2583675134 PropB1_C0: 1785 Vector__XXX

BO_ 2583675390 PropB1_C1: 1785 Vector__XXX

BO_ 2583675646 PropB1_C2: 1785 Vector__XXX

BO_ 2583675902 PropB1_C3: 1785 Vector__XXX

BO_ 2583676158 PropB1_C4: 1785 Vector__XXX

BO_ 2583676414 PropB1_C5: 1785 Vector__XXX

BO_ 2583676670 PropB1_C6: 1785 Vector__XXX

BO_ 2583676926 PropB1_C7: 1785 Vector__XXX

BO_ 2583677182 PropB1_C8: 1785 Vector__XXX

BO_ 2583677438 PropB1_C9: 1785 Vector__XXX

BO_ 2583677694 PropB1_CA: 1785 Vector__XXX

BO_ 2583677950 PropB1_CB: 1785 Vector__XXX

BO_ 2583678206 PropB1_CC: 1785 Vector__XXX

BO_ 2583678462 PropB1_CD: 1785 Vector__XXX

BO_ 2583678718 PropB1_CE: 1785 Vector__XXX

BO_ 2583678974 PropB1_CF: 1785 Vector__XXX

BO_ 2583679230 PropB1_D0: 1785 Vector__XXX

BO_ 2583679486 PropB1_D1: 1785 Vector__XXX

BO_ 2583679742 PropB1_D2: 1785 Vector__XXX

BO_ 2583679998 PropB1_D3: 1785 Vector__XXX

BO_ 2583680254 PropB1_D4: 1785 Vector__XXX

BO_ 2583680510 PropB1_D5: 1785 Vector__XXX

BO_ 2583680766 PropB1_D6: 1785 Vector__XXX

BO_ 2583681022 PropB1_D7: 1785 Vector__XXX

BO_ 2583681278 PropB1_D8: 1785 Vector__XXX

BO_ 2583681534 PropB1_D9: 1785 Vector__XXX

BO_ 2583681790 PropB1_DA: 1785 Vector__XXX

BO_ 2583682046 PropB1_DB: 1785 Vector__XXX

BO_ 2583682302 PropB1_DC: 1785 Vector__XXX

BO_ 2583682558 PropB1_DD: 1785 Vector__XXX

BO_ 2583682814 PropB1_DE: 1785 Vector__XXX

BO_ 2583683070 PropB1_DF: 1785 Vector__XXX

BO_ 2583683326 PropB1_E0: 1785 Vector__XXX

BO_ 2583683582 PropB1_E1: 1785 Vector__XXX

BO_ 2583683838 PropB1_E2: 1785 Vector__XXX

BO_ 2583684094 PropB1_E3: 1785 Vector__XXX

BO_ 2583684350 PropB1_E4: 1785 Vector__XXX

BO_ 2583684606 PropB1_E5: 1785 Vector__XXX

BO_ 2583684862 PropB1_E6: 1785 Vector__XXX

BO_ 2583685118 PropB1_E7: 1785 Vector__XXX

BO_ 2583685374 PropB1_E8: 1785 Vector__XXX

BO_ 2583685630 PropB1_E9: 1785 Vector__XXX

BO_ 2583685886 PropB1_EA: 1785 Vector__XXX

BO_ 2583686142 PropB1_EB: 1785 Vector__XXX

BO_ 2583686398 PropB1_EC: 1785 Vector__XXX

BO_ 2583686654 PropB1_ED: 1785 Vector__XXX

BO_ 2583686910 PropB1_EE: 1785 Vector__XXX

BO_ 2583687166 PropB1_EF: 1785 Vector__XXX

BO_ 2583687422 PropB1_F0: 1785 Vector__XXX

BO_ 2583687678 PropB1_F1: 1785 Vector__XXX

BO_ 2583687934 PropB1_F2: 1785 Vector__XXX

BO_ 2583688190 PropB1_F3: 1785 Vector__XXX

BO_ 2583688446 PropB1_F4: 1785 Vector__XXX

BO_ 2583688702 PropB1_F5: 1785 Vector__XXX

BO_ 2583688958 PropB1_F6: 1785 Vector__XXX

BO_ 2583689214 PropB1_F7: 1785 Vector__XXX

BO_ 2583689470 PropB1_F8: 1785 Vector__XXX

BO_ 2583689726 PropB1_F9: 1785 Vector__XXX

BO_ 2583689982 PropB1_FA: 1785 Vector__XXX

BO_ 2583690238 PropB1_FB: 1785 Vector__XXX

BO_ 2583690494 PropB1_FC: 1785 Vector__XXX

BO_ 2583690750 PropB1_FD: 1785 Vector__XXX

BO_ 2583691006 PropB1_FE: 1785 Vector__XXX

BO_ 2583691262 PropB1_FF: 1785 Vector__XXX

CM_ BO_ 2566805246 "Aftertreatment 1 Diesel Exhaust Fluid Tank 1 Information 1";
CM_ BO_ 2365478910 "Air Suspension Control 5";
CM_ BO_ 2566805758 "Air Suspension Control 4";
CM_ BO_ 2566806014 "Air Suspension Control 3";
CM_ BO_ 2365479678 "Air Suspension Control 1";
CM_ BO_ 2566806526 "Forward Lane Image 2";
CM_ BO_ 2566809342 "Battery Main Switch Information";
CM_ BO_ 2566809598 "Climate Control Configuration";
CM_ BO_ 2566809854 "Vehicle Fluids";
CM_ BO_ 2566810110 "Engine Temperature 3";
CM_ BO_ 2566810366 "Engine Fuel/lube systems";
CM_ BO_ 2566810622 "Driver's Identification";
CM_ BO_ 2365484286 "Tachograph";
CM_ BO_ 2566811134 "Heater Information";
CM_ BO_ 2298375934 "High Resolution Wheel Speed";
CM_ BO_ 2432593918 "Adaptive Cruise Control 1";
CM_ BO_ 2566811902 "Combination Vehicle Weight";
CM_ BO_ 2365485566 "Laser Tracer Position";
CM_ BO_ 2365485822 "Laser Leveling System Blade Control";
CM_ BO_ 2365486078 "Laser Receiver Mast Position";
CM_ BO_ 2365486334 "Modify Leveling System Control Set Point";
CM_ BO_ 2365486590 "Laser Leveling System Vertical Deviation";
CM_ BO_ 2432595710 "Laser Leveling System Vertical Position Display Data";
CM_ BO_ 2633922558 "Auxiliary Pressures";
CM_ BO_ 2633922814 "Tire Pressure Control Unit Mode and Status";
CM_ BO_ 2633923070 "Tire Pressure Control Unit Target Pressures";
CM_ BO_ 2633923326 "Tire Pressure Control Unit Current Pressures";
CM_ BO_ 2633923582 "Combustion Time 1";
CM_ BO_ 2633923838 "Combustion Time 2";
CM_ BO_ 2633924094 "Combustion Time 3";
CM_ BO_ 2633924350 "Combustion Time 4";
CM_ BO_ 2633924606 "Combustion Time 5";
CM_ BO_ 2633924862 "Combustion Time 6";
CM_ BO_ 2633925118 "Fuel Information 2 (Gaseous)";
CM_ BO_ 2633925374 "Ignition Timing 1";
CM_ BO_ 2633925630 "Ignition Timing 2";
CM_ BO_ 2633925886 "Ignition Timing 3";
CM_ BO_ 2633926142 "Ignition Timing 4";
CM_ BO_ 2633926398 "Ignition Timing 5";
CM_ BO_ 2633926654 "Ignition Timing 6";
CM_ BO_ 2633926910 "Ignition Transformer Secondary Output 1";
CM_ BO_ 2633927166 "Ignition Transformer Secondary Output 2";
CM_ BO_ 2633927422 "Ignition Transformer Secondary Output 3";
CM_ BO_ 2633927678 "Gaseous Fuel Pressure 1";
CM_ BO_ 2633927934 "Auxiliary Analog Information";
CM_ BO_ 2566819326 "Vehicle Electrical Power 2";
CM_ BO_ 2633928446 "Service 2";
CM_ BO_ 2566819838 "Supply Pressure 2";
CM_ BO_ 2566820094 "Engine Torque History";
CM_ BO_ 2633929214 "Fuel Leakage";
CM_ BO_ 2633929470 "Engine Information 1";
CM_ BO_ 2633929726 "Engine Electrical System/Module Information";
CM_ BO_ 2566821118 "Engine Auxiliary Coolant";
CM_ BO_ 2633930238 "Rebuild Information";
CM_ BO_ 2566821630 "Turbocharger Wastegate";
CM_ BO_ 2566821886 "Turbocharger Information 5";
CM_ BO_ 2566822142 "Turbocharger Information 4";
CM_ BO_ 2566822398 "Turbocharger Information 3";
CM_ BO_ 2566822654 "Turbocharger Information 2";
CM_ BO_ 2633931774 "Turbocharger Information 1";
CM_ BO_ 2566823166 "Main Bearing Temperature 3";
CM_ BO_ 2566823422 "Main Bearing Temperature 2";
CM_ BO_ 2566823678 "Main Bearing Temperature 1";
CM_ BO_ 2633932798 "Exhaust Port Temperature 5";
CM_ BO_ 2566824190 "Exhaust Port Temperature 4";
CM_ BO_ 2633933310 "Exhaust Port Temperature 3";
CM_ BO_ 2633933566 "Exhaust Port Temperature 2";
CM_ BO_ 2633933822 "Exhaust Port Temperature 1";
CM_ BO_ 2566825214 "Engine Temperature 2";
CM_ BO_ 2633934334 "Intake Manifold Information 2";
CM_ BO_ 2566825726 "Intake Manifold Information 1";
CM_ BO_ 2633934846 "Alternator Temperature 1";
CM_ BO_ 2633935102 "Articulation Control";
CM_ BO_ 2633935358 "Exhaust Oxygen 1";
CM_ BO_ 2633935614 "Alternate Fuel 2";
CM_ BO_ 2633935870 "Electronic Transmission Controller 6";
CM_ BO_ 2633936126 "Wheel Brake Lining Remaining Information";
CM_ BO_ 2566827518 "Wheel Application Pressure High Range Information";
CM_ BO_ 2566827774 "Air Supply Pressure";
CM_ BO_ 2633936894 "Fuel Consumption (Gaseous)";
CM_ BO_ 2633937150 "Trip Time Information 2";
CM_ BO_ 2633937406 "ECU History";
CM_ BO_ 2633937662 "Fuel Information 1 (Gaseous)";
CM_ BO_ 2633937918 "Fuel Information 1 (Liquid)";
CM_ BO_ 2633938174 "Trip Time Information 1";
CM_ BO_ 2633938430 "Trip Shutdown Information";
CM_ BO_ 2633938686 "Trip Vehicle Speed/Cruise Distance Information";
CM_ BO_ 2633938942 "Engine Speed/Load Factor Information";
CM_ BO_ 2633939198 "Trip Fuel Information (Gaseous)";
CM_ BO_ 2633939454 "Trip Fuel Information (Liquid)";
CM_ BO_ 2633939710 "Trip Distance Information";
CM_ BO_ 2633939966 "Trip Fan Information";
CM_ BO_ 2633940222 "Compression/Service Brake Information";
CM_ BO_ 2566831614 "Fan Drive #1";
CM_ BO_ 2633940734 "Electronic Engine Controller 4";
CM_ BO_ 2566832126 "Wheel Speed Information";
CM_ BO_ 2566832382 "Service Information";
CM_ BO_ 2566832638 "High Resolution Vehicle Distance";
CM_ BO_ 2633941758 "Electronic Retarder Controller 2";
CM_ BO_ 2633942014 "Electronic Transmission Controller 5";
CM_ BO_ 2633942526 "Electronic Transmission Controller 4";
CM_ BO_ 2633943038 "Electronic Transmission Controller 3";
CM_ BO_ 2566834942 "Active Diagnostic Trouble Codes";
CM_ BO_ 2566835198 "Previously Active Diagnostic Trouble Codes";
CM_ BO_ 2566835454 "Diagnostic Data Clear/Reset for Previously Active DTCs";
CM_ BO_ 2566835710 "Freeze Frame Parameters";
CM_ BO_ 2566835966 "Diagnostic Readiness 1";
CM_ BO_ 2566836222 "Emission-Related Pending Diagnostic Trouble Codes";
CM_ BO_ 2566836478 "Test Results for Non-continuously Monitored Systems";
CM_ BO_ 2566836734 "Oxygen Sensor Test Results";
CM_ BO_ 2566836990 "Non-Continuously Monitored Systems Test Identifiers Support";
CM_ BO_ 2566837246 "Diagnostic Data Clear/Reset for Active DTCs";
CM_ BO_ 2566837502 "Emission-Related MIL-On Diagnostic Trouble Codes";
CM_ BO_ 2566837758 "Alternator Information";
CM_ BO_ 2566838014 "Hybrid System Inputs 1";
CM_ BO_ 2566838526 "Commanded Address";
CM_ BO_ 2566838782 "Auxiliary Input/Output Status 1";
CM_ BO_ 2566839038 "Software Identification";
CM_ BO_ 2566839294 "Engine Fluid Level/Pressure 2";
CM_ BO_ 2566839550 "Idle Operation";
CM_ BO_ 2566839806 "Turbocharger";
CM_ BO_ 2566840062 "Engine Air Start Pressure";
CM_ BO_ 2566840318 "Electronic Engine Controller 3";
CM_ BO_ 2566840574 "Vehicle Distance";
CM_ BO_ 2566840830 "Retarder Configuration";
CM_ BO_ 2566841086 "Transmission Configuration";
CM_ BO_ 2566841342 "Engine Configuration 1";
CM_ BO_ 2566841598 "Shutdown";
CM_ BO_ 2566841854 "Engine Hours, Revolutions";
CM_ BO_ 2566842110 "Time/Date";
CM_ BO_ 2566842366 "Vehicle Hours";
CM_ BO_ 2566842622 "Vehicle Direction/Speed";
CM_ BO_ 2566842878 "Fuel Consumption (Liquid) 1";
CM_ BO_ 2566843134 "Vehicle Weight";
CM_ BO_ 2566843390 "Component Identification";
CM_ BO_ 2566843646 "Vehicle Identification";
CM_ BO_ 2566843902 "Cruise Control/Vehicle Speed Setup";
CM_ BO_ 2566844158 "Engine Temperature 1";
CM_ BO_ 2566844414 "Engine Fluid Level/Pressure 1";
CM_ BO_ 2566844670 "Power Takeoff Information";
CM_ BO_ 2566844926 "Cruise Control/Vehicle Speed 1";
CM_ BO_ 2566845182 "Fuel Economy (Liquid)";
CM_ BO_ 2566845438 "Vehicle Position 1";
CM_ BO_ 2566845694 "Tire Condition Message 1";
CM_ BO_ 2566845950 "Ambient Conditions";
CM_ BO_ 2566846206 "Intake/Exhaust Conditions 1";
CM_ BO_ 2566846462 "Vehicle Electrical Power 1";
CM_ BO_ 2566846718 "Transmission Fluids 1";
CM_ BO_ 2566846974 "Axle Information";
CM_ BO_ 2566847230 "Brakes 1";
CM_ BO_ 2566847486 "Retarder fluids";
CM_ BO_ 2566847742 "Dash Display 1";
CM_ BO_ 2566847998 "Alternate Fuel 1";
CM_ BO_ 2566848254 "Auxiliary Water Pump Pressure";
CM_ BO_ 2566848510 "Operator indicators";
CM_ BO_ 2566848766 "Proprietary B (00h)";
CM_ BO_ 2566849022 "Proprietary B (01h)";
CM_ BO_ 2566849278 "Proprietary B (02h)";
CM_ BO_ 2566849534 "Proprietary B (03h)";
CM_ BO_ 2566849790 "Proprietary B (04h)";
CM_ BO_ 2566850046 "Proprietary B (05h)";
CM_ BO_ 2566850302 "Proprietary B (06h)";
CM_ BO_ 2566850558 "Proprietary B (07h)";
CM_ BO_ 2566850814 "Proprietary B (08h)";
CM_ BO_ 2566851070 "Proprietary B (09h)";
CM_ BO_ 2566851326 "Proprietary B (0Ah)";
CM_ BO_ 2566851582 "Proprietary B (0Bh)";
CM_ BO_ 2566851838 "Proprietary B (0Ch)";
CM_ BO_ 2566852094 "Proprietary B (0Dh)";
CM_ BO_ 2566852350 "Proprietary B (0Eh)";
CM_ BO_ 2566852606 "Proprietary B (0Fh)";
CM_ BO_ 2566852862 "Proprietary B (10h)";
CM_ BO_ 2566853118 "Proprietary B (11h)";
CM_ BO_ 2566853374 "Proprietary B (12h)";
CM_ BO_ 2566853630 "Proprietary B (13h)";
CM_ BO_ 2566853886 "Proprietary B (14h)";
CM_ BO_ 2566854142 "Proprietary B (15h)";
CM_ BO_ 2566854398 "Proprietary B (16h)";
CM_ BO_ 2566854654 "Proprietary B (17h)";
CM_ BO_ 2566854910 "Proprietary B (18h)";
CM_ BO_ 2566855166 "Proprietary B (19h)";
CM_ BO_ 2566855422 "Proprietary B (1Ah)";
CM_ BO_ 2566855678 "Proprietary B (1Bh)";
CM_ BO_ 2566855934 "Proprietary B (1Ch)";
CM_ BO_ 2566856190 "Proprietary B (1Dh)";
CM_ BO_ 2566856446 "Proprietary B (1Eh)";
CM_ BO_ 2566856702 "Proprietary B (1Fh)";
CM_ BO_ 2566856958 "Proprietary B (20h)";
CM_ BO_ 2566857214 "Proprietary B (21h)";
CM_ BO_ 2566857470 "Proprietary B (22h)";
CM_ BO_ 2566857726 "Proprietary B (23h)";
CM_ BO_ 2566857982 "Proprietary B (24h)";
CM_ BO_ 2566858238 "Proprietary B (25h)";
CM_ BO_ 2566858494 "Proprietary B (26h)";
CM_ BO_ 2566858750 "Proprietary B (27h)";
CM_ BO_ 2566859006 "Proprietary B (28h)";
CM_ BO_ 2566859262 "Proprietary B (29h)";
CM_ BO_ 2566859518 "Proprietary B (2Ah)";
CM_ BO_ 2566859774 "Proprietary B (2Bh)";
CM_ BO_ 2566860030 "Proprietary B (2Ch)";
CM_ BO_ 2566860286 "Proprietary B (2Dh)";
CM_ BO_ 2566860542 "Proprietary B (2Eh)";
CM_ BO_ 2566860798 "Proprietary B (2Fh)";
CM_ BO_ 2566861054 "Proprietary B (30h)";
CM_ BO_ 2566861310 "Proprietary B (31h)";
CM_ BO_ 2566861566 "Proprietary B (32h)";
CM_ BO_ 2566861822 "Proprietary B (33h)";
CM_ BO_ 2566862078 "Proprietary B (34h)";
CM_ BO_ 2566862334 "Proprietary B (35h)";
CM_ BO_ 2566862590 "Proprietary B (36h)";
CM_ BO_ 2566862846 "Proprietary B (37h)";
CM_ BO_ 2566863102 "Proprietary B (38h)";
CM_ BO_ 2566863358 "Proprietary B (39h)";
CM_ BO_ 2566863614 "Proprietary B (3Ah)";
CM_ BO_ 2566863870 "Proprietary B (3Bh)";
CM_ BO_ 2566864126 "Proprietary B (3Ch)";
CM_ BO_ 2566864382 "Proprietary B (3Dh)";
CM_ BO_ 2566864638 "Proprietary B (3Eh)";
CM_ BO_ 2566864894 "Proprietary B (3Fh)";
CM_ BO_ 2566865150 "Proprietary B (40h)";
CM_ BO_ 2566865406 "Proprietary B (41h)";
CM_ BO_ 2566865662 "Proprietary B (42h)";
CM_ BO_ 2566865918 "Proprietary B (43h)";
CM_ BO_ 2566866174 "Proprietary B (44h)";
CM_ BO_ 2566866430 "Proprietary B (45h)";
CM_ BO_ 2566866686 "Proprietary B (46h)";
CM_ BO_ 2566866942 "Proprietary B (47h)";
CM_ BO_ 2566867198 "Proprietary B (48h)";
CM_ BO_ 2566867454 "Proprietary B (49h)";
CM_ BO_ 2566867710 "Proprietary B (4Ah)";
CM_ BO_ 2566867966 "Proprietary B (4Bh)";
CM_ BO_ 2566868222 "Proprietary B (4Ch)";
CM_ BO_ 2566868478 "Proprietary B (4Dh)";
CM_ BO_ 2566868734 "Proprietary B (4Eh)";
CM_ BO_ 2566868990 "Proprietary B (4Fh)";
CM_ BO_ 2566869246 "Proprietary B (50h)";
CM_ BO_ 2566869502 "Proprietary B (51h)";
CM_ BO_ 2566869758 "Proprietary B (52h)";
CM_ BO_ 2566870014 "Proprietary B (53h)";
CM_ BO_ 2566870270 "Proprietary B (54h)";
CM_ BO_ 2566870526 "Proprietary B (55h)";
CM_ BO_ 2566870782 "Proprietary B (56h)";
CM_ BO_ 2566871038 "Proprietary B (57h)";
CM_ BO_ 2566871294 "Proprietary B (58h)";
CM_ BO_ 2566871550 "Proprietary B (59h)";
CM_ BO_ 2566871806 "Proprietary B (5Ah)";
CM_ BO_ 2566872062 "Proprietary B (5Bh)";
CM_ BO_ 2566872318 "Proprietary B (5Ch)";
CM_ BO_ 2566872574 "Proprietary B (5Dh)";
CM_ BO_ 2566872830 "Proprietary B (5Eh)";
CM_ BO_ 2566873086 "Proprietary B (5Fh)";
CM_ BO_ 2566873342 "Proprietary B (60h)";
CM_ BO_ 2566873598 "Proprietary B (61h)";
CM_ BO_ 2566873854 "Proprietary B (62h)";
CM_ BO_ 2566874110 "Proprietary B (63h)";
CM_ BO_ 2566874366 "Proprietary B (64h)";
CM_ BO_ 2566874622 "Proprietary B (65h)";
CM_ BO_ 2566874878 "Proprietary B (66h)";
CM_ BO_ 2566875134 "Proprietary B (67h)";
CM_ BO_ 2566875390 "Proprietary B (68h)";
CM_ BO_ 2566875646 "Proprietary B (69h)";
CM_ BO_ 2566875902 "Proprietary B (6Ah)";
CM_ BO_ 2566876158 "Proprietary B (6Bh)";
CM_ BO_ 2566876414 "Proprietary B (6Ch)";
CM_ BO_ 2566876670 "Proprietary B (6Dh)";
CM_ BO_ 2566876926 "Proprietary B (6Eh)";
CM_ BO_ 2566877182 "Proprietary B (6Fh)";
CM_ BO_ 2566877438 "Proprietary B (70h)";
CM_ BO_ 2566877694 "Proprietary B (71h)";
CM_ BO_ 2566877950 "Proprietary B (72h)";
CM_ BO_ 2566878206 "Proprietary B (73h)";
CM_ BO_ 2566878462 "Proprietary B (74h)";
CM_ BO_ 2566878718 "Proprietary B (75h)";
CM_ BO_ 2566878974 "Proprietary B (76h)";
CM_ BO_ 2566879230 "Proprietary B (77h)";
CM_ BO_ 2566879486 "Proprietary B (78h)";
CM_ BO_ 2566879742 "Proprietary B (79h)";
CM_ BO_ 2566879998 "Proprietary B (7Ah)";
CM_ BO_ 2566880254 "Proprietary B (7Bh)";
CM_ BO_ 2566880510 "Proprietary B (7Ch)";
CM_ BO_ 2566880766 "Proprietary B (7Dh)";
CM_ BO_ 2566881022 "Proprietary B (7Eh)";
CM_ BO_ 2566881278 "Proprietary B (7Fh)";
CM_ BO_ 2566881534 "Proprietary B (80h)";
CM_ BO_ 2566881790 "Proprietary B (81h)";
CM_ BO_ 2566882046 "Proprietary B (82h)";
CM_ BO_ 2566882302 "Proprietary B (83h)";
CM_ BO_ 2566882558 "Proprietary B (84h)";
CM_ BO_ 2566882814 "Proprietary B (85h)";
CM_ BO_ 2566883070 "Proprietary B (86h)";
CM_ BO_ 2566883326 "Proprietary B (87h)";
CM_ BO_ 2566883582 "Proprietary B (88h)";
CM_ BO_ 2566883838 "Proprietary B (89h)";
CM_ BO_ 2566884094 "Proprietary B (8Ah)";
CM_ BO_ 2566884350 "Proprietary B (8Bh)";
CM_ BO_ 2566884606 "Proprietary B (8Ch)";
CM_ BO_ 2566884862 "Proprietary B (8Dh)";
CM_ BO_ 2566885118 "Proprietary B (8Eh)";
CM_ BO_ 2566885374 "Proprietary B (8Fh)";
CM_ BO_ 2566885630 "Proprietary B (90h)";
CM_ BO_ 2566885886 "Proprietary B (91h)";
CM_ BO_ 2566886142 "Proprietary B (92h)";
CM_ BO_ 2566886398 "Proprietary B (93h)";
CM_ BO_ 2566886654 "Proprietary B (94h)";
CM_ BO_ 2566886910 "Proprietary B (95h)";
CM_ BO_ 2566887166 "Proprietary B (96h)";
CM_ BO_ 2566887422 "Proprietary B (97h)";
CM_ BO_ 2566887678 "Proprietary B (98h)";
CM_ BO_ 2566887934 "Proprietary B (99h)";
CM_ BO_ 2566888190 "Proprietary B (9Ah)";
CM_ BO_ 2566888446 "Proprietary B (9Bh)";
CM_ BO_ 2566888702 "Proprietary B (9Ch)";
CM_ BO_ 2566888958 "Proprietary B (9Dh)";
CM_ BO_ 2566889214 "Proprietary B (9Eh)";
CM_ BO_ 2566889470 "Proprietary B (9Fh)";
CM_ BO_ 2566889726 "Proprietary B (A0h)";
CM_ BO_ 2566889982 "Proprietary B (A1h)";
CM_ BO_ 2566890238 "Proprietary B (A2h)";
CM_ BO_ 2566890494 "Proprietary B (A3h)";
CM_ BO_ 2566890750 "Proprietary B (A4h)";
CM_ BO_ 2566891006 "Proprietary B (A5h)";
CM_ BO_ 2566891262 "Proprietary B (A6h)";
CM_ BO_ 2566891518 "Proprietary B (A7h)";
CM_ BO_ 2566891774 "Proprietary B (A8h)";
CM_ BO_ 2566892030 "Proprietary B (A9h)";
CM_ BO_ 2566892286 "Proprietary B (AAh)";
CM_ BO_ 2566892542 "Proprietary B (ABh)";
CM_ BO_ 2566892798 "Proprietary B (ACh)";
CM_ BO_ 2566893054 "Proprietary B (ADh)";
CM_ BO_ 2566893310 "Proprietary B (AEh)";
CM_ BO_ 2566893566 "Proprietary B (AFh)";
CM_ BO_ 2566893822 "Proprietary B (B0h)";
CM_ BO_ 2566894078 "Proprietary B (B1h)";
CM_ BO_ 2566894334 "Proprietary B (B2h)";
CM_ BO_ 2566894590 "Proprietary B (B3h)";
CM_ BO_ 2566894846 "Proprietary B (B4h)";
CM_ BO_ 2566895102 "Proprietary B (B5h)";
CM_ BO_ 2566895358 "Proprietary B (B6h)";
CM_ BO_ 2566895614 "Proprietary B (B7h)";
CM_ BO_ 2566895870 "Proprietary B (B8h)";
CM_ BO_ 2566896126 "Proprietary B (B9h)";
CM_ BO_ 2566896382 "Proprietary B (BAh)";
CM_ BO_ 2566896638 "Proprietary B (BBh)";
CM_ BO_ 2566896894 "Proprietary B (BCh)";
CM_ BO_ 2566897150 "Proprietary B (BDh)";
CM_ BO_ 2566897406 "Proprietary B (BEh)";
CM_ BO_ 2566897662 "Proprietary B (BFh)";
CM_ BO_ 2566897918 "Proprietary B (C0h)";
CM_ BO_ 2566898174 "Proprietary B (C1h)";
CM_ BO_ 2566898430 "Proprietary B (C2h)";
CM_ BO_ 2566898686 "Proprietary B (C3h)";
CM_ BO_ 2566898942 "Proprietary B (C4h)";
CM_ BO_ 2566899198 "Proprietary B (C5h)";
CM_ BO_ 2566899454 "Proprietary B (C6h)";
CM_ BO_ 2566899710 "Proprietary B (C7h)";
CM_ BO_ 2566899966 "Proprietary B (C8h)";
CM_ BO_ 2566900222 "Proprietary B (C9h)";
CM_ BO_ 2566900478 "Proprietary B (CAh)";
CM_ BO_ 2566900734 "Proprietary B (CBh)";
CM_ BO_ 2566900990 "Proprietary B (CCh)";
CM_ BO_ 2566901246 "Proprietary B (CDh)";
CM_ BO_ 2566901502 "Proprietary B (CEh)";
CM_ BO_ 2566901758 "Proprietary B (CFh)";
CM_ BO_ 2566902014 "Proprietary B (D0h)";
CM_ BO_ 2566902270 "Proprietary B (D1h)";
CM_ BO_ 2566902526 "Proprietary B (D2h)";
CM_ BO_ 2566902782 "Proprietary B (D3h)";
CM_ BO_ 2566903038 "Proprietary B (D4h)";
CM_ BO_ 2566903294 "Proprietary B (D5h)";
CM_ BO_ 2566903550 "Proprietary B (D6h)";
CM_ BO_ 2566903806 "Proprietary B (D7h)";
CM_ BO_ 2566904062 "Proprietary B (D8h)";
CM_ BO_ 2566904318 "Proprietary B (D9h)";
CM_ BO_ 2566904574 "Proprietary B (DAh)";
CM_ BO_ 2566904830 "Proprietary B (DBh)";
CM_ BO_ 2566905086 "Proprietary B (DCh)";
CM_ BO_ 2566905342 "Proprietary B (DDh)";
CM_ BO_ 2566905598 "Proprietary B (DEh)";
CM_ BO_ 2566905854 "Proprietary B (DFh)";
CM_ BO_ 2566906110 "Proprietary B (E0h)";
CM_ BO_ 2566906366 "Proprietary B (E1h)";
CM_ BO_ 2566906622 "Proprietary B (E2h)";
CM_ BO_ 2566906878 "Proprietary B (E3h)";
CM_ BO_ 2566907134 "Proprietary B (E4h)";
CM_ BO_ 2566907390 "Proprietary B (E5h)";
CM_ BO_ 2566907646 "Proprietary B (E6h)";
CM_ BO_ 2566907902 "Proprietary B (E7h)";
CM_ BO_ 2566908158 "Proprietary B (E8h)";
CM_ BO_ 2566908414 "Proprietary B (E9h)";
CM_ BO_ 2566908670 "Proprietary B (EAh)";
CM_ BO_ 2566908926 "Proprietary B (EBh)";
CM_ BO_ 2566909182 "Proprietary B (ECh)";
CM_ BO_ 2566909438 "Proprietary B (EDh)";
CM_ BO_ 2566909694 "Proprietary B (EEh)";
CM_ BO_ 2566909950 "Proprietary B (EFh)";
CM_ BO_ 2566910206 "Proprietary B (F0h)";
CM_ BO_ 2566910462 "Proprietary B (F1h)";
CM_ BO_ 2566910718 "Proprietary B (F2h)";
CM_ BO_ 2566910974 "Proprietary B (F3h)";
CM_ BO_ 2566911230 "Proprietary B (F4h)";
CM_ BO_ 2566911486 "Proprietary B (F5h)";
CM_ BO_ 2566911742 "Proprietary B (F6h)";
CM_ BO_ 2566911998 "Proprietary B (F7h)";
CM_ BO_ 2566912254 "Proprietary B (F8h)";
CM_ BO_ 2566912510 "Proprietary B (F9h)";
CM_ BO_ 2566912766 "Proprietary B (FAh)";
CM_ BO_ 2566913022 "Proprietary B (FBh)";
CM_ BO_ 2566913278 "Proprietary B (FCh)";
CM_ BO_ 2566913534 "Proprietary B (FDh)";
CM_ BO_ 2566913790 "Proprietary B (FEh)";
CM_ BO_ 2566914046 "Proprietary B (FFh)";
CM_ BO_ 2582642430 "Proprietary A2";
CM_ BO_ 2583625982 "Proprietary B - Page 1 (00h)";
CM_ BO_ 2583626238 "Proprietary B - Page 1 (01h)";
CM_ BO_ 2583626494 "Proprietary B - Page 1 (02h)";
CM_ BO_ 2583626750 "Proprietary B - Page 1 (03h)";
CM_ BO_ 2583627006 "Proprietary B - Page 1 (04h)";
CM_ BO_ 2583627262 "Proprietary B - Page 1 (05h)";
CM_ BO_ 2583627518 "Proprietary B - Page 1 (06h)";
CM_ BO_ 2583627774 "Proprietary B - Page 1 (07h)";
CM_ BO_ 2583628030 "Proprietary B - Page 1 (08h)";
CM_ BO_ 2583628286 "Proprietary B - Page 1 (09h)";
CM_ BO_ 2583628542 "Proprietary B - Page 1 (0Ah)";
CM_ BO_ 2583628798 "Proprietary B - Page 1 (0Bh)";
CM_ BO_ 2583629054 "Proprietary B - Page 1 (0Ch)";
CM_ BO_ 2583629310 "Proprietary B - Page 1 (0Dh)";
CM_ BO_ 2583629566 "Proprietary B - Page 1 (0Eh)";
CM_ BO_ 2583629822 "Proprietary B - Page 1 (0Fh)";
CM_ BO_ 2583630078 "Proprietary B - Page 1 (10h)";
CM_ BO_ 2583630334 "Proprietary B - Page 1 (11h)";
CM_ BO_ 2583630590 "Proprietary B - Page 1 (12h)";
CM_ BO_ 2583630846 "Proprietary B - Page 1 (13h)";
CM_ BO_ 2583631102 "Proprietary B - Page 1 (14h)";
CM_ BO_ 2583631358 "Proprietary B - Page 1 (15h)";
CM_ BO_ 2583631614 "Proprietary B - Page 1 (16h)";
CM_ BO_ 2583631870 "Proprietary B - Page 1 (17h)";
CM_ BO_ 2583632126 "Proprietary B - Page 1 (18h)";
CM_ BO_ 2583632382 "Proprietary B - Page 1 (19h)";
CM_ BO_ 2583632638 "Proprietary B - Page 1 (1Ah)";
CM_ BO_ 2583632894 "Proprietary B - Page 1 (1Bh)";
CM_ BO_ 2583633150 "Proprietary B - Page 1 (1Ch)";
CM_ BO_ 2583633406 "Proprietary B - Page 1 (1Dh)";
CM_ BO_ 2583633662 "Proprietary B - Page 1 (1Eh)";
CM_ BO_ 2583633918 "Proprietary B - Page 1 (1Fh)";
CM_ BO_ 2583634174 "Proprietary B - Page 1 (20h)";
CM_ BO_ 2583634430 "Proprietary B - Page 1 (21h)";
CM_ BO_ 2583634686 "Proprietary B - Page 1 (22h)";
CM_ BO_ 2583634942 "Proprietary B - Page 1 (23h)";
CM_ BO_ 2583635198 "Proprietary B - Page 1 (24h)";
CM_ BO_ 2583635454 "Proprietary B - Page 1 (25h)";
CM_ BO_ 2583635710 "Proprietary B - Page 1 (26h)";
CM_ BO_ 2583635966 "Proprietary B - Page 1 (27h)";
CM_ BO_ 2583636222 "Proprietary B - Page 1 (28h)";
CM_ BO_ 2583636478 "Proprietary B - Page 1 (29h)";
CM_ BO_ 2583636734 "Proprietary B - Page 1 (2Ah)";
CM_ BO_ 2583636990 "Proprietary B - Page 1 (2Bh)";
CM_ BO_ 2583637246 "Proprietary B - Page 1 (2Ch)";
CM_ BO_ 2583637502 "Proprietary B - Page 1 (2Dh)";
CM_ BO_ 2583637758 "Proprietary B - Page 1 (2Eh)";
CM_ BO_ 2583638014 "Proprietary B - Page 1 (2Fh)";
CM_ BO_ 2583638270 "Proprietary B - Page 1 (30h)";
CM_ BO_ 2583638526 "Proprietary B - Page 1 (31h)";
CM_ BO_ 2583638782 "Proprietary B - Page 1 (32h)";
CM_ BO_ 2583639038 "Proprietary B - Page 1 (33h)";
CM_ BO_ 2583639294 "Proprietary B - Page 1 (34h)";
CM_ BO_ 2583639550 "Proprietary B - Page 1 (35h)";
CM_ BO_ 2583639806 "Proprietary B - Page 1 (36h)";
CM_ BO_ 2583640062 "Proprietary B - Page 1 (37h)";
CM_ BO_ 2583640318 "Proprietary B - Page 1 (38h)";
CM_ BO_ 2583640574 "Proprietary B - Page 1 (39h)";
CM_ BO_ 2583640830 "Proprietary B - Page 1 (3Ah)";
CM_ BO_ 2583641086 "Proprietary B - Page 1 (3Bh)";
CM_ BO_ 2583641342 "Proprietary B - Page 1 (3Ch)";
CM_ BO_ 2583641598 "Proprietary B - Page 1 (3Dh)";
CM_ BO_ 2583641854 "Proprietary B - Page 1 (3Eh)";
CM_ BO_ 2583642110 "Proprietary B - Page 1 (3Fh)";
CM_ BO_ 2583642366 "Proprietary B - Page 1 (40h)";
CM_ BO_ 2583642622 "Proprietary B - Page 1 (41h)";
CM_ BO_ 2583642878 "Proprietary B - Page 1 (42h)";
CM_ BO_ 2583643134 "Proprietary B - Page 1 (43h)";
CM_ BO_ 2583643390 "Proprietary B - Page 1 (44h)";
CM_ BO_ 2583643646 "Proprietary B - Page 1 (45h)";
CM_ BO_ 2583643902 "Proprietary B - Page 1 (46h)";
CM_ BO_ 2583644158 "Proprietary B - Page 1 (47h)";
CM_ BO_ 2583644414 "Proprietary B - Page 1 (48h)";
CM_ BO_ 2583644670 "Proprietary B - Page 1 (49h)";
CM_ BO_ 2583644926 "Proprietary B - Page 1 (4Ah)";
CM_ BO_ 2583645182 "Proprietary B - Page 1 (4Bh)";
CM_ BO_ 2583645438 "Proprietary B - Page 1 (4Ch)";
CM_ BO_ 2583645694 "Proprietary B - Page 1 (4Dh)";
CM_ BO_ 2583645950 "Proprietary B - Page 1 (4Eh)";
CM_ BO_ 2583646206 "Proprietary B - Page 1 (4Fh)";
CM_ BO_ 2583646462 "Proprietary B - Page 1 (50h)";
CM_ BO_ 2583646718 "Proprietary B - Page 1 (51h)";
CM_ BO_ 2583646974 "Proprietary B - Page 1 (52h)";
CM_ BO_ 2583647230 "Proprietary B - Page 1 (53h)";
CM_ BO_ 2583647486 "Proprietary B - Page 1 (54h)";
CM_ BO_ 2583647742 "Proprietary B - Page 1 (55h)";
CM_ BO_ 2583647998 "Proprietary B - Page 1 (56h)";
CM_ BO_ 2583648254 "Proprietary B - Page 1 (57h)";
CM_ BO_ 2583648510 "Proprietary B - Page 1 (58h)";
CM_ BO_ 2583648766 "Proprietary B - Page 1 (59h)";
CM_ BO_ 2583649022 "Proprietary B - Page 1 (5Ah)";
CM_ BO_ 2583649278 "Proprietary B - Page 1 (5Bh)";
CM_ BO_ 2583649534 "Proprietary B - Page 1 (5Ch)";
CM_ BO_ 2583649790 "Proprietary B - Page 1 (5Dh)";
CM_ BO_ 2583650046 "Proprietary B - Page 1 (5Eh)";
CM_ BO_ 2583650302 "Proprietary B - Page 1 (5Fh)";
CM_ BO_ 2583650558 "Proprietary B - Page 1 (60h)";
CM_ BO_ 2583650814 "Proprietary B - Page 1 (61h)";
CM_ BO_ 2583651070 "Proprietary B - Page 1 (62h)";
CM_ BO_ 2583651326 "Proprietary B - Page 1 (63h)";
CM_ BO_ 2583651582 "Proprietary B - Page 1 (64h)";
CM_ BO_ 2583651838 "Proprietary B - Page 1 (65h)";
CM_ BO_ 2583652094 "Proprietary B - Page 1 (66h)";
CM_ BO_ 2583652350 "Proprietary B - Page 1 (67h)";
CM_ BO_ 2583652606 "Proprietary B - Page 1 (68h)";
CM_ BO_ 2583652862 "Proprietary B - Page 1 (69h)";
CM_ BO_ 2583653118 "Proprietary B - Page 1 (6Ah)";
CM_ BO_ 2583653374 "Proprietary B - Page 1 (6Bh)";
CM_ BO_ 2583653630 "Proprietary B - Page 1 (6Ch)";
CM_ BO_ 2583653886 "Proprietary B - Page 1 (6Dh)";
CM_ BO_ 2583654142 "Proprietary B - Page 1 (6Eh)";
CM_ BO_ 2583654398 "Proprietary B - Page 1 (6Fh)";
CM_ BO_ 2583654654 "Proprietary B - Page 1 (70h)";
CM_ BO_ 2583654910 "Proprietary B - Page 1 (71h)";
CM_ BO_ 2583655166 "Proprietary B - Page 1 (72h)";
CM_ BO_ 2583655422 "Proprietary B - Page 1 (73h)";
CM_ BO_ 2583655678 "Proprietary B - Page 1 (74h)";
CM_ BO_ 2583655934 "Proprietary B - Page 1 (75h)";
CM_ BO_ 2583656190 "Proprietary B - Page 1 (76h)";
CM_ BO_ 2583656446 "Proprietary B - Page 1 (77h)";
CM_ BO_ 2583656702 "Proprietary B - Page 1 (78h)";
CM_ BO_ 2583656958 "Proprietary B - Page 1 (79h)";
CM_ BO_ 2583657214 "Proprietary B - Page 1 (7Ah)";
CM_ BO_ 2583657470 "Proprietary B - Page 1 (7Bh)";
CM_ BO_ 2583657726 "Proprietary B - Page 1 (7Ch)";
CM_ BO_ 2583657982 "Proprietary B - Page 1 (7Dh)";
CM_ BO_ 2583658238 "Proprietary B - Page 1 (7Eh)";
CM_ BO_ 2583658494 "Proprietary B - Page 1 (7Fh)";
CM_ BO_ 2583658750 "Proprietary B - Page 1 (80h)";
CM_ BO_ 2583659006 "Proprietary B - Page 1 (81h)";
CM_ BO_ 2583659262 "Proprietary B - Page 1 (82h)";
CM_ BO_ 2583659518 "Proprietary B - Page 1 (83h)";
CM_ BO_ 2583659774 "Proprietary B - Page 1 (84h)";
CM_ BO_ 2583660030 "Proprietary B - Page 1 (85h)";
CM_ BO_ 2583660286 "Proprietary B - Page 1 (86h)";
CM_ BO_ 2583660542 "Proprietary B - Page 1 (87h)";
CM_ BO_ 2583660798 "Proprietary B - Page 1 (88h)";
CM_ BO_ 2583661054 "Proprietary B - Page 1 (89h)";
CM_ BO_ 2583661310 "Proprietary B - Page 1 (8Ah)";
CM_ BO_ 2583661566 "Proprietary B - Page 1 (8Bh)";
CM_ BO_ 2583661822 "Proprietary B - Page 1 (8Ch)";
CM_ BO_ 2583662078 "Proprietary B - Page 1 (8Dh)";
CM_ BO_ 2583662334 "Proprietary B - Page 1 (8Eh)";
CM_ BO_ 2583662590 "Proprietary B - Page 1 (8Fh)";
CM_ BO_ 2583662846 "Proprietary B - Page 1 (90h)";
CM_ BO_ 2583663102 "Proprietary B - Page 1 (91h)";
CM_ BO_ 2583663358 "Proprietary B - Page 1 (92h)";
CM_ BO_ 2583663614 "Proprietary B - Page 1 (93h)";
CM_ BO_ 2583663870 "Proprietary B - Page 1 (94h)";
CM_ BO_ 2583664126 "Proprietary B - Page 1 (95h)";
CM_ BO_ 2583664382 "Proprietary B - Page 1 (96h)";
CM_ BO_ 2583664638 "Proprietary B - Page 1 (97h)";
CM_ BO_ 2583664894 "Proprietary B - Page 1 (98h)";
CM_ BO_ 2583665150 "Proprietary B - Page 1 (99h)";
CM_ BO_ 2583665406 "Proprietary B - Page 1 (9Ah)";
CM_ BO_ 2583665662 "Proprietary B - Page 1 (9Bh)";
CM_ BO_ 2583665918 "Proprietary B - Page 1 (9Ch)";
CM_ BO_ 2583666174 "Proprietary B - Page 1 (9Dh)";
CM_ BO_ 2583666430 "Proprietary B - Page 1 (9Eh)";
CM_ BO_ 2583666686 "Proprietary B - Page 1 (9Fh)";
CM_ BO_ 2583666942 "Proprietary B - Page 1 (A0h)";
CM_ BO_ 2583667198 "Proprietary B - Page 1 (A1h)";
CM_ BO_ 2583667454 "Proprietary B - Page 1 (A2h)";
CM_ BO_ 2583667710 "Proprietary B - Page 1 (A3h)";
CM_ BO_ 2583667966 "Proprietary B - Page 1 (A4h)";
CM_ BO_ 2583668222 "Proprietary B - Page 1 (A5h)";
CM_ BO_ 2583668478 "Proprietary B - Page 1 (A6h)";
CM_ BO_ 2583668734 "Proprietary B - Page 1 (A7h)";
CM_ BO_ 2583668990 "Proprietary B - Page 1 (A8h)";
CM_ BO_ 2583669246 "Proprietary B - Page 1 (A9h)";
CM_ BO_ 2583669502 "Proprietary B - Page 1 (AAh)";
CM_ BO_ 2583669758 "Proprietary B - Page 1 (ABh)";
CM_ BO_ 2583670014 "Proprietary B - Page 1 (ACh)";
CM_ BO_ 2583670270 "Proprietary B - Page 1 (ADh)";
CM_ BO_ 2583670526 "Proprietary B - Page 1 (AEh)";
CM_ BO_ 2583670782 "Proprietary B - Page 1 (AFh)";
CM_ BO_ 2583671038 "Proprietary B - Page 1 (B0h)";
CM_ BO_ 2583671294 "Proprietary B - Page 1 (B1h)";
CM_ BO_ 2583671550 "Proprietary B - Page 1 (B2h)";
CM_ BO_ 2583671806 "Proprietary B - Page 1 (B3h)";
CM_ BO_ 2583672062 "Proprietary B - Page 1 (B4h)";
CM_ BO_ 2583672318 "Proprietary B - Page 1 (B5h)";
CM_ BO_ 2583672574 "Proprietary B - Page 1 (B6h)";
CM_ BO_ 2583672830 "Proprietary B - Page 1 (B7h)";
CM_ BO_ 2583673086 "Proprietary B - Page 1 (B8h)";
CM_ BO_ 2583673342 "Proprietary B - Page 1 (B9h)";
CM_ BO_ 2583673598 "Proprietary B - Page 1 (BAh)";
CM_ BO_ 2583673854 "Proprietary B - Page 1 (BBh)";
CM_ BO_ 2583674110 "Proprietary B - Page 1 (BCh)";
CM_ BO_ 2583674366 "Proprietary B - Page 1 (BDh)";
CM_ BO_ 2583674622 "Proprietary B - Page 1 (BEh)";
CM_ BO_ 2583674878 "Proprietary B - Page 1 (BFh)";
CM_ BO_ 2583675134 "Proprietary B - Page 1 (C0h)";
CM_ BO_ 2583675390 "Proprietary B - Page 1 (C1h)";
CM_ BO_ 2583675646 "Proprietary B - Page 1 (C2h)";
CM_ BO_ 2583675902 "Proprietary B - Page 1 (C3h)";
CM_ BO_ 2583676158 "Proprietary B - Page 1 (C4h)";
CM_ BO_ 2583676414 "Proprietary B - Page 1 (C5h)";
CM_ BO_ 2583676670 "Proprietary B - Page 1 (C6h)";
CM_ BO_ 2583676926 "Proprietary B - Page 1 (C7h)";
CM_ BO_ 2583677182 "Proprietary B - Page 1 (C8h)";
CM_ BO_ 2583677438 "Proprietary B - Page 1 (C9h)";
CM_ BO_ 2583677694 "Proprietary B - Page 1 (CAh)";
CM_ BO_ 2583677950 "Proprietary B - Page 1 (CBh)";
CM_ BO_ 2583678206 "Proprietary B - Page 1 (CCh)";
CM_ BO_ 2583678462 "Proprietary B - Page 1 (CDh)";
CM_ BO_ 2583678718 "Proprietary B - Page 1 (CEh)";
CM_ BO_ 2583678974 "Proprietary B - Page 1 (CFh)";
CM_ BO_ 2583679230 "Proprietary B - Page 1 (D0h)";
CM_ BO_ 2583679486 "Proprietary B - Page 1 (D1h)";
CM_ BO_ 2583679742 "Proprietary B - Page 1 (D2h)";
CM_ BO_ 2583679998 "Proprietary B - Page 1 (D3h)";
CM_ BO_ 2583680254 "Proprietary B - Page 1 (D4h)";
CM_ BO_ 2583680510 "Proprietary B - Page 1 (D5h)";
CM_ BO_ 2583680766 "Proprietary B - Page 1 (D6h)";
CM_ BO_ 2583681022 "Proprietary B - Page 1 (D7h)";
CM_ BO_ 2583681278 "Proprietary B - Page 1 (D8h)";
CM_ BO_ 2583681534 "Proprietary B - Page 1 (D9h)";
CM_ BO_ 2583681790 "Proprietary B - Page 1 (DAh)";
CM_ BO_ 2583682046 "Proprietary B - Page 1 (DBh)";
CM_ BO_ 2583682302 "Proprietary B - Page 1 (DCh)";
CM_ BO_ 2583682558 "Proprietary B - Page 1 (DDh)";
CM_ BO_ 2583682814 "Proprietary B - Page 1 (DEh)";
CM_ BO_ 2583683070 "Proprietary B - Page 1 (DFh)";
CM_ BO_ 2583683326 "Proprietary B - Page 1 (E0h)";
CM_ BO_ 2583683582 "Proprietary B - Page 1 (E1h)";
CM_ BO_ 2583683838 "Proprietary B - Page 1 (E2h)";
CM_ BO_ 2583684094 "Proprietary B - Page 1 (E3h)";
CM_ BO_ 2583684350 "Proprietary B - Page 1 (E4h)";
CM_ BO_ 2583684606 "Proprietary B - Page 1 (E5h)";
CM_ BO_ 2583684862 "Proprietary B - Page 1 (E6h)";
CM_ BO_ 2583685118 "Proprietary B - Page 1 (E7h)";
CM_ BO_ 2583685374 "Proprietary B - Page 1 (E8h)";
CM_ BO_ 2583685630 "Proprietary B - Page 1 (E9h)";
CM_ BO_ 2583685886 "Proprietary B - Page 1 (EAh)";
CM_ BO_ 2583686142 "Proprietary B - Page 1 (EBh)";
CM_ BO_ 2583686398 "Proprietary B - Page 1 (ECh)";
CM_ BO_ 2583686654 "Proprietary B - Page 1 (EDh)";
CM_ BO_ 2583686910 "Proprietary B - Page 1 (EEh)";
CM_ BO_ 2583687166 "Proprietary B - Page 1 (EFh)";
CM_ BO_ 2583687422 "Proprietary B - Page 1 (F0h)";
CM_ BO_ 2583687678 "Proprietary B - Page 1 (F1h)";
CM_ BO_ 2583687934 "Proprietary B - Page 1 (F2h)";
CM_ BO_ 2583688190 "Proprietary B - Page 1 (F3h)";
CM_ BO_ 2583688446 "Proprietary B - Page 1 (F4h)";
CM_ BO_ 2583688702 "Proprietary B - Page 1 (F5h)";
CM_ BO_ 2583688958 "Proprietary B - Page 1 (F6h)";
CM_ BO_ 2583689214 "Proprietary B - Page 1 (F7h)";
CM_ BO_ 2583689470 "Proprietary B - Page 1 (F8h)";
CM_ BO_ 2583689726 "Proprietary B - Page 1 (F9h)";
CM_ BO_ 2583689982 "Proprietary B - Page 1 (FAh)";
CM_ BO_ 2583690238 "Proprietary B - Page 1 (FBh)";
CM_ BO_ 2583690494 "Proprietary B - Page 1 (FCh)";
CM_ BO_ 2583690750 "Proprietary B - Page 1 (FDh)";
CM_ BO_ 2583691006 "Proprietary B - Page 1 (FEh)";
CM_ BO_ 2583691262 "Proprietary B - Page 1 (FFh)";
BA_DEF_ BO_  "GenMsgCycleTime" INT 0 65535;
BA_DEF_ SG_  "SigType" ENUM "Default","Range","RangeSigned","ASCII","Discrete","Control","ReferencePGN","DTC","StringDelimiter","StringLength","StringLengthControl","MessageCounter","MessageChecksum";
BA_DEF_DEF_  "GenMsgCycleTime" 0;
BA_DEF_DEF_  "SigType" "Default";
BA_ "GenMsgCycleTime" BO_ 2566805246 1000;
BA_ "GenMsgCycleTime" BO_ 2365478910 100;
BA_ "GenMsgCycleTime" BO_ 2566805758 100;
BA_ "GenMsgCycleTime" BO_ 2566806014 100;
BA_ "GenMsgCycleTime" BO_ 2365479678 100;
BA_ "GenMsgCycleTime" BO_ 2566806526 100;
BA_ "GenMsgCycleTime" BO_ 2566809342 1000;
BA_ "GenMsgCycleTime" BO_ 2566809854 1000;
BA_ "GenMsgCycleTime" BO_ 2566810110 1000;
BA_ "GenMsgCycleTime" BO_ 2566810366 500;
BA_ "GenMsgCycleTime" BO_ 2365484286 50;
BA_ "GenMsgCycleTime" BO_ 2566811134 1000;
BA_ "GenMsgCycleTime" BO_ 2298375934 20;
BA_ "GenMsgCycleTime" BO_ 2432593918 100;
BA_ "GenMsgCycleTime" BO_ 2365485566 50;
BA_ "GenMsgCycleTime" BO_ 2365485822 50;
BA_ "GenMsgCycleTime" BO_ 2365486078 50;
BA_ "GenMsgCycleTime" BO_ 2365486334 50;
BA_ "GenMsgCycleTime" BO_ 2365486590 50;
BA_ "GenMsgCycleTime" BO_ 2432595710 100;
BA_ "GenMsgCycleTime" BO_ 2633927678 100;
BA_ "GenMsgCycleTime" BO_ 2566819326 1000;
BA_ "GenMsgCycleTime" BO_ 2566819838 1000;
BA_ "GenMsgCycleTime" BO_ 2633929214 1000;
BA_ "GenMsgCycleTime" BO_ 2633929470 100;
BA_ "GenMsgCycleTime" BO_ 2633929726 100;
BA_ "GenMsgCycleTime" BO_ 2566821118 500;
BA_ "GenMsgCycleTime" BO_ 2566821630 100;
BA_ "GenMsgCycleTime" BO_ 2566821886 1000;
BA_ "GenMsgCycleTime" BO_ 2566822142 1000;
BA_ "GenMsgCycleTime" BO_ 2566822398 1000;
BA_ "GenMsgCycleTime" BO_ 2566822654 1000;
BA_ "GenMsgCycleTime" BO_ 2633931774 1000;
BA_ "GenMsgCycleTime" BO_ 2566823166 1000;
BA_ "GenMsgCycleTime" BO_ 2566823422 1000;
BA_ "GenMsgCycleTime" BO_ 2566823678 1000;
BA_ "GenMsgCycleTime" BO_ 2633932798 1000;
BA_ "GenMsgCycleTime" BO_ 2566824190 1000;
BA_ "GenMsgCycleTime" BO_ 2633933310 1000;
BA_ "GenMsgCycleTime" BO_ 2633933566 1000;
BA_ "GenMsgCycleTime" BO_ 2633933822 1000;
BA_ "GenMsgCycleTime" BO_ 2566825214 1000;
BA_ "GenMsgCycleTime" BO_ 2633934334 1000;
BA_ "GenMsgCycleTime" BO_ 2566825726 500;
BA_ "GenMsgCycleTime" BO_ 2633934846 1000;
BA_ "GenMsgCycleTime" BO_ 2566827518 100;
BA_ "GenMsgCycleTime" BO_ 2566827774 1000;
BA_ "GenMsgCycleTime" BO_ 2566831614 1000;
BA_ "GenMsgCycleTime" BO_ 2566832126 100;
BA_ "GenMsgCycleTime" BO_ 2566832638 1000;
BA_ "GenMsgCycleTime" BO_ 2633941758 1000;
BA_ "GenMsgCycleTime" BO_ 2566837758 1000;
BA_ "GenMsgCycleTime" BO_ 2566838014 1000;
BA_ "GenMsgCycleTime" BO_ 2566838782 100;
BA_ "GenMsgCycleTime" BO_ 2566839294 500;
BA_ "GenMsgCycleTime" BO_ 2566839806 1000;
BA_ "GenMsgCycleTime" BO_ 2566840318 250;
BA_ "GenMsgCycleTime" BO_ 2566840574 100;
BA_ "GenMsgCycleTime" BO_ 2566840830 5000;
BA_ "GenMsgCycleTime" BO_ 2566841342 5000;
BA_ "GenMsgCycleTime" BO_ 2566841598 1000;
BA_ "GenMsgCycleTime" BO_ 2566842622 1000;
BA_ "GenMsgCycleTime" BO_ 2566844158 1000;
BA_ "GenMsgCycleTime" BO_ 2566844414 500;
BA_ "GenMsgCycleTime" BO_ 2566844670 100;
BA_ "GenMsgCycleTime" BO_ 2566844926 100;
BA_ "GenMsgCycleTime" BO_ 2566845182 100;
BA_ "GenMsgCycleTime" BO_ 2566845438 1000;
BA_ "GenMsgCycleTime" BO_ 2566845694 10000;
BA_ "GenMsgCycleTime" BO_ 2566845950 1000;
BA_ "GenMsgCycleTime" BO_ 2566846206 500;
BA_ "GenMsgCycleTime" BO_ 2566846462 1000;
BA_ "GenMsgCycleTime" BO_ 2566846718 1000;
BA_ "GenMsgCycleTime" BO_ 2566846974 1000;
BA_ "GenMsgCycleTime" BO_ 2566847230 1000;
BA_ "GenMsgCycleTime" BO_ 2566847486 1000;
BA_ "GenMsgCycleTime" BO_ 2566847742 1000;
BA_ "GenMsgCycleTime" BO_ 2566847998 500;
BA_ "GenMsgCycleTime" BO_ 2566848254 1000;
BA_ "GenMsgCycleTime" BO_ 2566848510 10000;
BA_ "SigType" SG_ 2566810622 Driver1Identification 3;
BA_ "SigType" SG_ 2566810622 Driver2Identification 3;
BA_ "SigType" SG_ 2566839038 SoftwareIdentification 3;
BA_ "SigType" SG_ 2566843646 VehicleIdentificationNumber 3;
VAL_ 2566805246 AftSlctiveCtlytcRedOprtrIndcmntA 0 "Off" 1 "On solid" 2 "reserved for SAE assignment" 3 "reserved for SAE assignment" 4 "On fast blink (1 Hz)" 5 "reserved for SAE assignment" 6 "reserved for SAE assignment" 7 "not available" ;
VAL_ 2566805246 AftrtrtmntSCROprtrIndcmntSvrty 0 "Driver Warning" 1 "Inducement Level 1" 2 "Inducement Level 2" 3 "Inducement Level 3" 4 "Inducement Level 4" 5 "Inducement Level 5" 6 "Temporary Override of Inducement" 7 "Not Available / Not Supported" ;
VAL_ 2365478910 ElctrncShockAbsrbrCtrlMdeFrntAxl 0 "Normal operation dampers passive" 1 "Normal operation dampers active" 2 "Error" 3 "Not available" ;
VAL_ 2365478910 ElctrncShockAbsrbrCtrlMdeRearAxl 0 "Normal operation dampers passive" 1 "Normal operation dampers active" 2 "Error" 3 "Not available" ;
VAL_ 2365478910 ElctrncShckAbsrbrCtrlMdeLftTgAxl 0 "Normal operation dampers passive" 1 "Normal operation dampers active" 2 "Error" 3 "Not available" ;
VAL_ 2365479678 NominalLevelFrontAxle 0 "Level not specified" 1 "Normal Level 1" 2 "Normal Level 2" 3 "Normal Level 3" 4 "Preset Level" 5 "Customer Level" 6 "Upper Level" 7 "Lower Level" 8 "Level change stopped" 9 "Raising" 10 "Lowering" 11 "Reserved" 14 "Error" 15 "Not available" ;
VAL_ 2365479678 NominalLevelRearAxle 0 "Level not specified" 1 "Normal Level 1" 2 "Normal Level 2" 3 "Normal Level 3" 4 "Preset Level" 5 "Customer Level" 6 "Upper Level" 7 "Lower Level" 8 "Level change stopped" 9 "Raising" 10 "Lowering" 11 "Reserved" 14 "Error" 15 "Not available" ;
VAL_ 2365479678 BelowNominalLevelFrontAxle 0 "Not below" 1 "Below" 2 "Error" 3 "Not available" ;
VAL_ 2365479678 BelowNominalLevelRearAxle 0 "Not below" 1 "Below" 2 "Error" 3 "Not available" ;
VAL_ 2365479678 AboveNominalLevelFrontAxle 0 "Not above" 1 "Above" 2 "Error" 3 "Not available" ;
VAL_ 2365479678 AboveNominalLevelRearAxle 0 "Not above" 1 "Above" 2 "Error" 3 "Not available" ;
VAL_ 2365479678 LoweringControlModeFrontAxle 0 "Lowering not active" 1 "Lowering active" 2 "Error" 3 "Not available" ;
VAL_ 2365479678 LoweringControlModeRearAxle 0 "Lowering not active" 1 "Lowering active" 2 "Error" 3 "Not available" ;
VAL_ 2365479678 LiftingControlModeFrontAxle 0 "Lifting not active" 1 "Lifting active" 2 "Error" 3 "Not available" ;
VAL_ 2365479678 LiftingControlModeRearAxle 0 "Lifting not active" 1 "Lifting active" 2 "Error" 3 "Not available" ;
VAL_ 2365479678 KneelingInformation 0 "Not active" 1 "Lowering active" 2 "Kneeling level reached" 3 "Lifting active" 4 "Kneeling aborted" 5 "Not defined" 14 "Error" 15 "Not available" ;
VAL_ 2365479678 LevelControlMode 0 "Normal operation" 1 "Traction help (load transfer)" 2 "Load fixing" 3 "Pressure ratio 1" 4 "Pressure ratio 2" 5 "Optimum traction 1" 6 "Optimum traction 2" 7 "Traction help" 8 "Exhausting bellow function" 9 "Air suspension control prohibited" 10 "Automatic air suspension control prohibited" 11 "Force to bumper level request is in effect" 12 "Not defined" 14 "Error" 15 "Not available" ;
VAL_ 2365479678 SecurityDevice 0 "not active" 1 "active" 2 "error" 3 "not available" ;
VAL_ 2365479678 VehicleMotionInhibit 0 "Vehicle may be moved" 1 "Vehicle motion is inhibited" 2 "Error" 3 "Not available" ;
VAL_ 2365479678 DoorRelease 0 "Doors may not be opened" 1 "Doors may be opened" 2 "Error" 3 "Not available" ;
VAL_ 2365479678 LiftAxle1Position 0 "Lift axle position down / tag axle laden" 1 "Lift axle position up / tag axle unladen" 2 "Error" 3 "Not available" ;
VAL_ 2365479678 FrontAxleInBumperRange 0 "Actual level out of bumper range" 1 "Actual level within bumper range" 2 "Error" 3 "Not available" ;
VAL_ 2365479678 RearAxleInBumperRange 0 "Actual level out of bumper range" 1 "Actual level within bumper range" 2 "Error" 3 "Not available" ;
VAL_ 2365479678 LiftAxle2Position 0 "Lift axle position down / tag axle laden" 1 "Lift axle position up / tag axle unladen" 2 "Error" 3 "Not available" ;
VAL_ 2365479678 SuspensionRemoteControl1 0 "not active" 1 "active" 2 "error" 3 "not available" ;
VAL_ 2365479678 SuspensionRemoteControl2 0 "not active" 1 "active" 2 "error" 3 "not available" ;
VAL_ 2365479678 AllowLevelCtrlDuringBrkngStatus 0 "Deactivated" 1 "Activated" 2 "Reserved" 3 "Don't care/take no action" ;
VAL_ 2365479678 SpeedDependantLevelControlStatus 0 "Inactive" 1 "Active" 2 "Reserved" 3 "Don't care/take no action" ;
VAL_ 2365479678 SuspensionCtrlRefusalInformation 0 "Actual request not refused" 1 "Axle load limit reached  (load transfer)" 2 "Would exceed axle load limit (tag axle)" 3 "Bogie differential not locked" 4 "Above speed limit" 5 "Below speed limit" 6 "General reject" 7 "Requested level not available" 8 "Not defined" 14 "Error" 15 "Not available" ;
VAL_ 2365479678 MemoryLevel 0 "No memory level" 1 "Memory level 1 selected" 2 "Memory level 2 selected" 3 "Memory level 3 selected" 4 "Memory level 4 selected" 5 "Memory level 5 selected" 6 "reserved" 7 "reserved" 8 "reserved" 9 "Memory level  1 stored" 10 "Memory level  2 stored" 11 "Memory level  3 stored" 12 "Memory level  4 stored" 13 "Memory level  5 stored" 14 "Error indicator" 15 "not available" ;
VAL_ 2566806526 LaneTrackingStatusRightSide 0 "Not Tracking Right side" 1 "Tracking Right side" 2 "Reserved" 3 "Don't Care/take no action" ;
VAL_ 2566806526 LaneTrackingStatusLeftSide 0 "Not Tracking Left side" 1 "Tracking Left side" 2 "Reserved" 3 "Don't care/Take no action" ;
VAL_ 2566806526 LaneDePrtureIndicationEnblStatus 0 "Lane Departure indication disabled" 1 "Lane Departure Indication enabled" 2 "Reserved" 3 "Not Used" ;
VAL_ 2566806526 DrvrAlertnessWarningSystemState 0 "System installed but disabled" 1 "Initializing" 2 "System temporarily not available" 3 "System available" 4 "System monitoring driver behavior" 5 "Reserved" 7 "Not Available / Not Installed" ;
VAL_ 2566806526 LeftWheelLaneDepartureDistance 251 "Greater than 125 cm / Not in range" 252 "Lane marker not reliable" 253 "Reserved" 254 "Error" 255 "Not available" ;
VAL_ 2566806526 RightWheelLaneDepartureDistance 251 "not in range" 252 "not reliable" 253 "reserved / not used" 254 "error" 255 "not available or not installed" ;
VAL_ 2566806526 LaneDepartureWarningSystemState 0 "System is not ready" 1 "System is temporarily not available" 2 "System is deactivated by driver" 3 "System is ready" 4 "Active warning suppressed by operator behavior" 5 "System is warning lane departure" 6 "Reserved" 14 "Error" 15 "Not available" ;
VAL_ 2566806526 ForwardLaneImagerStatus 0 "Imager fully operational" 1 "Imager warming up / initializing" 2 "Imager partially blocked / partially blind" 3 "Imager fully blocked / fully blind" 4 "Imager misaligned" 5 "Imager view degraded but functional" 6 "Reserved" 14 "Error" 15 "Not Available" ;
VAL_ 2566809342 BatteryMainSwitchHoldState 0 "Battery main switch not held" 1 "Battery main switch held" 2 "Reserved" 3 "Don't care/take no action" ;
VAL_ 2566809854 HydrOilFilterRestrictionSwitch 0 "No restriction" 1 "Restriction exists on oil filter" 2 "Error" 3 "Not available" ;
VAL_ 2566809854 WinchOilPressureSwitch 0 "NOT OK - Oil pressure is too low" 1 "OK - Oil pressure is above minimum" 2 "Error - Switch state cannot be determined" 3 "Not Available" ;
VAL_ 2566810366 EngineOilPrimingPumpSwitch 0 "Off" 1 "On" 2 "Error" 3 "Not available or not installed" ;
VAL_ 2566810366 EngineOilPrimingState 0 "Not sufficiently lubricated" 1 "Sufficiently lubricated" 2 "Unable to determine if sufficiently lubricated" 3 "Not available or not installed" ;
VAL_ 2566810366 EngineOilPreHeatedState 0 "Not sufficiently pre-heated" 1 "Sufficiently pre-heated" 2 "Unable to determine if engine oil is pre-heated sufficiently" 3 "Not available or not installed" ;
VAL_ 2566810366 EngineCoolantPreHeatedState 0 "Not sufficiently pre-heated" 1 "Sufficiently pre-heated" 2 "Unable to determine engine coolant pre-heated sufficiently" 3 "Not available or not installed" ;
VAL_ 2566810366 EngineVentilationStatus 0 "Sufficiently vented" 1 "Ventilation needed" 2 "Ventilation delay" 3 "Currently venting" 4 "Reserved for SAE assignment" 5 "Reserved for SAE assignment" 6 "Not able to determine if sufficiently vented" 7 "Not available or not installed" ;
VAL_ 2566810366 FuelPumpPrimerStatus 0 "Off" 1 "On" 2 "Error" 3 "Unavailable" ;
VAL_ 2566810366 EngineFuelPrimingState 0 "Not sufficiently primed" 1 "Sufficiently primed" 2 "Unable to determine if sufficiently primed" 3 "Not available or not installed" ;
VAL_ 2365484286 Driver1WorkingState 0 "Rest" 1 "Driver available" 2 "Work" 3 "Drive" 4 "Reserved" 6 "Error" 7 "Not available" ;
VAL_ 2365484286 Driver2WorkingState 0 "Rest" 1 "Driver available" 2 "Work" 3 "Drive" 4 "Reserved" 6 "Error" 7 "Not available" ;
VAL_ 2365484286 VehicleMotion 0 "Vehicle motion not detected" 1 "Vehicle motion detected" 2 "Error" 3 "Not available" ;
VAL_ 2365484286 Driver1TimeRelatedStates 0 "Normal/No limits reached" 1 "Limit #1 - 15 min before 4 ,5 h" 2 "Limit #2 - 4 ,5 h reached" 3 "Limit #3 - 15 min before 9 h" 4 "Limit #4 - 9 h reached" 5 "Limit #5 - 15 min before 16 h" 6 "Limit #6 - 16 h reached" 7 "Reserved" 13 "Other" 14 "Error" 15 "Not available" ;
VAL_ 2365484286 DriverCard_Driver1 0 "Driver card not present" 1 "Driver card present" 2 "Error" 3 "Not available" ;
VAL_ 2365484286 VehicleOverspeed 0 "No overspeed" 1 "Overspeed" 2 "Error" 3 "Not available" ;
VAL_ 2365484286 Driver2TimeRelatedStates 0 "Normal/No limits reached" 1 "Limit #1 - 15 min before 4 ,5 h" 2 "Limit #2 - 4 ,5 h reached" 3 "Limit #3 - 15 min before 9 h" 4 "Limit #4 - 9 h reached" 5 "Limit #5 - 15 min before 16 h" 6 "Limit #6 - 16 h reached" 7 "Reserved" 13 "Other" 14 "Error" 15 "Not available" ;
VAL_ 2365484286 DriverCard_Driver2 0 "Driver card not present" 1 "Driver card present" 2 "Error" 3 "Not available" ;
VAL_ 2365484286 SystemEvent 0 "No tachograph event" 1 "Tachograph event" 2 "Error" 3 "Not available" ;
VAL_ 2365484286 HandlingInformation 0 "No handling information" 1 "Handling information" 2 "Error" 3 "Not available" ;
VAL_ 2365484286 TachographPerformance 0 "Normal performance" 1 "Performance analysis" 2 "Error" 3 "Not available" ;
VAL_ 2365484286 DirectionIndicator 0 "Forward" 1 "Reverse" 2 "Error" 3 "Not Available" ;
VAL_ 2566811134 AuxiliaryHeaterMode 0 "Heater not active" 1 "Off due to ADR per European Regulations for Transport of hazardous materials" 2 "Economy mode" 3 "Normal mode" 4 "Heater pump up-keep" 5 "Heater Starting" 6 "Heater Stopping" 7 "Diagnose Active" 8 "Heater Locked" 9 "Not defined" 14 "Error" 15 "Not available" ;
VAL_ 2566811134 AuxiliaryHeaterWaterPumpStatus 0 "Water Pump is not running" 1 "Water Pump is  running" 2 "Reserved" 3 "Not available" ;
VAL_ 2566811134 CabVentilation 0 "Cab not ventilated" 1 "Cab is ventilated" 2 "Reserved" 3 "Not available" ;
VAL_ 2566811134 EngineHeatingZone 0 "Engine heating zone off" 1 "Engine heating zone on" 2 "Reserved" 3 "Not available" ;
VAL_ 2566811134 CabHeatingZone 0 "Cab heating zone off" 1 "Cab heating zone on" 2 "Reserved" 3 "Not available" ;
VAL_ 2566811134 ADRCompliantHeaterInstallation 0 "Heater installation is not ADR compliant" 1 "Heater installation is ADR compliant" 2 "Error" 3 "Not Available" ;
VAL_ 2432593918 AdaptiveCruiseControlMode 0 "Off (Standby, enabled, ready for activation)" 1 "Speed control active" 2 "Distance control active" 3 "Overtake mode" 4 "Hold mode" 5 "Finish mode" 6 "Disabled or error condition" 7 "Not available/not valid" ;
VAL_ 2432593918 AdaptiveCruiseCtrlSetDistMode 0 "ACC Distance mode #1 (largest distance)" 1 "ACC Distance mode #2" 2 "ACC Distance mode #3" 3 "ACC Distance mode #4" 4 "ACC Distance mode #5 (shortest distance)" 5 "Conventional cruise control mode" 6 "Error condition" 7 "Not available/not valid" ;
VAL_ 2432593918 ACCTargetDetected 0 "No targets detected" 1 "Target detected" 2 "Reserved" 3 "Take no action" ;
VAL_ 2432593918 ACCSystemShutoffWarning 0 "ACC SSOW Not Active" 1 "ACC SSOW Active" 2 "Reserved" 3 "Take no action" ;
VAL_ 2432593918 ACCDistanceAlertSignal 0 "ACC DAS Not Active" 1 "ACC DAS Active" 2 "Reserved" 3 "Take no action" ;
VAL_ 2432593918 ForwardCollisionWarning 0 "No warning" 1 "Collision is imminent" 2 "Error indicator" 3 "not available" ;
VAL_ 2365485566 LEDDisplayData2 1 "On-grade 'A' LED on" 2 "On-grade 'B' LED on" 4 "On-grade 'C' LED on" 8 "Up LED on" 16 "Down LED on" 32 "Left LED on" 64 "Right LED on" 128 "Low Coarse" 129 "Low Medium/Coarse" 130 "Low Medium" 131 "Low Medium/Fine" 132 "Low Fine" 144 "On Grade" 145 "High Fine" 146 "High Medium/Fine" 147 "High Medium" 148 "High Medium/Coarse" 149 "High Coarse" 159 "No data (i.e. no laser strikes)" 160 "Reserved" 254 "Error" 255 "Not Available" ;
VAL_ 2365485566 LaserTracerInformation 1 "Laser power is on" 2 "Laser is ready" 4 "Valid target (1 = yes)" 8 "Previous pass (1 = yes)" 16 "Stringline (1 = yes)" 32 "Curb (1 = yes)" ;
VAL_ 2365485822 BladeControlMode 0 "Manual mode" 1 "Automatic mode" 2 "Inactive automatic mode" ;
VAL_ 2365485822 BladeControlModeLeft 0 "Manual" 1 "Auto" 2 "Inactive Auto" 3 "Reserved" 14 "Error" 15 "Not Available" ;
VAL_ 2365485822 BladeControlModeRight 0 "Manual" 1 "Auto" 2 "Inactive Auto" 3 "Reserved" 14 "Error" 15 "Not Available" ;
VAL_ 2365485822 LandLevelingSystemEnableStatus 0 "Disabled" 1 "Enabled" 2 "Error" 3 "Not available / Not installed" ;
VAL_ 2365486334 ModifyLevelingSystemSetPoint 65025 "indicates Stop modifying the set point" 65027 "indicates Raise the current set point by 5 mm" 65041 "indicates Lower the current set point by 5 mm" 65043 "indicates Search for laser or target" 65045 "indicates go to the Park position" 65047 "indicates go to the Bench position" ;
VAL_ 2365486590 LaserReceiverType 0 "Reserved" 1 "Linear Laser Receiver" 2 "1 Meter Survey Receiver" 3 "2 Meter Survey Receiver" 4 "2.5 Meter Survey Receiver" 5 "Reserved" ;
VAL_ 2432595710 LEDDisplayData1 2 "High Coarse LED on" 4 "High Fine LED on" 8 "On-grade LED on" 16 "Low Fine LED on" 32 "Low Coarse LED on" 128 "Low Coarse" 129 "Low Medium/Coarse" 130 "Low Medium" 131 "Low Medium/Fine" 132 "Low Fine" 144 "On Grade" 145 "High Fine" 146 "High Medium/Fine" 147 "High Medium" 148 "High Medium/Coarse" 149 "High Coarse" 159 "No data (i.e. no laser strikes)" 160 "Reserved" 254 "Error" 255 "Not Available" ;
VAL_ 2432595710 LEDDisplayModeControl 0 "Center On-Grade Display Mode 1 ( 5 CHANNEL )" 1 "Offset On-Grade Display Mode" 2 "Center On-Grade Display Mode 2 ( 7 CHANNEL )" 3 "Reserved" 15 "Not Available or Not Applicable" ;
VAL_ 2432595710 LEDDisplayDeadbandControl 0 "+/- 4.5 mm (0.015 feet, 0.18 inches)" 1 "+/- 12 mm (0.040 feet, 0.45 inches)" 2 "+/- 24 mm (0.080 feet, 0.96 inches)" 3 "+/- 5 mm (0.017 feet, 0.2 inches)" 4 "+/- 1 mm (0.003 feet, 0.04 inches)" 5 "Reserved" 15 "Not Available or Not applicable" ;
VAL_ 2432595710 LEDPatternControl 0 "5 Channel" 1 "Offset" 2 "7 Channel" 3 "Reserved" 15 "Not Available" ;
VAL_ 2432595710 DisplayDeadbands 0 "Narrow = +/- 4.5mm" 1 "Standard = +/- 12mm" 2 "Wide = +/- 24mm" 3 "Reserved" 15 "Not Available" ;
VAL_ 2633922814 SteerChannelMode 0 "Maintain" 1 "Inflate" 2 "Deflate" 3 "Confirm" 4 "Inflate Wait" 5 "Deflate Wait" 6 "Pressure Check" 7 "Reserved" 14 "Error Condition" 15 "Not available" ;
VAL_ 2633922814 TrailerTagChannelMode 0 "Maintain" 1 "Inflate" 2 "Deflate" 3 "Confirm" 4 "Inflate Wait" 5 "Deflate Wait" 6 "Pressure Check" 7 "Reserved" 14 "Error Condition" 15 "Not available" ;
VAL_ 2633922814 DriveChannelMode 0 "Maintain" 1 "Inflate" 2 "Deflate" 3 "Confirm" 4 "Inflate Wait" 5 "Deflate Wait" 6 "Pressure Check" 7 "Reserved" 14 "Error Condition" 15 "Not available" ;
VAL_ 2633922814 PCUDriveSolenoidStatus 0 "Off" 1 "On" 2 "Error" 3 "Not available" ;
VAL_ 2633922814 PCUSteerSolenoidStatus 0 "Off" 1 "On" 2 "Error" 3 "Not available" ;
VAL_ 2633922814 TirePressureSupplySwitchStatus 0 "Off" 1 "On" 2 "Error" 3 "Not available" ;
VAL_ 2633922814 PCUDeflateSolenoidStatus 0 "Off" 1 "On" 2 "Error" 3 "Not available" ;
VAL_ 2633922814 PCUControlSolenoidStatus 0 "Off" 1 "On" 2 "Error" 3 "Not available" ;
VAL_ 2633922814 PCUSupplySolenoidStatus 0 "Off" 1 "On" 2 "Error" 3 "Not available" ;
VAL_ 2633922814 PCUTrailer_TagOrPushSolenoidStat 0 "Off" 1 "On" 2 "Error" 3 "Not available" ;
VAL_ 2566820094 TorqueLimitingFeatureStatus 0 "Disabled" 1 "Enabled" 2 "Error" 3 "Not available" ;
VAL_ 2566820094 EngineTorqueLimitFeature 0 "Reserved" 1 "Highest torque rating" 2 "First torque rating" 3 "Previous torque rating" 4 "Current torque rating" 5 "Reserved" 7 "Not available" ;
VAL_ 2633929214 EngineFuelLeakage1 0 "no leakage detected" 1 "leakage detected" 2 "Error" 3 "Not available" ;
VAL_ 2633929214 EngineFuelLeakage2 0 "no leakage detected" 1 "leakage detected" 2 "Error" 3 "Not available" ;
VAL_ 2633929726 SafetyWireStatus 0 "Safety wire has not been activated" 1 "Safety wire has been activated" 2 "Error" 3 "Not available" ;
VAL_ 2633929726 EngineTurningGearEngaged 0 "Not engaged" 1 "Engaged" 2 "Error" 3 "Not available" ;
VAL_ 2566821630 EngTurboWastegateActr1TempStat 0 "High Most severe" 1 "High Least severe" 2 "In Range" 3 "Low Least severe" 4 "Low Most severe" 5 "Not Defined" 6 "Error" 7 "Not available" ;
VAL_ 2633935358 EngExhstO2SensorClsdLpOperation 0 "Engine not using the exhaust oxygen sensor (open loop)" 1 "Engine using the exhaust oxygen sensor for a closed loop operation" 2 "Reserved" 3 "Don't Care/take no action" ;
VAL_ 2566827774 AirCompressorStatus 0 "Compressor not active" 1 "Compressor active" 2 "Error indicator" 3 "Not available" ;
VAL_ 2566831614 FanDriveState 0 "Fan off" 1 "Engine system-General" 2 "Excessive engine air temperature" 3 "Excessive engine oil temperature" 4 "Excessive engine coolant temperature" 5 "Excessive transmission oil temperature" 6 "Excessive hydraulic oil temperature" 7 "Default Operation" 8 "Reverse Operation" 9 "Manual control" 10 "Transmission retarder" 11 "A/C system" 12 "Timer" 13 "Engine brake" 14 "Other" 15 "Not available" ;
VAL_ 2633940734 EngineRotationDirection 0 "CounterClockWise (CCW)" 1 "ClockWise (CW)" 2 "Unknown (Rotation Direction Unknown)" 3 "Not Available" ;
VAL_ 2633940734 EngIntkManifoldPressureCtrlMode 0 "Open loop" 1 "Closed loop" 2 "SAE reserved" 3 "Not available" ;
VAL_ 2633941758 TransmissionOutputRetarder 0 "Off" 1 "On" 2 "Error" 3 "Not available" ;
VAL_ 2633942014 TransmissionHighRangeSenseSwitch 0 "Off" 1 "On" 2 "Error" 3 "Not available" ;
VAL_ 2633942014 TransmissionLowRangeSenseSwitch 0 "Off" 1 "On" 2 "Error" 3 "Not available" ;
VAL_ 2633942014 TransmissionSplitterPosition 0 "Off/Low" 1 "On/High" 2 "Error" 3 "Not Available" ;
VAL_ 2633942014 TransmissionReverseDirectionSw 0 "Off" 1 "On" 2 "Error" 3 "Not available" ;
VAL_ 2633942014 TransmissionNeutralSwitch 0 "Off" 1 "On" 2 "Error" 3 "Not available" ;
VAL_ 2633942014 TransmissionFrwdDirectionSwitch 0 "Off" 1 "On" 2 "Error" 3 "Not available" ;
VAL_ 2633943038 TrnsmShftFingerNtrlIndictr 0 "Off" 1 "On" 2 "Error" 3 "Not available" ;
VAL_ 2633943038 TrnsmShftFingerEngmntIndictr 0 "Off" 1 "On" 2 "Error" 3 "Not available" ;
VAL_ 2633943038 TrnsmShftFingerCenterRailIndictr 0 "Off" 1 "On" 2 "Error" 3 "Not available" ;
VAL_ 2633943038 TransmissionShiftFingerRailActr1 0 "Off" 1 "On" 2 "Error" 3 "Not available" ;
VAL_ 2633943038 TransmissionShiftFingerGearActr1 0 "Off" 1 "On" 2 "Error" 3 "Not available" ;
VAL_ 2633943038 TransmissionShiftFingerRailActr2 0 "Off" 1 "On" 2 "Error" 3 "Not available" ;
VAL_ 2633943038 TransmissionShiftFingerGearActr2 0 "Off" 1 "On" 2 "Error" 3 "Not available" ;
VAL_ 2633943038 TransmissionRangeHighActuator 0 "Off" 1 "On" 2 "Error" 3 "Not available" ;
VAL_ 2633943038 TransmissionRangeLowActuator 0 "Off" 1 "On" 2 "Error" 3 "Not available" ;
VAL_ 2633943038 TransmissionSplitterDirectActr 0 "Off" 1 "On" 2 "Error" 3 "Not available" ;
VAL_ 2633943038 TransmissionSplitterIndirectActr 0 "Off" 1 "On" 2 "Error" 3 "Not available" ;
VAL_ 2633943038 TransmissionClutchActuator 0 "Off" 1 "On" 2 "Error" 3 "Not available" ;
VAL_ 2633943038 TrnsmTrqCnvLockupCltchActr 0 "Off" 1 "On" 2 "Error" 3 "Not available" ;
VAL_ 2633943038 TransmissionDefuelActuator 0 "Off" 1 "On" 2 "Error" 3 "Not available" ;
VAL_ 2633943038 TransmissionInertiaBrakeActuator 0 "Off" 1 "On" 2 "Error" 3 "Not available" ;
VAL_ 2566834942 ProtectLamp 0 "Lamp Off" 1 "Lamp On" 2 "Reserved" 3 "Not available" ;
VAL_ 2566834942 AmberWarningLamp 0 "Lamp Off" 1 "Lamp On" 2 "Reserved" 3 "Not available" ;
VAL_ 2566834942 RedStopLamp 0 "Lamp Off" 1 "Lamp On" 2 "Reserved" 3 "Not available" ;
VAL_ 2566834942 MalfunctionIndicatorLamp 0 "Lamp Off" 1 "Lamp On" 2 "Short MIL for WWH OBD" 3 "Not available" ;
VAL_ 2566834942 FlashProtectLamp 0 "Slow Flash (1 Hz, 50 % duty cycle)" 1 "Fast Flash (2 Hz or faster, 50% duty cycle)" 2 "Reserved" 3 "Unavailable / Do Not Flash" ;
VAL_ 2566834942 FlashAmberWarningLamp 0 "Slow Flash (1 Hz, 50 % duty cycle)" 1 "Fast Flash (2 Hz or faster, 50% duty cycle)" 2 "Reserved" 3 "Unavailable / Do Not Flash" ;
VAL_ 2566834942 FlashRedStopLamp 0 "Slow Flash (1 Hz, 50 % duty cycle)" 1 "Fast Flash (2 Hz or faster, 50% duty cycle)" 2 "Reserved" 3 "Unavailable / Do Not Flash" ;
VAL_ 2566834942 FlashMalfunctionIndicatorLamp 0 "Slow Flash (1 Hz, 50 % duty cycle)" 1 "Fast Flash (2 Hz or faster, 50% duty cycle)" 2 "Class C DTC" 3 "Unavailable / Do Not Flash" ;
VAL_ 2566834942 SPNConversionMethod 0 "Convert SPN per Version 4" 1 "Convert SPN per Version 1, 2 or 3" ;
VAL_ 2566834942 SPNConversionMethod2 0 "Convert SPN per Version 4" 1 "Convert SPN per Version 1, 2 or 3" ;
VAL_ 2566834942 SPNConversionMethod3 0 "Convert SPN per Version 4" 1 "Convert SPN per Version 1, 2 or 3" ;
VAL_ 2566834942 SPNConversionMethod4 0 "Convert SPN per Version 4" 1 "Convert SPN per Version 1, 2 or 3" ;
VAL_ 2566834942 SPNConversionMethod5 0 "Convert SPN per Version 4" 1 "Convert SPN per Version 1, 2 or 3" ;
VAL_ 2566834942 SPNConversionMethod6 0 "Convert SPN per Version 4" 1 "Convert SPN per Version 1, 2 or 3" ;
VAL_ 2566834942 SPNConversionMethod7 0 "Convert SPN per Version 4" 1 "Convert SPN per Version 1, 2 or 3" ;
VAL_ 2566834942 SPNConversionMethod8 0 "Convert SPN per Version 4" 1 "Convert SPN per Version 1, 2 or 3" ;
VAL_ 2566834942 SPNConversionMethod9 0 "Convert SPN per Version 4" 1 "Convert SPN per Version 1, 2 or 3" ;
VAL_ 2566834942 SPNConversionMethod10 0 "Convert SPN per Version 4" 1 "Convert SPN per Version 1, 2 or 3" ;
VAL_ 2566834942 SPNConversionMethod11 0 "Convert SPN per Version 4" 1 "Convert SPN per Version 1, 2 or 3" ;
VAL_ 2566834942 SPNConversionMethod12 0 "Convert SPN per Version 4" 1 "Convert SPN per Version 1, 2 or 3" ;
VAL_ 2566835198 ProtectLamp 0 "Lamp Off" 1 "Lamp On" 2 "Reserved" 3 "Not available" ;
VAL_ 2566835198 AmberWarningLamp 0 "Lamp Off" 1 "Lamp On" 2 "Reserved" 3 "Not available" ;
VAL_ 2566835198 RedStopLamp 0 "Lamp Off" 1 "Lamp On" 2 "Reserved" 3 "Not available" ;
VAL_ 2566835198 MalfunctionIndicatorLamp 0 "Lamp Off" 1 "Lamp On" 2 "Short MIL for WWH OBD" 3 "Not available" ;
VAL_ 2566835198 FlashProtectLamp 0 "Slow Flash (1 Hz, 50 % duty cycle)" 1 "Fast Flash (2 Hz or faster, 50% duty cycle)" 2 "Reserved" 3 "Unavailable / Do Not Flash" ;
VAL_ 2566835198 FlashAmberWarningLamp 0 "Slow Flash (1 Hz, 50 % duty cycle)" 1 "Fast Flash (2 Hz or faster, 50% duty cycle)" 2 "Reserved" 3 "Unavailable / Do Not Flash" ;
VAL_ 2566835198 FlashRedStopLamp 0 "Slow Flash (1 Hz, 50 % duty cycle)" 1 "Fast Flash (2 Hz or faster, 50% duty cycle)" 2 "Reserved" 3 "Unavailable / Do Not Flash" ;
VAL_ 2566835198 FlashMalfunctionIndicatorLamp 0 "Slow Flash (1 Hz, 50 % duty cycle)" 1 "Fast Flash (2 Hz or faster, 50% duty cycle)" 2 "Class C DTC" 3 "Unavailable / Do Not Flash" ;
VAL_ 2566835198 SPNConversionMethod 0 "Convert SPN per Version 4" 1 "Convert SPN per Version 1, 2 or 3" ;
VAL_ 2566835198 SPNConversionMethod2 0 "Convert SPN per Version 4" 1 "Convert SPN per Version 1, 2 or 3" ;
VAL_ 2566835198 SPNConversionMethod3 0 "Convert SPN per Version 4" 1 "Convert SPN per Version 1, 2 or 3" ;
VAL_ 2566835198 SPNConversionMethod4 0 "Convert SPN per Version 4" 1 "Convert SPN per Version 1, 2 or 3" ;
VAL_ 2566835198 SPNConversionMethod5 0 "Convert SPN per Version 4" 1 "Convert SPN per Version 1, 2 or 3" ;
VAL_ 2566835198 SPNConversionMethod6 0 "Convert SPN per Version 4" 1 "Convert SPN per Version 1, 2 or 3" ;
VAL_ 2566835198 SPNConversionMethod7 0 "Convert SPN per Version 4" 1 "Convert SPN per Version 1, 2 or 3" ;
VAL_ 2566835198 SPNConversionMethod8 0 "Convert SPN per Version 4" 1 "Convert SPN per Version 1, 2 or 3" ;
VAL_ 2566835198 SPNConversionMethod9 0 "Convert SPN per Version 4" 1 "Convert SPN per Version 1, 2 or 3" ;
VAL_ 2566835198 SPNConversionMethod10 0 "Convert SPN per Version 4" 1 "Convert SPN per Version 1, 2 or 3" ;
VAL_ 2566835198 SPNConversionMethod11 0 "Convert SPN per Version 4" 1 "Convert SPN per Version 1, 2 or 3" ;
VAL_ 2566835198 SPNConversionMethod12 0 "Convert SPN per Version 4" 1 "Convert SPN per Version 1, 2 or 3" ;
VAL_ 2566835710 SPNConversionMethod 0 "Convert SPN per Version 4" 1 "Convert SPN per Version 1, 2 or 3" ;
VAL_ 2566836222 ProtectLamp 0 "Lamp Off" 1 "Lamp On" 2 "Reserved" 3 "Not available" ;
VAL_ 2566836222 AmberWarningLamp 0 "Lamp Off" 1 "Lamp On" 2 "Reserved" 3 "Not available" ;
VAL_ 2566836222 RedStopLamp 0 "Lamp Off" 1 "Lamp On" 2 "Reserved" 3 "Not available" ;
VAL_ 2566836222 MalfunctionIndicatorLamp 0 "Lamp Off" 1 "Lamp On" 2 "Short MIL for WWH OBD" 3 "Not available" ;
VAL_ 2566836222 FlashProtectLamp 0 "Slow Flash (1 Hz, 50 % duty cycle)" 1 "Fast Flash (2 Hz or faster, 50% duty cycle)" 2 "Reserved" 3 "Unavailable / Do Not Flash" ;
VAL_ 2566836222 FlashAmberWarningLamp 0 "Slow Flash (1 Hz, 50 % duty cycle)" 1 "Fast Flash (2 Hz or faster, 50% duty cycle)" 2 "Reserved" 3 "Unavailable / Do Not Flash" ;
VAL_ 2566836222 FlashRedStopLamp 0 "Slow Flash (1 Hz, 50 % duty cycle)" 1 "Fast Flash (2 Hz or faster, 50% duty cycle)" 2 "Reserved" 3 "Unavailable / Do Not Flash" ;
VAL_ 2566836222 FlashMalfunctionIndicatorLamp 0 "Slow Flash (1 Hz, 50 % duty cycle)" 1 "Fast Flash (2 Hz or faster, 50% duty cycle)" 2 "Class C DTC" 3 "Unavailable / Do Not Flash" ;
VAL_ 2566836222 SPNConversionMethod 0 "Convert SPN per Version 4" 1 "Convert SPN per Version 1, 2 or 3" ;
VAL_ 2566836478 TestIdentifier 0 "Reserved for SAE Assignment" 1 "Command Manufacturer Specific Test" 65 "Reserved for SAE Assignment" 245 "Return rationality fault SPN data value" 246 "Return all scaled test results for all SPNs" 247 "Return all scaled test results for one SPN" 248 "Command Manufacturer Specific Test" 249 "Command Standard Test" 250 "Return Last Measured Scaled Results" ;
VAL_ 2566837502 ProtectLamp 0 "Lamp Off" 1 "Lamp On" 2 "Reserved" 3 "Not available" ;
VAL_ 2566837502 AmberWarningLamp 0 "Lamp Off" 1 "Lamp On" 2 "Reserved" 3 "Not available" ;
VAL_ 2566837502 RedStopLamp 0 "Lamp Off" 1 "Lamp On" 2 "Reserved" 3 "Not available" ;
VAL_ 2566837502 MalfunctionIndicatorLamp 0 "Lamp Off" 1 "Lamp On" 2 "Short MIL for WWH OBD" 3 "Not available" ;
VAL_ 2566837502 FlashProtectLamp 0 "Slow Flash (1 Hz, 50 % duty cycle)" 1 "Fast Flash (2 Hz or faster, 50% duty cycle)" 2 "Reserved" 3 "Unavailable / Do Not Flash" ;
VAL_ 2566837502 FlashAmberWarningLamp 0 "Slow Flash (1 Hz, 50 % duty cycle)" 1 "Fast Flash (2 Hz or faster, 50% duty cycle)" 2 "Reserved" 3 "Unavailable / Do Not Flash" ;
VAL_ 2566837502 FlashRedStopLamp 0 "Slow Flash (1 Hz, 50 % duty cycle)" 1 "Fast Flash (2 Hz or faster, 50% duty cycle)" 2 "Reserved" 3 "Unavailable / Do Not Flash" ;
VAL_ 2566837502 FlashMalfunctionIndicatorLamp 0 "Slow Flash (1 Hz, 50 % duty cycle)" 1 "Fast Flash (2 Hz or faster, 50% duty cycle)" 2 "Class C DTC" 3 "Unavailable / Do Not Flash" ;
VAL_ 2566837502 SPNConversionMethod 0 "Convert SPN per Version 4" 1 "Convert SPN per Version 1, 2 or 3" ;
VAL_ 2566837758 Alternator1Status 0 "Alternator 1 not charging" 1 "Alternator 1 charging" 2 "error" 3 "not available" ;
VAL_ 2566837758 Alternator2Status 0 "Alternator 2 not charging" 1 "Alternator 2 charging" 2 "error" 3 "not available" ;
VAL_ 2566837758 Alternator3Status 0 "Alternator 3 not charging" 1 "Alternator 3 charging" 2 "error" 3 "not available" ;
VAL_ 2566837758 Alternator4Status 0 "Alternator 4 not charging" 1 "Alternator 4 charging" 2 "error" 3 "not available" ;
VAL_ 2566838014 HybridSystemPrtctnOverrdSwitch 0 "not active" 1 "active" 2 "error" 3 "not available" ;
VAL_ 2566838014 HybridSystemProplsnCoolntLvlSw 0 "Coolant Level is not sufficient" 1 "Coolant Level is sufficient" 2 "Error" 3 "Not Available" ;
VAL_ 2566838014 HybridSysPwrElctrncsCoolntLvlSw 0 "Coolant Level is not sufficient" 1 "Coolant Level is sufficient" 2 "Error" 3 "Not Available" ;
VAL_ 2566838014 HybridSysOffBoardChrgrConnectSt 0 "Off-board charger is not connected" 1 "Off-board charger is connected" 2 "Error" 3 "Not available" ;
VAL_ 2566838014 HybridSysRegativeBrkngDisablSw 0 "Regenerative Braking Disable Switch is off" 1 "Regenerative Braking Disable Switch is on" 2 "Error" 3 "Not Available" ;
VAL_ 2566838014 HybridSysBrkPdlRegBrkngDisblSw 0 "Brake pedal regenerative braking disable switch is off" 1 "Brake pedal regenerative braking disable switch is on" 2 "Error" 3 "Not Available" ;
VAL_ 2566838014 HybridSystemProplsnDisablSwitch 0 "Off" 1 "On" 2 "Error" 3 "Not Available" ;
VAL_ 2566838014 HybridSystemShutdownSwitch 0 "Off" 1 "On" 2 "Error" 3 "Not Available" ;
VAL_ 2566838014 PowerElectronicsCoolntFillSwitch 0 "Off" 1 "On" 2 "Error" 3 "Not available" ;
VAL_ 2566838014 PropulsionMotorCoolantFillSwitch 0 "Off" 1 "On" 2 "Error" 3 "Not available" ;
VAL_ 2566838782 AuxiliaryIO04 0 "Auxiliary channel off" 1 "Auxiliary channel on" 2 "Error" 3 "Not available" ;
VAL_ 2566838782 AuxiliaryIO03 0 "Auxiliary channel off" 1 "Auxiliary channel on" 2 "Error" 3 "Not available" ;
VAL_ 2566838782 AuxiliaryIO02 0 "Auxiliary channel off" 1 "Auxiliary channel on" 2 "Error" 3 "Not available" ;
VAL_ 2566838782 AuxiliaryIO01 0 "Auxiliary channel off" 1 "Auxiliary channel on" 2 "Error" 3 "Not available" ;
VAL_ 2566838782 AuxiliaryIO08 0 "Auxiliary channel off" 1 "Auxiliary channel on" 2 "Error" 3 "Not available" ;
VAL_ 2566838782 AuxiliaryIO07 0 "Auxiliary channel off" 1 "Auxiliary channel on" 2 "Error" 3 "Not available" ;
VAL_ 2566838782 AuxiliaryIO06 0 "Auxiliary channel off" 1 "Auxiliary channel on" 2 "Error" 3 "Not available" ;
VAL_ 2566838782 AuxiliaryIO05 0 "Auxiliary channel off" 1 "Auxiliary channel on" 2 "Error" 3 "Not available" ;
VAL_ 2566838782 AuxiliaryIO12 0 "Auxiliary channel off" 1 "Auxiliary channel on" 2 "Error" 3 "Not available" ;
VAL_ 2566838782 AuxiliaryIO11 0 "Auxiliary channel off" 1 "Auxiliary channel on" 2 "Error" 3 "Not available" ;
VAL_ 2566838782 AuxiliaryIO10 0 "Auxiliary channel off" 1 "Auxiliary channel on" 2 "Error" 3 "Not available" ;
VAL_ 2566838782 AuxiliaryIO09 0 "Auxiliary channel off" 1 "Auxiliary channel on" 2 "Error" 3 "Not available" ;
VAL_ 2566838782 AuxiliaryIO16 0 "Auxiliary channel off" 1 "Auxiliary channel on" 2 "Error" 3 "Not available" ;
VAL_ 2566838782 AuxiliaryIO15 0 "Auxiliary channel off" 1 "Auxiliary channel on" 2 "Error" 3 "Not available" ;
VAL_ 2566838782 AuxiliaryIO14 0 "Auxiliary channel off" 1 "Auxiliary channel on" 2 "Error" 3 "Not available" ;
VAL_ 2566838782 AuxiliaryIO13 0 "Auxiliary channel off" 1 "Auxiliary channel on" 2 "Error" 3 "Not available" ;
VAL_ 2566839806 EngineTurbochargerOilLevelSwitch 0 "No oil present at turbocharger" 1 "Oil present at turbocharger" 2 "Error" 3 "Not available" ;
VAL_ 2566840318 Aftertreatment1IntakeDewPoint 0 "Not exceeded the dew point" 1 "Exceeded the dew point" 2 "Error" 3 "Not available" ;
VAL_ 2566840318 Aftertreatment1ExhaustDewPoint 0 "Not exceeded the dew point" 1 "Exceeded the dew point" 2 "Error" 3 "Not available" ;
VAL_ 2566840318 Aftertreatment2IntakeDewPoint 0 "Not exceeded the dew point" 1 "Exceeded the dew point" 2 "Error" 3 "Not available" ;
VAL_ 2566840318 Aftertreatment2ExhaustDewPoint 0 "Not exceeded the dew point" 1 "Exceeded the dew point" 2 "Error" 3 "Not available" ;
VAL_ 2566840830 RetarderType 0 "Electric/Magnetic" 1 "Hydraulic" 2 "Cooled Friction" 3 "Compression Release (Engine retarder) or Combined Compression Release with Exhaust" 4 "Exhaust" 5 "Not defined" 14 "Other" 15 "Not available" ;
VAL_ 2566840830 RetarderLocation 0 "Engine Compression Release Brake" 1 "Engine Exhaust Brake" 2 "Transmission Input" 3 "Transmission Output" 4 "Driveline" 5 "Trailer" 6 "Reserved" 14 "Other" 15 "Not available" ;
VAL_ 2566840830 RetarderControlMethod 0 "Continuous control" 1 "On/Off control" ;
VAL_ 2566841342 SupportVariableRateTSC1Message 1 "1000 ms transmission rate" 2 "750 ms transmission rate" 4 "500 ms transmission rate" 8 "250 ms transmission rate" 16 "100 ms transmission rate" 32 "50 ms transmission rate" 64 "20 ms transmission rate" 128 "Reserved for SAE assignment (set to one)" ;
VAL_ 2566841598 EngIdleShutdownHasShutdownEngine 0 "No" 1 "Yes" 2 "Error" 3 "Not available" ;
VAL_ 2566841598 EngineIdleShutdownDrvrAlertMode 0 "Inactive" 1 "Active" 2 "Error" 3 "Not available" ;
VAL_ 2566841598 EngineIdleShutdownTimerOverride 0 "Inactive" 1 "Active" 2 "Error" 3 "Not available" ;
VAL_ 2566841598 EngineIdleShutdownTimerState 0 "Inactive" 1 "Active" 2 "Error" 3 "Not available" ;
VAL_ 2566841598 EngineIdleShutdownTimerFunction 0 "Disabled in calibration" 1 "Enabled in calibration" 2 "Error" 3 "Not available" ;
VAL_ 2566841598 ACHighPressureFanSwitch 0 "Pressure normal" 1 "Pressure high" 2 "Error" 3 "Not available" ;
VAL_ 2566841598 RefrigerantLowPressureSwitch 0 "Pressure normal" 1 "Pressure too low" 2 "Error" 3 "Not available" ;
VAL_ 2566841598 RefrigerantHighPressureSwitch 0 "Pressure normal" 1 "Pressure too high" 2 "Error" 3 "Not available" ;
VAL_ 2566841598 EngineWaitToStartLamp 0 "Off" 1 "On" 2 "Error" 3 "Not available" ;
VAL_ 2566841598 EngPrtctnSystemHasShutdownEng 0 "No" 1 "Yes" 2 "Error" 3 "Not available" ;
VAL_ 2566841598 EngPrtctnSystemApproachingShtdwn 0 "Not approaching" 1 "Approaching" 2 "Error" 3 "Not available" ;
VAL_ 2566841598 EngProtectionSystemTimerOverride 0 "Inactive" 1 "Active" 2 "Error" 3 "Not available" ;
VAL_ 2566841598 EngineProtectionSystemTimerState 0 "Inactive" 1 "Active" 2 "Error" 3 "Not available" ;
VAL_ 2566841598 EngineProtectionSystemConf 0 "Disabled in calibration" 1 "Enabled in calibration" 2 "Error" 3 "Not available" ;
VAL_ 2566841598 EngineAlarmAcknowledge 0 "Engine Alarm Acknowledge  Not Active" 1 "Engine Alarm Acknowledge Active" 2 "Error" 3 "Not Available" ;
VAL_ 2566841598 EngineAlarmOutputCommandStatus 0 "Engine Alarm Output Command Not Active" 1 "Engine Alarm Output Command Active" 2 "Reserved" 3 "Not Available" ;
VAL_ 2566841598 EngineAirShutoffCommandStatus 0 "Air Shutoff Disabled" 1 "Air Shutoff Enabled" 2 "Reserved" 3 "Not Available" ;
VAL_ 2566841598 EngineOverspeedTest 0 "Engine Overspeed Test Not Active" 1 "Engine Overspeed Test Active" 2 "Reserved" 3 "Not Available" ;
VAL_ 2566841598 EngineAirShutoffStatus 0 "Air flow allowed to engine" 1 "Air flow restricted" 2 "Error" 3 "Not Available" ;
VAL_ 2566841598 PTOShutdownHasShutdownEngine 0 "No" 1 "Yes" 2 "Error" 3 "Not available" ;
VAL_ 2566841598 CoolntLvlEngPrtctnShutdownStatus 0 "Disabled" 1 "Enabled" 2 "Reserved" 3 "Not Available" ;
VAL_ 2566841598 EngineOilPressureSwitch 0 "OK" 1 "Not OK" 2 "Error" 3 "Not Available" ;
VAL_ 2566843902 CruiseControlDisableCmdSupport 0 "System does not support the 'Cruise Control Disable Command'" 1 "System does support the 'Cruise Control Disable Command' feature" 2 "Reserved" 3 "Not available" ;
VAL_ 2566843902 CruiseControlResumeCmdSupport 0 "System does not support the 'Cruise Control Resume Command' feature" 1 "System does support the 'Cruise Control Resume Command' feature" 2 "Error" 3 "Not available" ;
VAL_ 2566843902 CruiseControlPauseCommandSupport 0 "System does not support the 'Cruise Control Pause Command' feature" 1 "System does support the 'Cruise Control Pause Command' feature" 2 "Error" 3 "Not available" ;
VAL_ 2566843902 CruiseControlSetCommandSupport 0 "System does not support the 'Cruise Control Set Command' feature" 1 "System does support the 'Cruise Control Set Command' feature" 2 "Error" 3 "Not available" ;
VAL_ 2566843902 PowertrainAdaptiveCruiseCtrlType 0 "Controller does not support system based cruise control Pause/Resume" 1 "Controller supports system based Cruise Control Pause/Resume commands above Cruise Control System Low Set Limit Speed (Auto Resume)" 2 "Controller supports system based Cruise Control Pause/Resume commands across all speeds but with brief operator acceleration below Cruise Control System Low Set Limit Speed (Stop and Operator Go)" 3 "Controller supports system based Cruise Control Pause/Resume commands across all speeds without operator acceleration required. (Stop and Auto Go)" 4 "Reserved" 15 "Not Available" ;
VAL_ 2566844670 EnginePTOGovernorEnableSwitch 0 "Off" 1 "On" 2 "Error" 3 "Not available" ;
VAL_ 2566844670 EngRmtPTOGvrnrPreprogrSpdCtrlSw 0 "Off" 1 "On" 2 "Error" 3 "Not available" ;
VAL_ 2566844670 EngRmtPTOGvrnrVariableSpdCtrlSw 0 "Off" 1 "On" 2 "Error" 3 "Not available" ;
VAL_ 2566844670 EnginePTOGovernorSetSwitch 0 "Off" 1 "On" 2 "Error" 3 "Not available" ;
VAL_ 2566844670 EngPTOGvrnrCoastDecelerateSwitch 0 "Off" 1 "On" 2 "Error" 3 "Not available" ;
VAL_ 2566844670 EnginePTOGovernorResumeSwitch 0 "Off" 1 "On" 2 "Error" 3 "Not available" ;
VAL_ 2566844670 EngPTOGovernorAccelerateSwitch 0 "Off" 1 "On" 2 "Error" 3 "Not available" ;
VAL_ 2566844670 OprtrEngPTOGvrnrMemorySlctSwitch 0 "PTO set speed memory 1 selected" 1 "PTO set speed memory 2 selected" 2 "error" 3 "not available" ;
VAL_ 2566844670 RmtPTOGvrnrPreprogrSpdCtrlSw2 0 "Off" 1 "On" 2 "Error" 3 "Not available" ;
VAL_ 2566844670 AuxiliaryInputIgnoreSwitch 0 "Off" 1 "On" 2 "Error" 3 "Not available" ;
VAL_ 2566844670 EnginePTOGovernorDisableSwitch 0 "Off" 1 "On" 2 "Error" 3 "Not available" ;
VAL_ 2566844926 TwoSpeedAxleSwitch 0 "Low speed range" 1 "High speed range" 2 "Error" 3 "Not available" ;
VAL_ 2566844926 ParkingBrakeSwitch 0 "Parking brake not set" 1 "Parking brake set" 2 "Error" 3 "Not available" ;
VAL_ 2566844926 CruiseControlPauseSwitch 0 "Off" 1 "On" 2 "Error Indicator" 3 "Take No Action" ;
VAL_ 2566844926 ParkBrakeReleaseInhibitRequest 0 "Park Brake Release Inhibit not requested" 1 "Park Brake Release Inhibit requested" 2 "SAE reserved" 3 "Unavailable" ;
VAL_ 2566844926 CruiseControlActive 0 "Cruise control switched off" 1 "Cruise control switched on" 2 "Error" 3 "Not available" ;
VAL_ 2566844926 CruiseControlEnableSwitch 0 "Cruise control disabled" 1 "Cruise control enabled" 2 "Error" 3 "Not available" ;
VAL_ 2566844926 BrakeSwitch 0 "Brake pedal released" 1 "Brake pedal depressed" 2 "Error" 3 "Not Available" ;
VAL_ 2566844926 ClutchSwitch 0 "Clutch pedal released" 1 "Clutch pedal depressed" 2 "Error" 3 "Not available" ;
VAL_ 2566844926 CruiseControlSetSwitch 0 "Cruise control activator not in the position 'set'" 1 "Cruise control activator in position 'set'" 2 "Error" 3 "Not available" ;
VAL_ 2566844926 CruiseControlCoastSwitch 0 "Cruise control activator not in the position 'coast'" 1 "Cruise control activator in position 'coast'" 2 "Error" 3 "Not available" ;
VAL_ 2566844926 CruiseControlResumeSwitch 0 "Cruise control activator not in the position 'resume'" 1 "Cruise control activator in position 'resume'" 2 "Error" 3 "Not available" ;
VAL_ 2566844926 CruiseControlAccelerateSwitch 0 "Cruise control activator not in the position 'accelerate'" 1 "Cruise control activator in position 'accelerate'" 2 "Error" 3 "Not available" ;
VAL_ 2566844926 PTOGovernorState 0 "Off/Disabled" 1 "Hold" 2 "Remote Hold" 3 "Standby" 4 "Remote Standby" 5 "Set" 6 "Decelerate/Coast" 7 "Resume" 8 "Accelerate" 9 "Accelerator Override" 10 "Preprogrammed set speed 1" 11 "Preprogrammed set speed 2" 12 "Preprogrammed set speed 3" 13 "Preprogrammed set speed 4" 14 "Preprogrammed set speed 5" 15 "Preprogrammed set speed 6" 16 "Preprogrammed set speed 7" 17 "Preprogrammed set speed 8" 18 "PTO set speed memory 1" 19 "PTO set speed memory 2" 20 "PTO set speed memory 3" 21 "Not defined" 31 "Not available" ;
VAL_ 2566844926 CruiseControlStates 0 "Off/Disabled" 1 "Hold" 2 "Accelerate" 3 "Decelerate" 4 "Resume" 5 "Set" 6 "Accelerator Override" 7 "Not available" ;
VAL_ 2566844926 EngineIdleIncrementSwitch 0 "Off" 1 "On" 2 "Error" 3 "Not available" ;
VAL_ 2566844926 EngineIdleDecrementSwitch 0 "Off" 1 "On" 2 "Error" 3 "Not available" ;
VAL_ 2566844926 EngineDiagnosticTestModeSwitch 0 "Off" 1 "On" 2 "Error" 3 "Not available" ;
VAL_ 2566844926 EngineShutdownOverrideSwitch 0 "Off" 1 "On" 2 "Error" 3 "Not available" ;
VAL_ 2566845694 CTIWheelSensorStatus 0 "Off / Isolated / Disabled" 1 "On (tire is polled) / Enabled" 2 "Not Defined" 3 "Not Supported" ;
VAL_ 2566845694 CTITireStatus 0 "Ok (no fault)" 1 "Tire leak detected" 2 "Error" 3 "Not Supported" ;
VAL_ 2566845694 CTIWheelEndElectricalFault 0 "Ok (No Fault)" 1 "Not Defined (Fault)" 2 "Error" 3 "Not Supported" ;
VAL_ 2566845694 ExtendedTirePressureSupport 0 "Not Using Extended Tire Pressure" 1 "Using Extended Tire Pressure" 2 "Error" 3 "Not Available/Not Supported" ;
VAL_ 2566845694 TirePressureThresholdDetection 0 "Extreme over pressure" 1 "Over pressure" 2 "No warning pressure" 3 "Under pressure" 4 "Extreme under pressure" 5 "Not defined" 6 "Error indicator" 7 "Not available" ;
VAL_ 2566846718 TransmissionOilLevel1CntdownTime 0 "less than 1 minute" 1 "One minute" 2 "Two minutes" 3 "Three minutes" 4 "Four minutes" 5 "Five minutes" 6 "Six minutes" 7 "Seven minutes" 8 "Eight minutes" 9 "Nine minutes" 10 "Ten minutes" 11 "Eleven minutes" 12 "Twelve minutes" 13 "Thirteen minutes" 14 "Error" 15 "Not Available" ;
VAL_ 2566846718 TransmissionOilLvl1MeasureStatus 0 "Conditions valid for transmission oil level measurement" 1 "Conditions not valid - Settling timer still counting down" 2 "Conditions not valid - Transmission in gear" 3 "Conditions not valid - Transmission fluid temperature too low" 4 "Conditions not valid - Transmission fluid temperature too high" 5 "Conditions not valid - Vehicle moving; output shaft speed too high" 6 "Conditions not valid - Vehicle not level" 7 "Conditions not valid - Engine speed too low" 8 "Conditions not valid - Engine speed too high" 9 "Conditions not valid - No request for reading" 10 "Not defined" 11 "Not defined" 12 "Not defined" 13 "Conditions not valid - Other" 14 "Error" 15 "Not available" ;
VAL_ 2566847230 ParkingBrakeActuator 0 "Parking brake actuator inactive" 1 "Parking brake actuator active" 2 "Error" 3 "Not available" ;
VAL_ 2566847230 ParkingBrakeRedWarningSignal 0 "Off" 1 "On" 2 "Reserved" 3 "Take no action" ;
VAL_ 2566847230 ParkBrakeReleaseInhibitStatus 0 "Park Brake release is not inhibited" 1 "Park Brake release is inhibited" 2 "Error" 3 "Unavailable" ;
VAL_ 2566847486 DrvlineRetarderOverheatIndicator 0 "Driveline Retarder Overheat Indicator is off" 1 "Driveline Retarder Overheat Indicator is on continuously" 2 "Driveline Retarder Overheat Indicator is flashing" 3 "Not available" ;
VAL_ 2566848510 WaterInFuelIndicator1 0 "No" 1 "Yes" 2 "Error" 3 "Not available" ;
VAL_ 2566848510 OperatorShiftPrompt 0 "indicator(s) inactive" 1 "upshift indicator active" 2 "downshift indicator active" 3 "don't care/take no action" ;
VAL_ 2566848510 WaterInFuelIndicator2 0 "No" 1 "Yes" 2 "Error" 3 "Not available" ;
VAL_ 2566848510 EngineOverloadedIndicator 0 "No" 1 "Yes" 2 "Error" 3 "Not available" ;
VAL_ 2566848510 DrvrWarningSystemIndicatorStatus 0 "Off" 1 "On - solid" 2 "reserved for SAE assignment" 3 "reserved for SAE assignment" 4 "On - fast blink (1 HZ)" 5 "reserved for SAE assignment" 6 "reserved for SAE assignment" 7 "not available" ;
VAL_ 2566848510 EmissionCtrlSysOprtrIndcmntSvrty 0 "Driver Warning" 1 "Inducement Level 1" 2 "Inducement Level 2" 3 "Inducement Level 3" 4 "Inducement Level 4" 5 "Inducement Level 5" 6 "Temporary Override of Inducement" 7 "Not Available / Not Supported" ;
VAL_ 2566848510 WtrChrgAirDuctAftChrgAirClIndict 0 "No" 1 "Yes" 2 "Error" 3 "Not available" ;
VAL_ 2566848510 AutoStartRequestInhibitIndicator 0 "Inactive" 1 "Active (on continuously)" 2 "Active (flashing)" 3 "Take no action" ;
